VERSION ""

NS_ :

BS_:

BU_: NUC IPC VCU ADCU Mobileye Instrumentation Vehicle ESR
VAL_TABLE_ VtSIg_eventState_9 9 "caution-Conflicting-Traffic" 8 "protected-clearance : yellow" 7 "permissive-clearance" 6 "protected-Movement-Allowed" 5 "permissive-Movement-Allowed" 4 "pre-Movement : red+yellow partly" 3 "stop-And-Remain : red right" 2 "stop-Then-Proceed : flashing red" 1 "dark" 0 "unavailable" ;
VAL_TABLE_ VtSIg_eventState_8 9 "caution-Conflicting-Traffic" 8 "protected-clearance : yellow" 7 "permissive-clearance" 6 "protected-Movement-Allowed" 5 "permissive-Movement-Allowed" 4 "pre-Movement : red+yellow partly" 3 "stop-And-Remain : red right" 2 "stop-Then-Proceed : flashing red" 1 "dark" 0 "unavailable" ;
VAL_TABLE_ VtSIg_eventState_7 9 "caution-Conflicting-Traffic" 8 "protected-clearance : yellow" 7 "permissive-clearance" 6 "protected-Movement-Allowed" 5 "permissive-Movement-Allowed" 4 "pre-Movement : red+yellow partly" 3 "stop-And-Remain : red right" 2 "stop-Then-Proceed : flashing red" 1 "dark" 0 "unavailable" ;
VAL_TABLE_ VtSIg_eventState_6 9 "caution-Conflicting-Traffic" 8 "protected-clearance : yellow" 7 "permissive-clearance" 6 "protected-Movement-Allowed" 5 "permissive-Movement-Allowed" 4 "pre-Movement : red+yellow partly" 3 "stop-And-Remain : red right" 2 "stop-Then-Proceed : flashing red" 1 "dark" 0 "unavailable" ;
VAL_TABLE_ VtSIg_eventState_5 9 "caution-Conflicting-Traffic" 8 "protected-clearance : yellow" 7 "permissive-clearance" 6 "protected-Movement-Allowed" 5 "permissive-Movement-Allowed" 4 "pre-Movement : red+yellow partly" 3 "stop-And-Remain : red right" 2 "stop-Then-Proceed : flashing red" 1 "dark" 0 "unavailable" ;
VAL_TABLE_ VtSIg_eventState_4 9 "caution-Conflicting-Traffic" 8 "protected-clearance : yellow" 7 "permissive-clearance" 6 "protected-Movement-Allowed" 5 "permissive-Movement-Allowed" 4 "pre-Movement : red+yellow partly" 3 "stop-And-Remain : red right" 2 "stop-Then-Proceed : flashing red" 1 "dark" 0 "unavailable" ;
VAL_TABLE_ VtSIg_eventState_3 9 "caution-Conflicting-Traffic" 8 "protected-clearance : yellow" 7 "permissive-clearance" 6 "protected-Movement-Allowed" 5 "permissive-Movement-Allowed" 4 "pre-Movement : red+yellow partly" 3 "stop-And-Remain : red right" 2 "stop-Then-Proceed : flashing red" 1 "dark" 0 "unavailable" ;
VAL_TABLE_ VtSIg_eventState_2 9 "caution-Conflicting-Traffic" 8 "protected-clearance : yellow" 7 "permissive-clearance" 6 "protected-Movement-Allowed" 5 "permissive-Movement-Allowed" 4 "pre-Movement : red+yellow partly" 3 "stop-And-Remain : red right" 2 "stop-Then-Proceed : flashing red" 1 "dark" 0 "unavailable" ;
VAL_TABLE_ VtSIg_eventState_1 9 "caution-Conflicting-Traffic" 8 "protected-clearance : yellow" 7 "permissive-clearance" 6 "protected-Movement-Allowed" 5 "permissive-Movement-Allowed" 4 "pre-Movement : red+yellow partly" 3 "stop-And-Remain : red right" 2 "stop-Then-Proceed : flashing red" 1 "dark" 0 "unavailable" ;
VAL_TABLE_ Value_Table_Track_Status 7 "New Coasting Target" 6 "Invalid Coasting Target" 5 "Merged Target" 4 "Coasting Target" 3 "Updated Target" 2 "New Updated Target" 1 "New Target" 0 "No Target" ;

BO_ 1831 Near_LANE_Param_2: 8 NUC
 SG_ lane_coeffd : 32|32@1- (1,0) [-3.4E+038|3.4E+038] "" Vector__XXX
 SG_ lane_coeffc : 0|32@1- (0.0001,0) [-3.4E+038|3.4E+038] "" Vector__XXX

BO_ 1830 Near_LANE_Param_1: 8 NUC
 SG_ lane_coeffb : 32|32@1- (0.0001,0) [-3.4E+038|3.4E+038] "" Vector__XXX
 SG_ lane_coeffa : 0|32@1- (0.0001,0) [-3.4E+038|3.4E+038] "" Vector__XXX

BO_ 1824 LOCAL_MAP_INFO: 8 NUC
 SG_ look_at_signalGroupID : 0|4@1+ (1,0) [0|15] "" Vector__XXX
 SG_ look_at_IntersectionID : 4|4@1+ (1,0) [0|9] "" Vector__XXX
 SG_ NEXT_LINK_ID : 8|8@1+ (1,0) [0|255] "" Vector__XXX
 SG_ LINK_ID : 16|8@1+ (1,0) [0|255] "" Vector__XXX
 SG_ distance_to_lane_end : 24|16@1+ (0.1,0) [0|6553.5] "m" Vector__XXX
 SG_ have_to_LangeChange_left : 44|1@1+ (1,0) [0|1] "" Vector__XXX
 SG_ have_to_LangeChange_right : 45|1@1+ (1,0) [0|1] "" Vector__XXX
 SG_ left_LaneChange_avail : 46|1@1+ (1,0) [0|1] "" Vector__XXX
 SG_ right_LaneChange_avail : 47|1@1+ (1,0) [0|1] "" Vector__XXX
 SG_ Speed_Limit : 48|8@1+ (1,0) [0|255] "" Vector__XXX
 SG_ guard_zone : 50|2@1+ (1,0) [0|3] "" Vector__XXX

BO_ 64 On_ODD_Stat: 2 NUC
 SG_ distance_out_of_ODD : 8|8@1+ (1,0) [0|255] "m" Vector__XXX
 SG_ Road_State : 1|2@1+ (1,0) [0|3] "" Vector__XXX
 SG_ On_ODD : 0|1@1+ (1,0) [0|1] "" Vector__XXX

BO_ 777 V2X_SPaT_9: 4 NUC
 SG_ minEndTime_9 : 16|12@1+ (0.1,0) [0|4095] "" Vector__XXX
 SG_ eventState_9 : 12|4@1+ (1,0) [0|9] "" Vector__XXX
 SG_ movementName_9 : 8|4@1+ (1,0) [0|2] "" Vector__XXX
 SG_ signalGroup_9 : 4|4@1+ (1,0) [0|15] "" Vector__XXX
 SG_ Intersection_ID_9 : 0|4@1+ (1,0) [0|9] "" Vector__XXX

BO_ 776 V2X_SPaT_8: 4 NUC
 SG_ minEndTime_8 : 16|12@1+ (0.1,0) [0|4095] "" Vector__XXX
 SG_ eventState_8 : 12|4@1+ (1,0) [0|9] "" Vector__XXX
 SG_ movementName_8 : 8|4@1+ (1,0) [0|2] "" Vector__XXX
 SG_ signalGroup_8 : 4|4@1+ (1,0) [0|15] "" Vector__XXX
 SG_ Intersection_ID_8 : 0|4@1+ (1,0) [0|9] "" Vector__XXX

BO_ 775 V2X_SPaT_7: 4 NUC
 SG_ minEndTime_7 : 16|12@1+ (0.1,0) [0|4095] "" Vector__XXX
 SG_ eventState_7 : 12|4@1+ (1,0) [0|9] "" Vector__XXX
 SG_ movementName_7 : 8|4@1+ (1,0) [0|2] "" Vector__XXX
 SG_ signalGroup_7 : 4|4@1+ (1,0) [0|15] "" Vector__XXX
 SG_ Intersection_ID_7 : 0|4@1+ (1,0) [0|9] "" Vector__XXX

BO_ 774 V2X_SPaT_6: 4 NUC
 SG_ minEndTime_6 : 16|12@1+ (0.1,0) [0|4095] "" Vector__XXX
 SG_ eventState_6 : 12|4@1+ (1,0) [0|9] "" Vector__XXX
 SG_ movementName_6 : 8|4@1+ (1,0) [0|2] "" Vector__XXX
 SG_ signalGroup_6 : 4|4@1+ (1,0) [0|15] "" Vector__XXX
 SG_ Intersection_ID_6 : 0|4@1+ (1,0) [0|9] "" Vector__XXX

BO_ 773 V2X_SPaT_5: 4 NUC
 SG_ minEndTime_5 : 16|12@1+ (0.1,0) [0|4095] "" Vector__XXX
 SG_ eventState_5 : 12|4@1+ (1,0) [0|9] "" Vector__XXX
 SG_ movementName_5 : 8|4@1+ (1,0) [0|2] "" Vector__XXX
 SG_ signalGroup_5 : 4|4@1+ (1,0) [0|15] "" Vector__XXX
 SG_ Intersection_ID_5 : 0|4@1+ (1,0) [0|9] "" Vector__XXX

BO_ 772 V2X_SPaT_4: 4 NUC
 SG_ minEndTime_4 : 16|12@1+ (0.1,0) [0|4095] "" Vector__XXX
 SG_ movementName_4 : 8|4@1+ (1,0) [0|2] "" Vector__XXX
 SG_ eventState_4 : 12|4@1+ (1,0) [0|9] "" Vector__XXX
 SG_ signalGroup_4 : 4|4@1+ (1,0) [0|15] "" Vector__XXX
 SG_ Intersection_ID_4 : 0|4@1+ (1,0) [0|9] "" Vector__XXX

BO_ 771 V2X_SPaT_3: 4 NUC
 SG_ minEndTime_3 : 16|12@1+ (0.1,0) [0|4095] "" Vector__XXX
 SG_ eventState_3 : 12|4@1+ (1,0) [0|9] "" Vector__XXX
 SG_ movementName_3 : 8|4@1+ (1,0) [0|2] "" Vector__XXX
 SG_ signalGroup_3 : 4|4@1+ (1,0) [0|15] "" Vector__XXX
 SG_ Intersection_ID_3 : 0|4@1+ (1,0) [0|9] "" Vector__XXX

BO_ 770 V2X_SPaT_2: 4 NUC
 SG_ minEndTime_2 : 16|12@1+ (0.1,0) [0|4095] "" Vector__XXX
 SG_ eventState_2 : 12|4@1+ (1,0) [0|9] "" Vector__XXX
 SG_ movementName_2 : 8|4@1+ (1,0) [0|2] "" Vector__XXX
 SG_ signalGroup_2 : 4|4@1+ (1,0) [0|15] "" Vector__XXX
 SG_ Intersection_ID_2 : 0|4@1+ (1,0) [0|9] "" Vector__XXX

BO_ 769 V2X_SPaT_1: 4 NUC
 SG_ movementName_1 : 8|4@1+ (1,0) [0|2] "" Vector__XXX
 SG_ minEndTime_1 : 16|12@1+ (0.1,0) [0|4095] "" Vector__XXX
 SG_ eventState_1 : 12|4@1+ (1,0) [0|9] "" Vector__XXX
 SG_ signalGroup_1 : 4|4@1+ (1,0) [0|15] "" Vector__XXX
 SG_ Intersection_ID_1 : 0|4@1+ (1,0) [0|9] "" Vector__XXX

BO_ 276 CPT7_Longitude_Acc: 8 IPC
 SG_ cpt7_longAcc : 0|64@1- (1,0) [-1.7E+308|1.7E+308] "m/s^2" Vector__XXX

BO_ 1897 LKA_Right_Lane_B: 4 Mobileye
 SG_ View_Range_Availability : 31|1@1+ (1,0) [0|0] "" Vector__XXX
 SG_ View_Range : 16|15@1+ (0.00390625,0) [0|127.996] "m" Vector__XXX
 SG_ Heading_Angle : 0|16@1+ (0.000976562,-31.999) [-0.357|0.357] "radians" Vector__XXX

BO_ 1896 LKA_Right_Lane_A: 8 Mobileye
 SG_ Width_left_marking : 56|8@1+ (0.01,0) [0|2.5] "m" Vector__XXX
 SG_ Curvature_Derivative : 40|16@1+ (3.72529E-009,-0.000122067) [-0.00012|0.00012] "1/meter^2" Vector__XXX
 SG_ Curvature : 24|16@1+ (9.76563E-007,-0.031999) [-0.02|0.02] "1/m" Vector__XXX
 SG_ Position : 8|16@1- (0.00390625,0) [-128|127] "m" Vector__XXX
 SG_ Model_Degree : 6|2@1+ (1,0) [0|0] "" Vector__XXX
 SG_ Quality : 4|2@1+ (1,0) [0|0] "" Vector__XXX
 SG_ Lane_Type : 0|4@1+ (1,0) [0|15] "" Vector__XXX

BO_ 275 NMEA_Heading: 8 IPC
 SG_ nmea_heading : 0|64@1- (1,0) [0|359.99] "degree" Vector__XXX

BO_ 274 NMEA_Speed: 8 IPC
 SG_ nmea_speed : 0|64@1- (1,0) [-1.7E+308|1.7E+308] "km/h" Vector__XXX

BO_ 273 NMEA_Position_Lon: 8 IPC
 SG_ nmea_longitude : 0|64@1- (1,0) [-1.7E+308|1.7E+308] "degree" Vector__XXX

BO_ 272 NMEA_Position_Lat: 8 IPC
 SG_ nmea_latitude : 0|64@1- (1,0) [-1.7E+308|1.7E+308] "degree" Vector__XXX

BO_ 262 CPT7_Position_Yawrate: 8 IPC
 SG_ cpt7_yawrate : 0|64@1- (1,0) [-1.7E+308|1.7E+308] "radian/s" Vector__XXX

BO_ 261 CPT7_Position_Azimuth: 8 IPC
 SG_ cpt7_azimuth : 0|64@1- (1,0) [-1.7E+308|1.7E+308] "degree" Vector__XXX

BO_ 260 CPT7_Position_Heading: 4 IPC
 SG_ cpt7_heading : 0|32@1- (1,0) [-3.4E+038|3.4E+038] "degree" Vector__XXX

BO_ 259 CPT7_Position_East: 8 IPC
 SG_ cpt7_easting : 0|64@1- (1,0) [-1.7E+308|1.7E+308] "m" Vector__XXX

BO_ 258 CPT7_Position_North: 8 IPC
 SG_ cpt7_northing : 0|64@1- (1,0) [-1.7E+308|1.7E+308] "m" Vector__XXX

BO_ 257 CPT7_Position_Lon: 8 IPC
 SG_ cpt7_longitude : 0|64@1- (1,0) [-1.7E+308|1.7E+308] "degree" Vector__XXX

BO_ 256 CPT7_Position_Lat: 8 IPC
 SG_ cpt7_latitude : 0|64@1- (1,0) [-1.7E+308|1.7E+308] "" Vector__XXX

BO_ 103 DiagnosticCAM: 1 IPC
 SG_ Mobileye_AliveCnt : 0|8@1+ (1,0) [0|255] "" Vector__XXX

BO_ 102 DiagnosticRADAR: 1 IPC
 SG_ Radar_AliveCnt : 0|8@1+ (1,0) [0|255] "" Vector__XXX

BO_ 101 DiagnosticHMI: 2 IPC
 SG_ HMI_AliveCnt : 8|8@1+ (1,0) [0|255] "" Vector__XXX
 SG_ HMI_StatCode : 0|8@1+ (1,0) [0|15] "" Vector__XXX

BO_ 100 DiagnosticOBU: 2 IPC
 SG_ OBU_AliveCnt : 8|8@1+ (1,0) [0|255] "" Vector__XXX
 SG_ OBU_StatCode : 0|3@1+ (1,0) [0|7] "" Vector__XXX

BO_ 99 DiagnosticGPS: 3 IPC
 SG_ GPS_IMU_AliveCnt : 16|8@1+ (1,0) [0|255] "" Vector__XXX
 SG_ IMU_StatCode : 8|3@1+ (1,0) [0|7] "" Vector__XXX
 SG_ GPS_StatCode : 0|3@1+ (1,0) [0|7] "" Vector__XXX

BO_ 98 DiagnosticLiDAR: 3 IPC
 SG_ Left_Lidar_StatCode : 16|3@1+ (1,0) [0|7] "" Vector__XXX
 SG_ Right_Lidar_StatCode : 8|3@1+ (1,0) [0|7] "" Vector__XXX
 SG_ Center_Lidar_StatCode : 0|3@1+ (1,0) [0|7] "" Vector__XXX

BO_ 96 DiagnosticIPC: 2 IPC
 SG_ IPC_SWC_StatCode : 0|3@1+ (1,0) [0|7] "" Vector__XXX
 SG_ IPC_AliveCount : 8|8@1+ (1,0) [0|255] "" Vector__XXX

BO_ 97 DiagnosticADCU: 2 ADCU
 SG_ ADCU_AliveCount : 8|8@1+ (1,0) [0|255] "-" Vector__XXX
 SG_ ADCU_SWC_StatCode : 0|3@1+ (1,0) [0|7] "" Vector__XXX

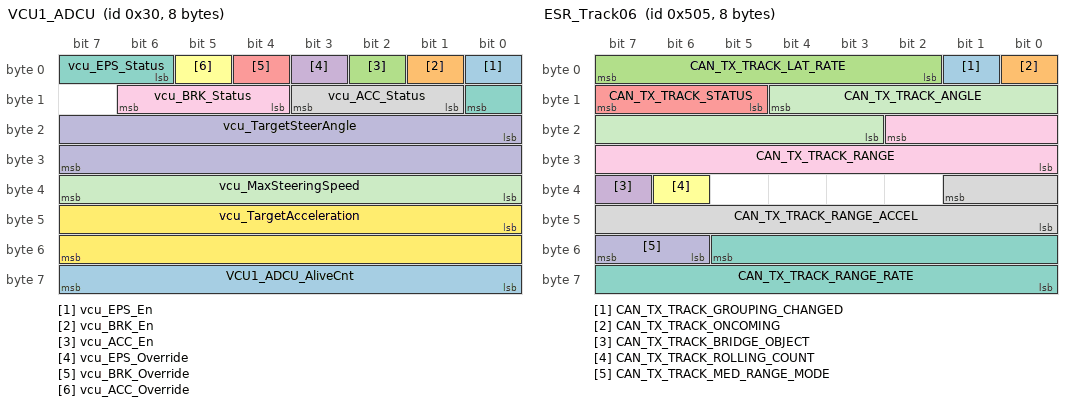
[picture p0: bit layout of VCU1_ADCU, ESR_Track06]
BO_ 48 VCU1_ADCU: 8 VCU
 SG_ vcu_EPS_En : 0|1@1+ (1,0) [0|1] "-"  ADCU
 SG_ vcu_BRK_En : 1|1@1+ (1,0) [0|1] "-"  ADCU
 SG_ vcu_ACC_En : 2|1@1+ (1,0) [0|1] "-"  ADCU
 SG_ vcu_EPS_Override : 3|1@1+ (1,0) [0|1] "-"  ADCU
 SG_ vcu_BRK_Override : 4|1@1+ (1,0) [0|1] "-"  ADCU
 SG_ vcu_ACC_Override : 5|1@1+ (1,0) [0|1] "-"  ADCU
 SG_ vcu_EPS_Status : 6|3@1+ (1,0) [0|7] "-"  ADCU
 SG_ vcu_ACC_Status : 9|3@1+ (1,0) [0|7] "-"  ADCU
 SG_ vcu_BRK_Status : 12|3@1+ (1,0) [0|7] "-"  ADCU
 SG_ vcu_TargetSteerAngle : 16|16@1- (0.1,0) [-3276.8|3276.7] "deg"  ADCU
 SG_ vcu_MaxSteeringSpeed : 32|8@1+ (4,0) [0|1016] "deg/s"  ADCU
 SG_ vcu_TargetAcceleration : 40|16@1+ (0.01,-10.23) [-10.23|10.24] "m/s^2"  ADCU
 SG_ VCU1_ADCU_AliveCnt : 56|8@1+ (1,0) [0|255] "-"  ADCU

BO_ 49 VCU2_ADCU: 8 VCU
 SG_ vcu_ADMDStatus : 0|1@1+ (1,0) [0|1] "-"  ADCU
 SG_ vcu_ADReady : 1|1@1+ (1,0) [0|1] "-"  ADCU
 SG_ vcu_Override : 2|1@1+ (1,0) [0|1] "-"  ADCU
 SG_ vcu_Estop : 3|1@1+ (1,0) [0|1] "-"  ADCU
 SG_ vcu_HazardCtl : 16|1@1+ (1,0) [0|1] "-"  ADCU
 SG_ vcu_LeftTurnCtl : 17|1@1+ (1,0) [0|1] "-"  ADCU
 SG_ vcu_RightTurnCtl : 18|1@1+ (1,0) [0|1] "-"  ADCU
 SG_ vcu_LeftTurnState : 24|1@1+ (1,0) [0|1] "-"  ADCU
 SG_ vcu_RightTurnState : 25|1@1+ (1,0) [0|1] "-"  ADCU
 SG_ vcu_VB : 32|8@1+ (0.125,0) [0|31.875] "V"  ADCU
 SG_ VCU2_ADCU_AliveCnt : 56|8@1+ (1,0) [0|255] "-"  ADCU

BO_ 50 VCU3_ADCU: 8 VCU
 SG_ vcu_APS : 0|8@1+ (0.4,0) [0|100] "%"  ADCU
 SG_ vcu_BPS : 8|8@1+ (0.4,0) [0|100] "%"  ADCU
 SG_ vcu_VS : 16|8@1+ (1,0) [0|255] "km/h"  ADCU
 SG_ vcu_SAS_Angle : 24|16@1- (0.1,0) [-3276.8|3276.7] "deg"  ADCU
 SG_ vcu_SAS_Speed : 40|8@1+ (4,0) [0|1016] "deg/s"  ADCU
 SG_ vcu_LONG_ACCEL : 48|16@1+ (0.01,-10.23) [-10.23|10.24] "m/s^2"  ADCU

BO_ 51 VCU4_ADCU: 8 VCU
 SG_ vcu_CANErr_ADCU : 0|1@1+ (1,0) [0|1] "-"  ADCU
 SG_ vcu_CANErr_LDWS : 1|1@1+ (1,0) [0|1] "-"  ADCU
 SG_ vcu_CANErr_AEB : 2|1@1+ (1,0) [0|1] "-"  ADCU
 SG_ vcu_CANErr_MDPS : 3|1@1+ (1,0) [0|1] "-"  ADCU
 SG_ vcu_CANErr_ESC : 4|1@1+ (1,0) [0|1] "-"  ADCU
 SG_ vcu_CANErr_ABS : 5|1@1+ (1,0) [0|1] "-"  ADCU
 SG_ vcu_CANErr_EMS : 6|1@1+ (1,0) [0|1] "-"  ADCU
 SG_ vcu_CANErr_BCM : 7|1@1+ (1,0) [0|1] "-"  ADCU
 SG_ vcu_CANErr_iBAU : 8|1@1+ (1,0) [0|1] "-"  ADCU
 SG_ vcu_CANErr_EPB : 9|1@1+ (1,0) [0|1] "-"  ADCU
 SG_ vcu_CANErr_CLU : 10|1@1+ (1,0) [0|1] "-"  ADCU
 SG_ vcu_CANErr_TPMS : 11|1@1+ (1,0) [0|1] "-"  ADCU
 SG_ vcu_CANErr_Autobox : 12|1@1+ (1,0) [0|1] "-"  ADCU
 SG_ vcu_CANErr_MobilEYE : 13|1@1+ (1,0) [0|1] "-"  ADCU
 SG_ vcu_CANErr_LiDAR : 14|1@1+ (1,0) [0|1] "-"  ADCU
 SG_ vcu_CANErr_Radar : 15|1@1+ (1,0) [0|1] "-"  ADCU
 SG_ vcu_CANErr_V2X : 16|1@1+ (1,0) [0|1] "-"  ADCU
 SG_ vcu_CANErr_GPS : 17|1@1+ (1,0) [0|1] "-"  ADCU
 SG_ vcu_CANErr_HMI : 18|1@1+ (1,0) [0|1] "-"  ADCU
 SG_ vcu_ERR_VCU : 32|1@1+ (1,0) [0|1] "-"  ADCU
 SG_ vcu_ERR_ADCU : 33|1@1+ (1,0) [0|1] "-"  ADCU
 SG_ vcu_ERR_LDWS : 34|1@1+ (1,0) [0|1] "-"  ADCU
 SG_ vcu_ERR_AEB : 35|1@1+ (1,0) [0|1] "-"  ADCU
 SG_ vcu_ERR_MDPS : 36|1@1+ (1,0) [0|1] "-"  ADCU
 SG_ vcu_ERR_ESC : 37|1@1+ (1,0) [0|1] "-"  ADCU
 SG_ vcu_ERR_EMS : 38|1@1+ (1,0) [0|1] "-"  ADCU
 SG_ vcu_ERR_BCM : 39|1@1+ (1,0) [0|1] "-"  ADCU
 SG_ vcu_ERR_iBAU : 40|1@1+ (1,0) [0|1] "-"  ADCU
 SG_ vcu_ERR_EPB : 41|1@1+ (1,0) [0|1] "-"  ADCU
 SG_ vcu_ERR_CLU : 42|1@1+ (1,0) [0|1] "-"  ADCU
 SG_ vcu_ERR_Autobox : 43|1@1+ (1,0) [0|1] "-"  ADCU
 SG_ vcu_ERR_MobilEYE : 44|1@1+ (1,0) [0|1] "-"  ADCU
 SG_ vcu_ERR_LiDAR : 45|1@1+ (1,0) [0|1] "-"  ADCU
 SG_ vcu_ERR_Radar : 46|1@1+ (1,0) [0|1] "-"  ADCU
 SG_ vcu_ERR_V2X : 47|1@1+ (1,0) [0|1] "-"  ADCU
 SG_ vcu_ERR_GPS : 48|1@1+ (1,0) [0|1] "-"  ADCU
 SG_ vcu_ERR_HMI : 49|1@1+ (1,0) [0|1] "-"  ADCU

BO_ 32 ADCU1: 8 ADCU
 SG_ adcu_Ready : 0|1@1+ (1,0) [0|1] "-"  VCU
 SG_ adcu_EPS_En : 1|1@1+ (1,0) [0|1] "-"  VCU
 SG_ adcu_BRK_En : 2|1@1+ (1,0) [0|1] "-"  VCU
 SG_ adcu_ACC_En : 3|1@1+ (1,0) [0|1] "-"  VCU
 SG_ adcu_SysFault : 4|1@1+ (1,0) [0|1] "-"  VCU
 SG_ adcu_DriverTakeover : 7|1@1+ (1,0) [0|1] "-"  VCU
 SG_ adcu_DriverWarning : 8|4@1+ (1,0) [0|15] "-"  VCU
 SG_ adcu_DesiredSteerAngle : 16|16@1- (0.1,0) [-3276.8|3276.7] "deg"  VCU
 SG_ adcu_MaxSteeringSpeed : 32|8@1+ (4,0) [0|1016] "deg/s"  VCU
 SG_ adcu_DesiredAcceleration : 40|16@1+ (0.01,-10.23) [-10.23|10.24] "m/s^2"  VCU
 SG_ ADCU1_AliveCnt : 56|8@1+ (1,0) [0|255] "-"  VCU

BO_ 33 ADCU2: 8 ADCU
 SG_ adcu_RunMode : 0|2@1+ (1,0) [0|3] "-"  VCU
 SG_ adcu_DrivingMode : 2|2@1+ (1,0) [0|3] "-"  VCU
 SG_ adcu_WaveLevel : 4|2@1+ (1,0) [0|3] "-"  VCU
 SG_ adcu_LTE5GLevel : 6|2@1+ (1,0) [0|3] "-"  VCU
 SG_ adcu_DesiredTimeGap : 8|16@1+ (0.01,0) [0|655.35] "sec"  VCU
 SG_ adcu_DesiredRD : 24|16@1+ (0.01,0) [0|655.35] "m"  VCU
 SG_ adcu_ActualRD : 40|16@1+ (0.01,0) [0|655.35] "m"  VCU
 SG_ ADCU2_AliveCnt : 56|8@1+ (1,0) [0|255] "-"  VCU

BO_ 34 ADCU3: 8 ADCU
 SG_ adcu_LaneDeparture : 0|2@1+ (1,0) [0|3] "-"  VCU
 SG_ adcu_VehFrt : 2|2@1+ (1,0) [0|3] "-"  VCU
 SG_ adcu_VehFL : 4|2@1+ (1,0) [0|3] "-"  VCU
 SG_ adcu_VehFR : 6|2@1+ (1,0) [0|3] "-"  VCU
 SG_ adcu_VehRL : 8|2@1+ (1,0) [0|3] "-"  VCU
 SG_ adcu_VehRR : 10|2@1+ (1,0) [0|3] "-"  VCU
 SG_ adcu_VehRear : 12|2@1+ (1,0) [0|3] "-"  VCU
 SG_ adcu_HazardLampCtl : 16|1@1+ (1,0) [0|1] "-"  VCU
 SG_ adcu_LeftTurnSigCtl : 17|1@1+ (1,0) [0|1] "-"  VCU
 SG_ adcu_RightTurnSigCtl : 18|1@1+ (1,0) [0|1] "-"  VCU
 SG_ ADCU3_AliveCnt : 56|8@1+ (1,0) [0|255] "-"  VCU

BO_ 1849 ObstacleDataA: 8 Mobileye
 SG_ ObstaclePositionX : 8|12@1+ (0.0625,0) [0|0] "m" Vector__XXX
 SG_ ObstaclePositionY : 24|10@1- (0.0625,0) [-31.93|31.93] "" Vector__XXX
 SG_ ObstacleRelSpd : 41|12@1- (0.0625,0) [-127.93|127.93] "m/s" Vector__XXX

BO_ 1850 ObstacleDataB: 8 Mobileye
 SG_ ObstacleLane : 24|2@1+ (1,0) [0|0] "" Vector__XXX

BO_ 1792 AWSDisplay: 8 Mobileye
 SG_ HeadwayMeasurement : 17|7@1+ (0.1,0) [0|0] "s" Vector__XXX

BO_ 1894 LKA_Left_Lane_A: 8 Mobileye
 SG_ Lane_Type : 0|4@1+ (1,0) [0|15] "" Vector__XXX
 SG_ Quality : 4|2@1+ (1,0) [0|0] "" Vector__XXX
 SG_ Model_Degree : 6|2@1+ (1,0) [0|0] "" Vector__XXX
 SG_ Position : 8|16@1- (0.00390625,0) [-128|127] "m" Vector__XXX
 SG_ Curvature : 24|16@1+ (9.76563E-007,-0.031999) [-0.02|0.02] "1/m" Vector__XXX
 SG_ Curvature_Derivative : 40|16@1+ (3.72529E-009,-0.000122067) [-0.00012|0.00012] "1/meter^2" Vector__XXX
 SG_ Width_left_marking : 56|8@1+ (0.01,0) [0|2.5] "m" Vector__XXX

BO_ 1895 LKA_Left_Lane_B: 4 Mobileye
 SG_ Heading_Angle : 0|16@1+ (0.000976562,-31.999) [-0.357|0.357] "radians" Vector__XXX
 SG_ View_Range : 16|15@1+ (0.00390625,0) [0|127.996] "m" Vector__XXX
 SG_ View_Range_Availability : 31|1@1+ (1,0) [0|0] "" Vector__XXX

BO_ 1512 ESR_Status9: 8 ESR
 SG_ CAN_TX_PATH_ID_ACC_3 : 63|8@0+ (1,0) [0|64] "" Vector__XXX
 SG_ CAN_TX_PATH_ID_ACC_2 : 55|8@0+ (1,0) [0|64] "" Vector__XXX
 SG_ CAN_TX_FILTERED_XOHP_ACC_CIPV : 32|9@0- (0.03125,0) [-8|7.96875] "m" Vector__XXX
 SG_ CAN_TX_WATER_SPRAY_TARGET_ID : 39|7@0+ (1,0) [0|64] "" Vector__XXX
 SG_ CAN_TX_SERIAL_NUM_3RD_BYTE : 31|8@0+ (1,0) [0|0] "" Vector__XXX
 SG_ CAN_TX_SIDESLIP_ANGLE : 9|10@0- (0.125,0) [-64|63.875] "deg" Vector__XXX
 SG_ CAN_TX_AVG_PWR_CWBLKG : 7|12@0+ (1,0) [0|0] "" Vector__XXX

BO_ 1285 ESR_Track06: 8 ESR
 SG_ CAN_TX_TRACK_GROUPING_CHANGED : 1|1@0+ (1,0) [0|0] "" Vector__XXX
 SG_ CAN_TX_TRACK_ONCOMING : 0|1@0+ (1,0) [0|0] "" Vector__XXX
 SG_ CAN_TX_TRACK_LAT_RATE : 7|6@0- (0.25,0) [-8|7.75] "" Vector__XXX
 SG_ CAN_TX_TRACK_BRIDGE_OBJECT : 39|1@0+ (1,0) [0|0] "" Vector__XXX
 SG_ CAN_TX_TRACK_STATUS : 15|3@0+ (1,0) [0|7] "" Vector__XXX
 SG_ CAN_TX_TRACK_ROLLING_COUNT : 38|1@0+ (1,0) [0|1] "" Vector__XXX
 SG_ CAN_TX_TRACK_RANGE_RATE : 53|14@0- (0.01,0) [-81.92|81.91] "m/s" Vector__XXX
 SG_ CAN_TX_TRACK_RANGE_ACCEL : 33|10@0- (0.05,0) [-25.6|25.55] "m/s/s" Vector__XXX
 SG_ CAN_TX_TRACK_RANGE : 18|11@0+ (0.1,0) [0|204.7] "m" Vector__XXX
 SG_ CAN_TX_TRACK_MED_RANGE_MODE : 55|2@0+ (1,0) [0|3] "" Vector__XXX
 SG_ CAN_TX_TRACK_ANGLE : 12|10@0- (0.1,0) [-51.2|51.1] "deg" Vector__XXX

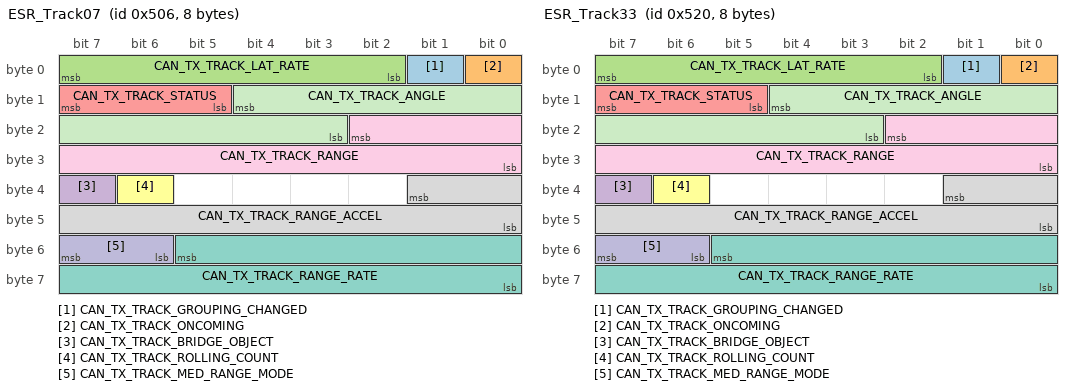
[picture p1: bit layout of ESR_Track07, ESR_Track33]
BO_ 1286 ESR_Track07: 8 ESR
 SG_ CAN_TX_TRACK_GROUPING_CHANGED : 1|1@0+ (1,0) [0|0] "" Vector__XXX
 SG_ CAN_TX_TRACK_ONCOMING : 0|1@0+ (1,0) [0|0] "" Vector__XXX
 SG_ CAN_TX_TRACK_LAT_RATE : 7|6@0- (0.25,0) [-8|7.75] "" Vector__XXX
 SG_ CAN_TX_TRACK_BRIDGE_OBJECT : 39|1@0+ (1,0) [0|0] "" Vector__XXX
 SG_ CAN_TX_TRACK_STATUS : 15|3@0+ (1,0) [0|7] "" Vector__XXX
 SG_ CAN_TX_TRACK_ROLLING_COUNT : 38|1@0+ (1,0) [0|1] "" Vector__XXX
 SG_ CAN_TX_TRACK_RANGE_RATE : 53|14@0- (0.01,0) [-81.92|81.91] "m/s" Vector__XXX
 SG_ CAN_TX_TRACK_RANGE_ACCEL : 33|10@0- (0.05,0) [-25.6|25.55] "m/s/s" Vector__XXX
 SG_ CAN_TX_TRACK_RANGE : 18|11@0+ (0.1,0) [0|204.7] "m" Vector__XXX
 SG_ CAN_TX_TRACK_MED_RANGE_MODE : 55|2@0+ (1,0) [0|3] "" Vector__XXX
 SG_ CAN_TX_TRACK_ANGLE : 12|10@0- (0.1,0) [-51.2|51.1] "deg" Vector__XXX

BO_ 1312 ESR_Track33: 8 ESR
 SG_ CAN_TX_TRACK_GROUPING_CHANGED : 1|1@0+ (1,0) [0|0] "" Vector__XXX
 SG_ CAN_TX_TRACK_ONCOMING : 0|1@0+ (1,0) [0|0] "" Vector__XXX
 SG_ CAN_TX_TRACK_LAT_RATE : 7|6@0- (0.25,0) [-8|7.75] "" Vector__XXX
 SG_ CAN_TX_TRACK_BRIDGE_OBJECT : 39|1@0+ (1,0) [0|0] "" Vector__XXX
 SG_ CAN_TX_TRACK_STATUS : 15|3@0+ (1,0) [0|7] "" Vector__XXX
 SG_ CAN_TX_TRACK_ROLLING_COUNT : 38|1@0+ (1,0) [0|1] "" Vector__XXX
 SG_ CAN_TX_TRACK_RANGE_RATE : 53|14@0- (0.01,0) [-81.92|81.91] "m/s" Vector__XXX
 SG_ CAN_TX_TRACK_RANGE_ACCEL : 33|10@0- (0.05,0) [-25.6|25.55] "m/s/s" Vector__XXX
 SG_ CAN_TX_TRACK_RANGE : 18|11@0+ (0.1,0) [0|204.7] "m" Vector__XXX
 SG_ CAN_TX_TRACK_MED_RANGE_MODE : 55|2@0+ (1,0) [0|3] "" Vector__XXX
 SG_ CAN_TX_TRACK_ANGLE : 12|10@0- (0.1,0) [-51.2|51.1] "deg" Vector__XXX

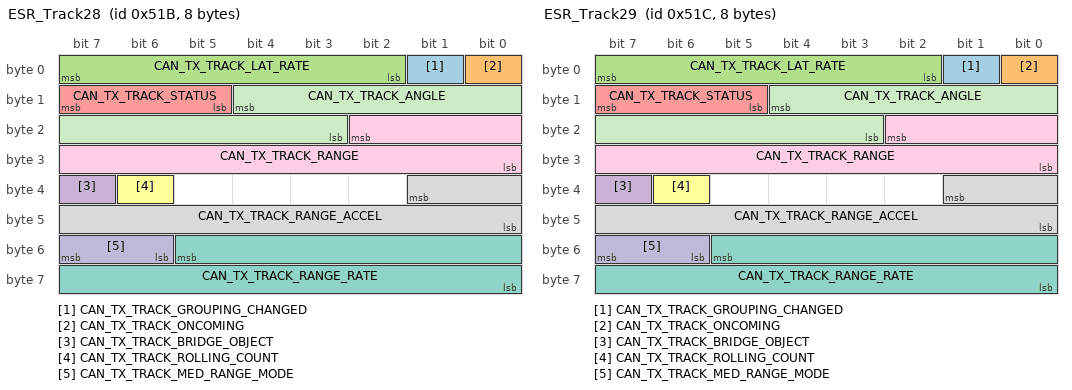
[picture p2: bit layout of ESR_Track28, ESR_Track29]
BO_ 1307 ESR_Track28: 8 ESR
 SG_ CAN_TX_TRACK_GROUPING_CHANGED : 1|1@0+ (1,0) [0|0] "" Vector__XXX
 SG_ CAN_TX_TRACK_ONCOMING : 0|1@0+ (1,0) [0|0] "" Vector__XXX
 SG_ CAN_TX_TRACK_LAT_RATE : 7|6@0- (0.25,0) [-8|7.75] "" Vector__XXX
 SG_ CAN_TX_TRACK_BRIDGE_OBJECT : 39|1@0+ (1,0) [0|0] "" Vector__XXX
 SG_ CAN_TX_TRACK_STATUS : 15|3@0+ (1,0) [0|7] "" Vector__XXX
 SG_ CAN_TX_TRACK_ROLLING_COUNT : 38|1@0+ (1,0) [0|1] "" Vector__XXX
 SG_ CAN_TX_TRACK_RANGE_RATE : 53|14@0- (0.01,0) [-81.92|81.91] "m/s" Vector__XXX
 SG_ CAN_TX_TRACK_RANGE_ACCEL : 33|10@0- (0.05,0) [-25.6|25.55] "m/s/s" Vector__XXX
 SG_ CAN_TX_TRACK_RANGE : 18|11@0+ (0.1,0) [0|204.7] "m" Vector__XXX
 SG_ CAN_TX_TRACK_MED_RANGE_MODE : 55|2@0+ (1,0) [0|3] "" Vector__XXX
 SG_ CAN_TX_TRACK_ANGLE : 12|10@0- (0.1,0) [-51.2|51.1] "deg" Vector__XXX

BO_ 1308 ESR_Track29: 8 ESR
 SG_ CAN_TX_TRACK_GROUPING_CHANGED : 1|1@0+ (1,0) [0|0] "" Vector__XXX
 SG_ CAN_TX_TRACK_ONCOMING : 0|1@0+ (1,0) [0|0] "" Vector__XXX
 SG_ CAN_TX_TRACK_LAT_RATE : 7|6@0- (0.25,0) [-8|7.75] "" Vector__XXX
 SG_ CAN_TX_TRACK_BRIDGE_OBJECT : 39|1@0+ (1,0) [0|0] "" Vector__XXX
 SG_ CAN_TX_TRACK_STATUS : 15|3@0+ (1,0) [0|7] "" Vector__XXX
 SG_ CAN_TX_TRACK_ROLLING_COUNT : 38|1@0+ (1,0) [0|1] "" Vector__XXX
 SG_ CAN_TX_TRACK_RANGE_RATE : 53|14@0- (0.01,0) [-81.92|81.91] "m/s" Vector__XXX
 SG_ CAN_TX_TRACK_RANGE_ACCEL : 33|10@0- (0.05,0) [-25.6|25.55] "m/s/s" Vector__XXX
 SG_ CAN_TX_TRACK_RANGE : 18|11@0+ (0.1,0) [0|204.7] "m" Vector__XXX
 SG_ CAN_TX_TRACK_MED_RANGE_MODE : 55|2@0+ (1,0) [0|3] "" Vector__XXX
 SG_ CAN_TX_TRACK_ANGLE : 12|10@0- (0.1,0) [-51.2|51.1] "deg" Vector__XXX

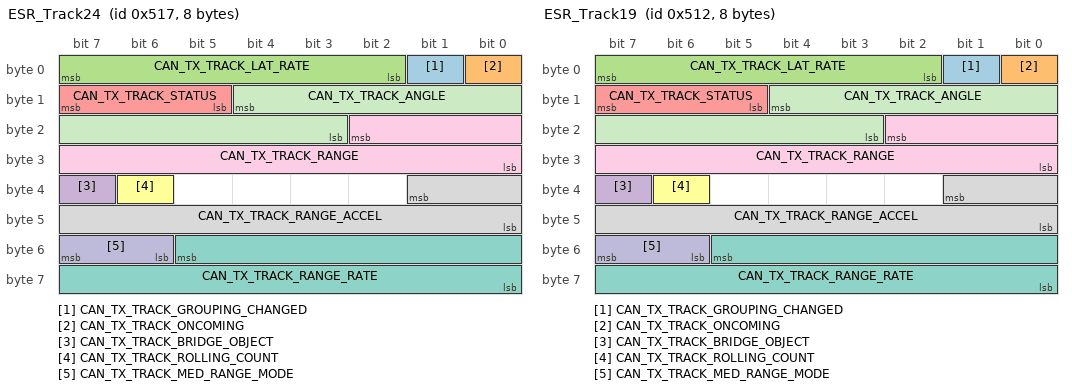
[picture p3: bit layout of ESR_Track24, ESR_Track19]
BO_ 1303 ESR_Track24: 8 ESR
 SG_ CAN_TX_TRACK_GROUPING_CHANGED : 1|1@0+ (1,0) [0|0] "" Vector__XXX
 SG_ CAN_TX_TRACK_ONCOMING : 0|1@0+ (1,0) [0|0] "" Vector__XXX
 SG_ CAN_TX_TRACK_LAT_RATE : 7|6@0- (0.25,0) [-8|7.75] "" Vector__XXX
 SG_ CAN_TX_TRACK_BRIDGE_OBJECT : 39|1@0+ (1,0) [0|0] "" Vector__XXX
 SG_ CAN_TX_TRACK_STATUS : 15|3@0+ (1,0) [0|7] "" Vector__XXX
 SG_ CAN_TX_TRACK_ROLLING_COUNT : 38|1@0+ (1,0) [0|1] "" Vector__XXX
 SG_ CAN_TX_TRACK_RANGE_RATE : 53|14@0- (0.01,0) [-81.92|81.91] "m/s" Vector__XXX
 SG_ CAN_TX_TRACK_RANGE_ACCEL : 33|10@0- (0.05,0) [-25.6|25.55] "m/s/s" Vector__XXX
 SG_ CAN_TX_TRACK_RANGE : 18|11@0+ (0.1,0) [0|204.7] "m" Vector__XXX
 SG_ CAN_TX_TRACK_MED_RANGE_MODE : 55|2@0+ (1,0) [0|3] "" Vector__XXX
 SG_ CAN_TX_TRACK_ANGLE : 12|10@0- (0.1,0) [-51.2|51.1] "deg" Vector__XXX

BO_ 1298 ESR_Track19: 8 ESR
 SG_ CAN_TX_TRACK_GROUPING_CHANGED : 1|1@0+ (1,0) [0|0] "" Vector__XXX
 SG_ CAN_TX_TRACK_ONCOMING : 0|1@0+ (1,0) [0|0] "" Vector__XXX
 SG_ CAN_TX_TRACK_LAT_RATE : 7|6@0- (0.25,0) [-8|7.75] "" Vector__XXX
 SG_ CAN_TX_TRACK_BRIDGE_OBJECT : 39|1@0+ (1,0) [0|0] "" Vector__XXX
 SG_ CAN_TX_TRACK_STATUS : 15|3@0+ (1,0) [0|7] "" Vector__XXX
 SG_ CAN_TX_TRACK_ROLLING_COUNT : 38|1@0+ (1,0) [0|1] "" Vector__XXX
 SG_ CAN_TX_TRACK_RANGE_RATE : 53|14@0- (0.01,0) [-81.92|81.91] "m/s" Vector__XXX
 SG_ CAN_TX_TRACK_RANGE_ACCEL : 33|10@0- (0.05,0) [-25.6|25.55] "m/s/s" Vector__XXX
 SG_ CAN_TX_TRACK_RANGE : 18|11@0+ (0.1,0) [0|204.7] "m" Vector__XXX
 SG_ CAN_TX_TRACK_MED_RANGE_MODE : 55|2@0+ (1,0) [0|3] "" Vector__XXX
 SG_ CAN_TX_TRACK_ANGLE : 12|10@0- (0.1,0) [-51.2|51.1] "deg" Vector__XXX

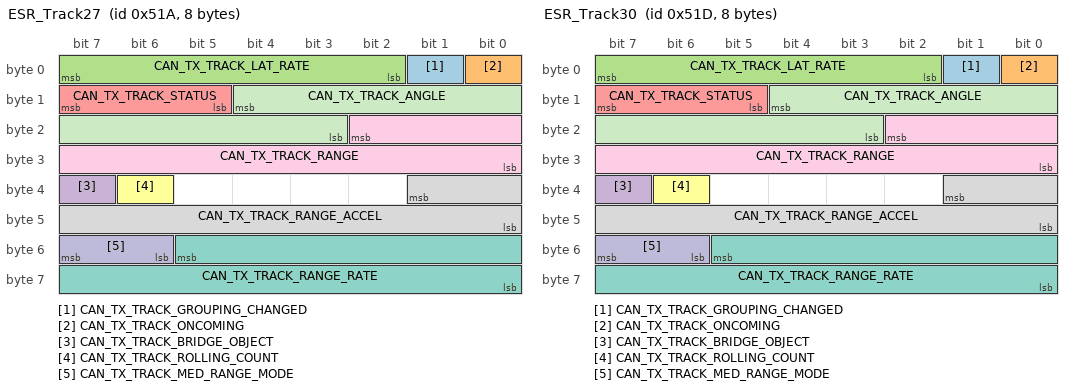
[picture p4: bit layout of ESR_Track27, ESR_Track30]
BO_ 1306 ESR_Track27: 8 ESR
 SG_ CAN_TX_TRACK_GROUPING_CHANGED : 1|1@0+ (1,0) [0|0] "" Vector__XXX
 SG_ CAN_TX_TRACK_ONCOMING : 0|1@0+ (1,0) [0|0] "" Vector__XXX
 SG_ CAN_TX_TRACK_LAT_RATE : 7|6@0- (0.25,0) [-8|7.75] "" Vector__XXX
 SG_ CAN_TX_TRACK_BRIDGE_OBJECT : 39|1@0+ (1,0) [0|0] "" Vector__XXX
 SG_ CAN_TX_TRACK_STATUS : 15|3@0+ (1,0) [0|7] "" Vector__XXX
 SG_ CAN_TX_TRACK_ROLLING_COUNT : 38|1@0+ (1,0) [0|1] "" Vector__XXX
 SG_ CAN_TX_TRACK_RANGE_RATE : 53|14@0- (0.01,0) [-81.92|81.91] "m/s" Vector__XXX
 SG_ CAN_TX_TRACK_RANGE_ACCEL : 33|10@0- (0.05,0) [-25.6|25.55] "m/s/s" Vector__XXX
 SG_ CAN_TX_TRACK_RANGE : 18|11@0+ (0.1,0) [0|204.7] "m" Vector__XXX
 SG_ CAN_TX_TRACK_MED_RANGE_MODE : 55|2@0+ (1,0) [0|3] "" Vector__XXX
 SG_ CAN_TX_TRACK_ANGLE : 12|10@0- (0.1,0) [-51.2|51.1] "deg" Vector__XXX

BO_ 1309 ESR_Track30: 8 ESR
 SG_ CAN_TX_TRACK_GROUPING_CHANGED : 1|1@0+ (1,0) [0|0] "" Vector__XXX
 SG_ CAN_TX_TRACK_ONCOMING : 0|1@0+ (1,0) [0|0] "" Vector__XXX
 SG_ CAN_TX_TRACK_LAT_RATE : 7|6@0- (0.25,0) [-8|7.75] "" Vector__XXX
 SG_ CAN_TX_TRACK_BRIDGE_OBJECT : 39|1@0+ (1,0) [0|0] "" Vector__XXX
 SG_ CAN_TX_TRACK_STATUS : 15|3@0+ (1,0) [0|7] "" Vector__XXX
 SG_ CAN_TX_TRACK_ROLLING_COUNT : 38|1@0+ (1,0) [0|1] "" Vector__XXX
 SG_ CAN_TX_TRACK_RANGE_RATE : 53|14@0- (0.01,0) [-81.92|81.91] "m/s" Vector__XXX
 SG_ CAN_TX_TRACK_RANGE_ACCEL : 33|10@0- (0.05,0) [-25.6|25.55] "m/s/s" Vector__XXX
 SG_ CAN_TX_TRACK_RANGE : 18|11@0+ (0.1,0) [0|204.7] "m" Vector__XXX
 SG_ CAN_TX_TRACK_MED_RANGE_MODE : 55|2@0+ (1,0) [0|3] "" Vector__XXX
 SG_ CAN_TX_TRACK_ANGLE : 12|10@0- (0.1,0) [-51.2|51.1] "deg" Vector__XXX

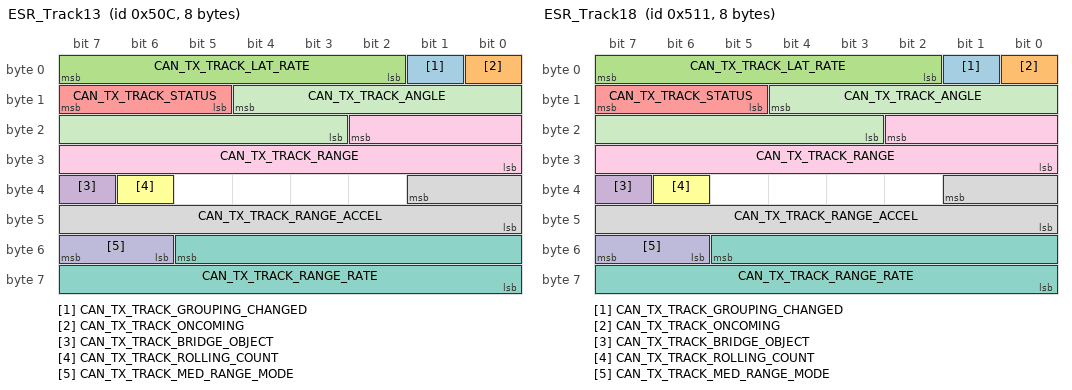
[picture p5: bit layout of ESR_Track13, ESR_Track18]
BO_ 1292 ESR_Track13: 8 ESR
 SG_ CAN_TX_TRACK_GROUPING_CHANGED : 1|1@0+ (1,0) [0|0] "" Vector__XXX
 SG_ CAN_TX_TRACK_ONCOMING : 0|1@0+ (1,0) [0|0] "" Vector__XXX
 SG_ CAN_TX_TRACK_LAT_RATE : 7|6@0- (0.25,0) [-8|7.75] "" Vector__XXX
 SG_ CAN_TX_TRACK_BRIDGE_OBJECT : 39|1@0+ (1,0) [0|0] "" Vector__XXX
 SG_ CAN_TX_TRACK_STATUS : 15|3@0+ (1,0) [0|7] "" Vector__XXX
 SG_ CAN_TX_TRACK_ROLLING_COUNT : 38|1@0+ (1,0) [0|1] "" Vector__XXX
 SG_ CAN_TX_TRACK_RANGE_RATE : 53|14@0- (0.01,0) [-81.92|81.91] "m/s" Vector__XXX
 SG_ CAN_TX_TRACK_RANGE_ACCEL : 33|10@0- (0.05,0) [-25.6|25.55] "m/s/s" Vector__XXX
 SG_ CAN_TX_TRACK_RANGE : 18|11@0+ (0.1,0) [0|204.7] "m" Vector__XXX
 SG_ CAN_TX_TRACK_MED_RANGE_MODE : 55|2@0+ (1,0) [0|3] "" Vector__XXX
 SG_ CAN_TX_TRACK_ANGLE : 12|10@0- (0.1,0) [-51.2|51.1] "deg" Vector__XXX

BO_ 1297 ESR_Track18: 8 ESR
 SG_ CAN_TX_TRACK_GROUPING_CHANGED : 1|1@0+ (1,0) [0|0] "" Vector__XXX
 SG_ CAN_TX_TRACK_ONCOMING : 0|1@0+ (1,0) [0|0] "" Vector__XXX
 SG_ CAN_TX_TRACK_LAT_RATE : 7|6@0- (0.25,0) [-8|7.75] "" Vector__XXX
 SG_ CAN_TX_TRACK_BRIDGE_OBJECT : 39|1@0+ (1,0) [0|0] "" Vector__XXX
 SG_ CAN_TX_TRACK_STATUS : 15|3@0+ (1,0) [0|7] "" Vector__XXX
 SG_ CAN_TX_TRACK_ROLLING_COUNT : 38|1@0+ (1,0) [0|1] "" Vector__XXX
 SG_ CAN_TX_TRACK_RANGE_RATE : 53|14@0- (0.01,0) [-81.92|81.91] "m/s" Vector__XXX
 SG_ CAN_TX_TRACK_RANGE_ACCEL : 33|10@0- (0.05,0) [-25.6|25.55] "m/s/s" Vector__XXX
 SG_ CAN_TX_TRACK_RANGE : 18|11@0+ (0.1,0) [0|204.7] "m" Vector__XXX
 SG_ CAN_TX_TRACK_MED_RANGE_MODE : 55|2@0+ (1,0) [0|3] "" Vector__XXX
 SG_ CAN_TX_TRACK_ANGLE : 12|10@0- (0.1,0) [-51.2|51.1] "deg" Vector__XXX

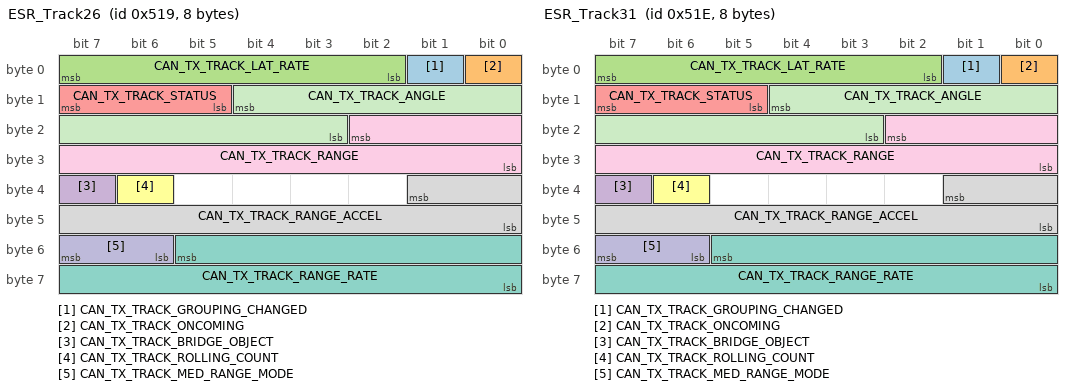
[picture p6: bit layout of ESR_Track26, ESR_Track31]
BO_ 1305 ESR_Track26: 8 ESR
 SG_ CAN_TX_TRACK_GROUPING_CHANGED : 1|1@0+ (1,0) [0|0] "" Vector__XXX
 SG_ CAN_TX_TRACK_ONCOMING : 0|1@0+ (1,0) [0|0] "" Vector__XXX
 SG_ CAN_TX_TRACK_LAT_RATE : 7|6@0- (0.25,0) [-8|7.75] "" Vector__XXX
 SG_ CAN_TX_TRACK_BRIDGE_OBJECT : 39|1@0+ (1,0) [0|0] "" Vector__XXX
 SG_ CAN_TX_TRACK_STATUS : 15|3@0+ (1,0) [0|7] "" Vector__XXX
 SG_ CAN_TX_TRACK_ROLLING_COUNT : 38|1@0+ (1,0) [0|1] "" Vector__XXX
 SG_ CAN_TX_TRACK_RANGE_RATE : 53|14@0- (0.01,0) [-81.92|81.91] "m/s" Vector__XXX
 SG_ CAN_TX_TRACK_RANGE_ACCEL : 33|10@0- (0.05,0) [-25.6|25.55] "m/s/s" Vector__XXX
 SG_ CAN_TX_TRACK_RANGE : 18|11@0+ (0.1,0) [0|204.7] "m" Vector__XXX
 SG_ CAN_TX_TRACK_MED_RANGE_MODE : 55|2@0+ (1,0) [0|3] "" Vector__XXX
 SG_ CAN_TX_TRACK_ANGLE : 12|10@0- (0.1,0) [-51.2|51.1] "deg" Vector__XXX

BO_ 1310 ESR_Track31: 8 ESR
 SG_ CAN_TX_TRACK_GROUPING_CHANGED : 1|1@0+ (1,0) [0|0] "" Vector__XXX
 SG_ CAN_TX_TRACK_ONCOMING : 0|1@0+ (1,0) [0|0] "" Vector__XXX
 SG_ CAN_TX_TRACK_LAT_RATE : 7|6@0- (0.25,0) [-8|7.75] "" Vector__XXX
 SG_ CAN_TX_TRACK_BRIDGE_OBJECT : 39|1@0+ (1,0) [0|0] "" Vector__XXX
 SG_ CAN_TX_TRACK_STATUS : 15|3@0+ (1,0) [0|7] "" Vector__XXX
 SG_ CAN_TX_TRACK_ROLLING_COUNT : 38|1@0+ (1,0) [0|1] "" Vector__XXX
 SG_ CAN_TX_TRACK_RANGE_RATE : 53|14@0- (0.01,0) [-81.92|81.91] "m/s" Vector__XXX
 SG_ CAN_TX_TRACK_RANGE_ACCEL : 33|10@0- (0.05,0) [-25.6|25.55] "m/s/s" Vector__XXX
 SG_ CAN_TX_TRACK_RANGE : 18|11@0+ (0.1,0) [0|204.7] "m" Vector__XXX
 SG_ CAN_TX_TRACK_MED_RANGE_MODE : 55|2@0+ (1,0) [0|3] "" Vector__XXX
 SG_ CAN_TX_TRACK_ANGLE : 12|10@0- (0.1,0) [-51.2|51.1] "deg" Vector__XXX

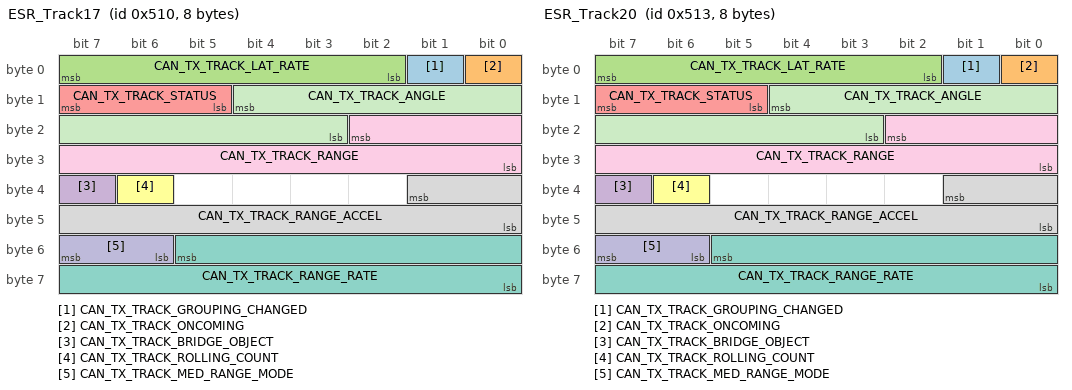
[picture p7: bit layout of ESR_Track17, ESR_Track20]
BO_ 1296 ESR_Track17: 8 ESR
 SG_ CAN_TX_TRACK_GROUPING_CHANGED : 1|1@0+ (1,0) [0|0] "" Vector__XXX
 SG_ CAN_TX_TRACK_ONCOMING : 0|1@0+ (1,0) [0|0] "" Vector__XXX
 SG_ CAN_TX_TRACK_LAT_RATE : 7|6@0- (0.25,0) [-8|7.75] "" Vector__XXX
 SG_ CAN_TX_TRACK_BRIDGE_OBJECT : 39|1@0+ (1,0) [0|0] "" Vector__XXX
 SG_ CAN_TX_TRACK_STATUS : 15|3@0+ (1,0) [0|7] "" Vector__XXX
 SG_ CAN_TX_TRACK_ROLLING_COUNT : 38|1@0+ (1,0) [0|1] "" Vector__XXX
 SG_ CAN_TX_TRACK_RANGE_RATE : 53|14@0- (0.01,0) [-81.92|81.91] "m/s" Vector__XXX
 SG_ CAN_TX_TRACK_RANGE_ACCEL : 33|10@0- (0.05,0) [-25.6|25.55] "m/s/s" Vector__XXX
 SG_ CAN_TX_TRACK_RANGE : 18|11@0+ (0.1,0) [0|204.7] "m" Vector__XXX
 SG_ CAN_TX_TRACK_MED_RANGE_MODE : 55|2@0+ (1,0) [0|3] "" Vector__XXX
 SG_ CAN_TX_TRACK_ANGLE : 12|10@0- (0.1,0) [-51.2|51.1] "deg" Vector__XXX

BO_ 1299 ESR_Track20: 8 ESR
 SG_ CAN_TX_TRACK_GROUPING_CHANGED : 1|1@0+ (1,0) [0|0] "" Vector__XXX
 SG_ CAN_TX_TRACK_ONCOMING : 0|1@0+ (1,0) [0|0] "" Vector__XXX
 SG_ CAN_TX_TRACK_LAT_RATE : 7|6@0- (0.25,0) [-8|7.75] "" Vector__XXX
 SG_ CAN_TX_TRACK_BRIDGE_OBJECT : 39|1@0+ (1,0) [0|0] "" Vector__XXX
 SG_ CAN_TX_TRACK_STATUS : 15|3@0+ (1,0) [0|7] "" Vector__XXX
 SG_ CAN_TX_TRACK_ROLLING_COUNT : 38|1@0+ (1,0) [0|1] "" Vector__XXX
 SG_ CAN_TX_TRACK_RANGE_RATE : 53|14@0- (0.01,0) [-81.92|81.91] "m/s" Vector__XXX
 SG_ CAN_TX_TRACK_RANGE_ACCEL : 33|10@0- (0.05,0) [-25.6|25.55] "m/s/s" Vector__XXX
 SG_ CAN_TX_TRACK_RANGE : 18|11@0+ (0.1,0) [0|204.7] "m" Vector__XXX
 SG_ CAN_TX_TRACK_MED_RANGE_MODE : 55|2@0+ (1,0) [0|3] "" Vector__XXX
 SG_ CAN_TX_TRACK_ANGLE : 12|10@0- (0.1,0) [-51.2|51.1] "deg" Vector__XXX

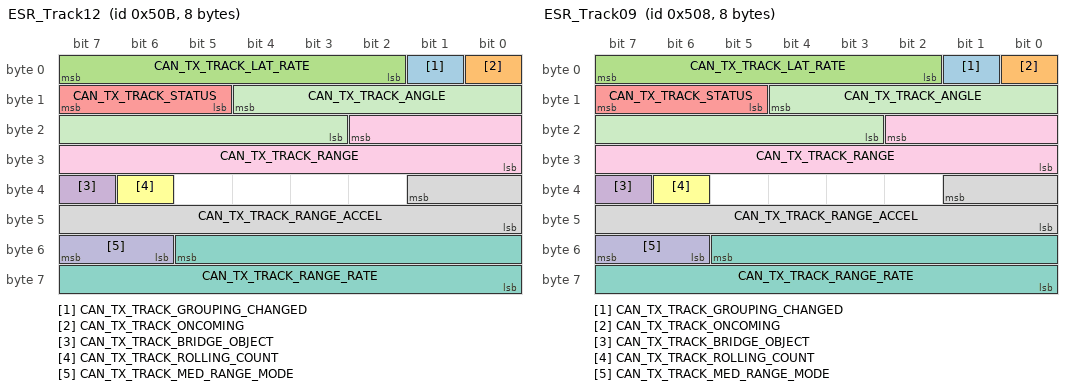
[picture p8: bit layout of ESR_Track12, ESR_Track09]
BO_ 1291 ESR_Track12: 8 ESR
 SG_ CAN_TX_TRACK_GROUPING_CHANGED : 1|1@0+ (1,0) [0|0] "" Vector__XXX
 SG_ CAN_TX_TRACK_ONCOMING : 0|1@0+ (1,0) [0|0] "" Vector__XXX
 SG_ CAN_TX_TRACK_LAT_RATE : 7|6@0- (0.25,0) [-8|7.75] "" Vector__XXX
 SG_ CAN_TX_TRACK_BRIDGE_OBJECT : 39|1@0+ (1,0) [0|0] "" Vector__XXX
 SG_ CAN_TX_TRACK_STATUS : 15|3@0+ (1,0) [0|7] "" Vector__XXX
 SG_ CAN_TX_TRACK_ROLLING_COUNT : 38|1@0+ (1,0) [0|1] "" Vector__XXX
 SG_ CAN_TX_TRACK_RANGE_RATE : 53|14@0- (0.01,0) [-81.92|81.91] "m/s" Vector__XXX
 SG_ CAN_TX_TRACK_RANGE_ACCEL : 33|10@0- (0.05,0) [-25.6|25.55] "m/s/s" Vector__XXX
 SG_ CAN_TX_TRACK_RANGE : 18|11@0+ (0.1,0) [0|204.7] "m" Vector__XXX
 SG_ CAN_TX_TRACK_MED_RANGE_MODE : 55|2@0+ (1,0) [0|3] "" Vector__XXX
 SG_ CAN_TX_TRACK_ANGLE : 12|10@0- (0.1,0) [-51.2|51.1] "deg" Vector__XXX

BO_ 1288 ESR_Track09: 8 ESR
 SG_ CAN_TX_TRACK_GROUPING_CHANGED : 1|1@0+ (1,0) [0|0] "" Vector__XXX
 SG_ CAN_TX_TRACK_ONCOMING : 0|1@0+ (1,0) [0|0] "" Vector__XXX
 SG_ CAN_TX_TRACK_LAT_RATE : 7|6@0- (0.25,0) [-8|7.75] "" Vector__XXX
 SG_ CAN_TX_TRACK_BRIDGE_OBJECT : 39|1@0+ (1,0) [0|0] "" Vector__XXX
 SG_ CAN_TX_TRACK_STATUS : 15|3@0+ (1,0) [0|7] "" Vector__XXX
 SG_ CAN_TX_TRACK_ROLLING_COUNT : 38|1@0+ (1,0) [0|1] "" Vector__XXX
 SG_ CAN_TX_TRACK_RANGE_RATE : 53|14@0- (0.01,0) [-81.92|81.91] "m/s" Vector__XXX
 SG_ CAN_TX_TRACK_RANGE_ACCEL : 33|10@0- (0.05,0) [-25.6|25.55] "m/s/s" Vector__XXX
 SG_ CAN_TX_TRACK_RANGE : 18|11@0+ (0.1,0) [0|204.7] "m" Vector__XXX
 SG_ CAN_TX_TRACK_MED_RANGE_MODE : 55|2@0+ (1,0) [0|3] "" Vector__XXX
 SG_ CAN_TX_TRACK_ANGLE : 12|10@0- (0.1,0) [-51.2|51.1] "deg" Vector__XXX

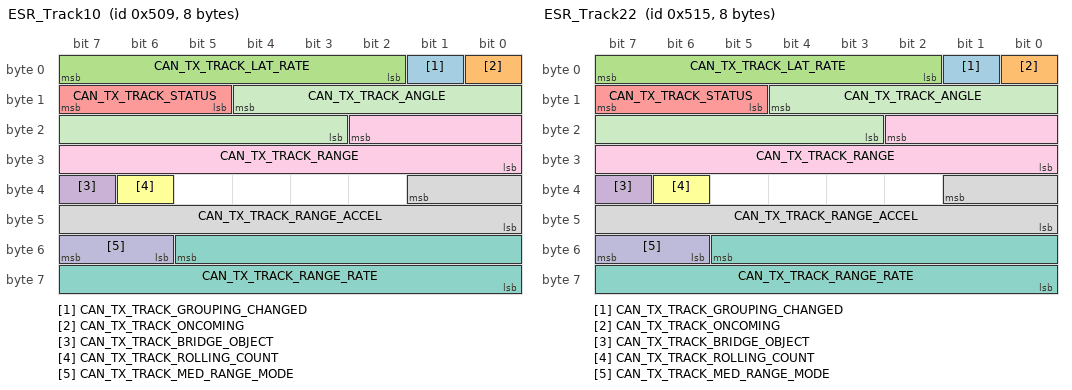
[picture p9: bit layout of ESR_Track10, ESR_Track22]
BO_ 1289 ESR_Track10: 8 ESR
 SG_ CAN_TX_TRACK_GROUPING_CHANGED : 1|1@0+ (1,0) [0|0] "" Vector__XXX
 SG_ CAN_TX_TRACK_ONCOMING : 0|1@0+ (1,0) [0|0] "" Vector__XXX
 SG_ CAN_TX_TRACK_LAT_RATE : 7|6@0- (0.25,0) [-8|7.75] "" Vector__XXX
 SG_ CAN_TX_TRACK_BRIDGE_OBJECT : 39|1@0+ (1,0) [0|0] "" Vector__XXX
 SG_ CAN_TX_TRACK_STATUS : 15|3@0+ (1,0) [0|7] "" Vector__XXX
 SG_ CAN_TX_TRACK_ROLLING_COUNT : 38|1@0+ (1,0) [0|1] "" Vector__XXX
 SG_ CAN_TX_TRACK_RANGE_RATE : 53|14@0- (0.01,0) [-81.92|81.91] "m/s" Vector__XXX
 SG_ CAN_TX_TRACK_RANGE_ACCEL : 33|10@0- (0.05,0) [-25.6|25.55] "m/s/s" Vector__XXX
 SG_ CAN_TX_TRACK_RANGE : 18|11@0+ (0.1,0) [0|204.7] "m" Vector__XXX
 SG_ CAN_TX_TRACK_MED_RANGE_MODE : 55|2@0+ (1,0) [0|3] "" Vector__XXX
 SG_ CAN_TX_TRACK_ANGLE : 12|10@0- (0.1,0) [-51.2|51.1] "deg" Vector__XXX

BO_ 1301 ESR_Track22: 8 ESR
 SG_ CAN_TX_TRACK_GROUPING_CHANGED : 1|1@0+ (1,0) [0|0] "" Vector__XXX
 SG_ CAN_TX_TRACK_ONCOMING : 0|1@0+ (1,0) [0|0] "" Vector__XXX
 SG_ CAN_TX_TRACK_LAT_RATE : 7|6@0- (0.25,0) [-8|7.75] "" Vector__XXX
 SG_ CAN_TX_TRACK_BRIDGE_OBJECT : 39|1@0+ (1,0) [0|0] "" Vector__XXX
 SG_ CAN_TX_TRACK_STATUS : 15|3@0+ (1,0) [0|7] "" Vector__XXX
 SG_ CAN_TX_TRACK_ROLLING_COUNT : 38|1@0+ (1,0) [0|1] "" Vector__XXX
 SG_ CAN_TX_TRACK_RANGE_RATE : 53|14@0- (0.01,0) [-81.92|81.91] "m/s" Vector__XXX
 SG_ CAN_TX_TRACK_RANGE_ACCEL : 33|10@0- (0.05,0) [-25.6|25.55] "m/s/s" Vector__XXX
 SG_ CAN_TX_TRACK_RANGE : 18|11@0+ (0.1,0) [0|204.7] "m" Vector__XXX
 SG_ CAN_TX_TRACK_MED_RANGE_MODE : 55|2@0+ (1,0) [0|3] "" Vector__XXX
 SG_ CAN_TX_TRACK_ANGLE : 12|10@0- (0.1,0) [-51.2|51.1] "deg" Vector__XXX

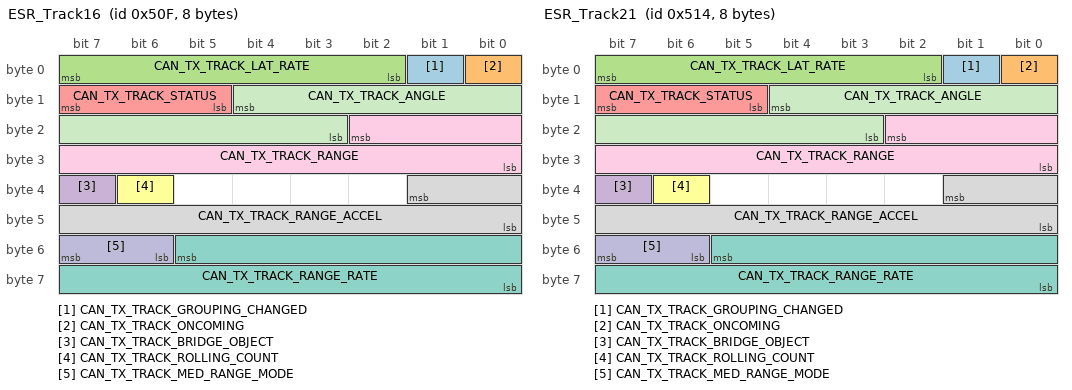
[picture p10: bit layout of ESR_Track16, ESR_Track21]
BO_ 1295 ESR_Track16: 8 ESR
 SG_ CAN_TX_TRACK_GROUPING_CHANGED : 1|1@0+ (1,0) [0|0] "" Vector__XXX
 SG_ CAN_TX_TRACK_ONCOMING : 0|1@0+ (1,0) [0|0] "" Vector__XXX
 SG_ CAN_TX_TRACK_LAT_RATE : 7|6@0- (0.25,0) [-8|7.75] "" Vector__XXX
 SG_ CAN_TX_TRACK_BRIDGE_OBJECT : 39|1@0+ (1,0) [0|0] "" Vector__XXX
 SG_ CAN_TX_TRACK_STATUS : 15|3@0+ (1,0) [0|7] "" Vector__XXX
 SG_ CAN_TX_TRACK_ROLLING_COUNT : 38|1@0+ (1,0) [0|1] "" Vector__XXX
 SG_ CAN_TX_TRACK_RANGE_RATE : 53|14@0- (0.01,0) [-81.92|81.91] "m/s" Vector__XXX
 SG_ CAN_TX_TRACK_RANGE_ACCEL : 33|10@0- (0.05,0) [-25.6|25.55] "m/s/s" Vector__XXX
 SG_ CAN_TX_TRACK_RANGE : 18|11@0+ (0.1,0) [0|204.7] "m" Vector__XXX
 SG_ CAN_TX_TRACK_MED_RANGE_MODE : 55|2@0+ (1,0) [0|3] "" Vector__XXX
 SG_ CAN_TX_TRACK_ANGLE : 12|10@0- (0.1,0) [-51.2|51.1] "deg" Vector__XXX

BO_ 1300 ESR_Track21: 8 ESR
 SG_ CAN_TX_TRACK_GROUPING_CHANGED : 1|1@0+ (1,0) [0|0] "" Vector__XXX
 SG_ CAN_TX_TRACK_ONCOMING : 0|1@0+ (1,0) [0|0] "" Vector__XXX
 SG_ CAN_TX_TRACK_LAT_RATE : 7|6@0- (0.25,0) [-8|7.75] "" Vector__XXX
 SG_ CAN_TX_TRACK_BRIDGE_OBJECT : 39|1@0+ (1,0) [0|0] "" Vector__XXX
 SG_ CAN_TX_TRACK_STATUS : 15|3@0+ (1,0) [0|7] "" Vector__XXX
 SG_ CAN_TX_TRACK_ROLLING_COUNT : 38|1@0+ (1,0) [0|1] "" Vector__XXX
 SG_ CAN_TX_TRACK_RANGE_RATE : 53|14@0- (0.01,0) [-81.92|81.91] "m/s" Vector__XXX
 SG_ CAN_TX_TRACK_RANGE_ACCEL : 33|10@0- (0.05,0) [-25.6|25.55] "m/s/s" Vector__XXX
 SG_ CAN_TX_TRACK_RANGE : 18|11@0+ (0.1,0) [0|204.7] "m" Vector__XXX
 SG_ CAN_TX_TRACK_MED_RANGE_MODE : 55|2@0+ (1,0) [0|3] "" Vector__XXX
 SG_ CAN_TX_TRACK_ANGLE : 12|10@0- (0.1,0) [-51.2|51.1] "deg" Vector__XXX

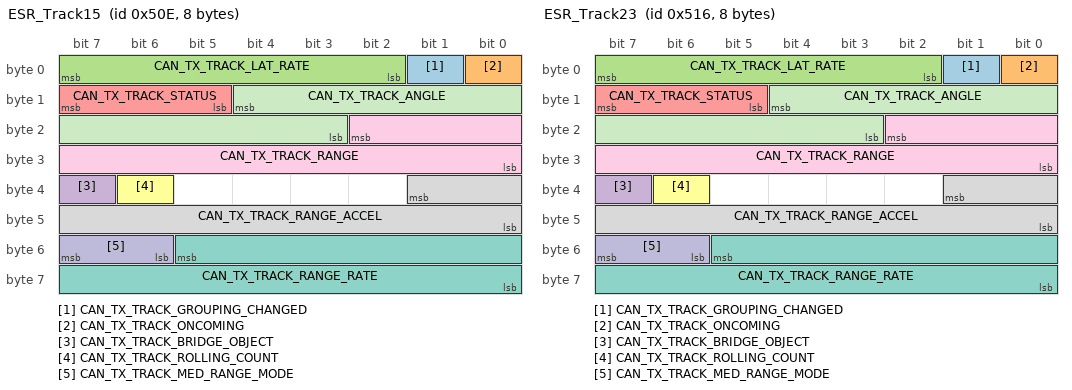
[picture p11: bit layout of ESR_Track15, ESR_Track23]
BO_ 1294 ESR_Track15: 8 ESR
 SG_ CAN_TX_TRACK_GROUPING_CHANGED : 1|1@0+ (1,0) [0|0] "" Vector__XXX
 SG_ CAN_TX_TRACK_ONCOMING : 0|1@0+ (1,0) [0|0] "" Vector__XXX
 SG_ CAN_TX_TRACK_LAT_RATE : 7|6@0- (0.25,0) [-8|7.75] "" Vector__XXX
 SG_ CAN_TX_TRACK_BRIDGE_OBJECT : 39|1@0+ (1,0) [0|0] "" Vector__XXX
 SG_ CAN_TX_TRACK_STATUS : 15|3@0+ (1,0) [0|7] "" Vector__XXX
 SG_ CAN_TX_TRACK_ROLLING_COUNT : 38|1@0+ (1,0) [0|1] "" Vector__XXX
 SG_ CAN_TX_TRACK_RANGE_RATE : 53|14@0- (0.01,0) [-81.92|81.91] "m/s" Vector__XXX
 SG_ CAN_TX_TRACK_RANGE_ACCEL : 33|10@0- (0.05,0) [-25.6|25.55] "m/s/s" Vector__XXX
 SG_ CAN_TX_TRACK_RANGE : 18|11@0+ (0.1,0) [0|204.7] "m" Vector__XXX
 SG_ CAN_TX_TRACK_MED_RANGE_MODE : 55|2@0+ (1,0) [0|3] "" Vector__XXX
 SG_ CAN_TX_TRACK_ANGLE : 12|10@0- (0.1,0) [-51.2|51.1] "deg" Vector__XXX

BO_ 1302 ESR_Track23: 8 ESR
 SG_ CAN_TX_TRACK_GROUPING_CHANGED : 1|1@0+ (1,0) [0|0] "" Vector__XXX
 SG_ CAN_TX_TRACK_ONCOMING : 0|1@0+ (1,0) [0|0] "" Vector__XXX
 SG_ CAN_TX_TRACK_LAT_RATE : 7|6@0- (0.25,0) [-8|7.75] "" Vector__XXX
 SG_ CAN_TX_TRACK_BRIDGE_OBJECT : 39|1@0+ (1,0) [0|0] "" Vector__XXX
 SG_ CAN_TX_TRACK_STATUS : 15|3@0+ (1,0) [0|7] "" Vector__XXX
 SG_ CAN_TX_TRACK_ROLLING_COUNT : 38|1@0+ (1,0) [0|1] "" Vector__XXX
 SG_ CAN_TX_TRACK_RANGE_RATE : 53|14@0- (0.01,0) [-81.92|81.91] "m/s" Vector__XXX
 SG_ CAN_TX_TRACK_RANGE_ACCEL : 33|10@0- (0.05,0) [-25.6|25.55] "m/s/s" Vector__XXX
 SG_ CAN_TX_TRACK_RANGE : 18|11@0+ (0.1,0) [0|204.7] "m" Vector__XXX
 SG_ CAN_TX_TRACK_MED_RANGE_MODE : 55|2@0+ (1,0) [0|3] "" Vector__XXX
 SG_ CAN_TX_TRACK_ANGLE : 12|10@0- (0.1,0) [-51.2|51.1] "deg" Vector__XXX

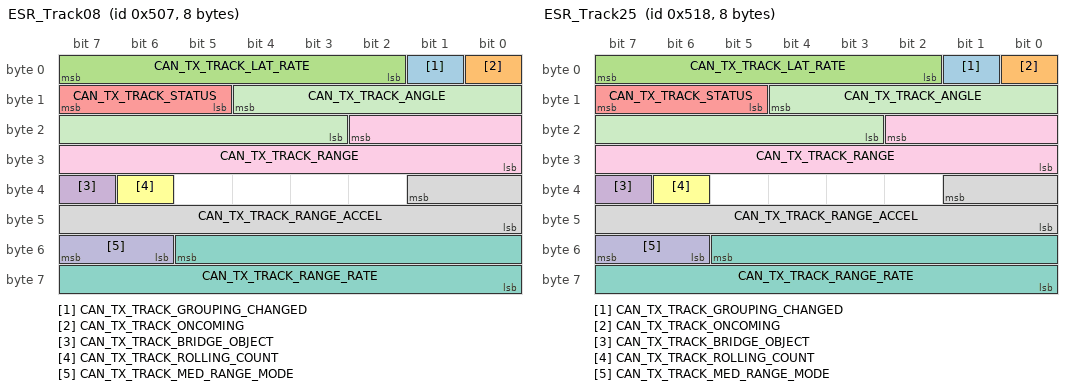
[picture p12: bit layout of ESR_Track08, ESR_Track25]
BO_ 1287 ESR_Track08: 8 ESR
 SG_ CAN_TX_TRACK_GROUPING_CHANGED : 1|1@0+ (1,0) [0|0] "" Vector__XXX
 SG_ CAN_TX_TRACK_ONCOMING : 0|1@0+ (1,0) [0|0] "" Vector__XXX
 SG_ CAN_TX_TRACK_LAT_RATE : 7|6@0- (0.25,0) [-8|7.75] "" Vector__XXX
 SG_ CAN_TX_TRACK_BRIDGE_OBJECT : 39|1@0+ (1,0) [0|0] "" Vector__XXX
 SG_ CAN_TX_TRACK_STATUS : 15|3@0+ (1,0) [0|7] "" Vector__XXX
 SG_ CAN_TX_TRACK_ROLLING_COUNT : 38|1@0+ (1,0) [0|1] "" Vector__XXX
 SG_ CAN_TX_TRACK_RANGE_RATE : 53|14@0- (0.01,0) [-81.92|81.91] "m/s" Vector__XXX
 SG_ CAN_TX_TRACK_RANGE_ACCEL : 33|10@0- (0.05,0) [-25.6|25.55] "m/s/s" Vector__XXX
 SG_ CAN_TX_TRACK_RANGE : 18|11@0+ (0.1,0) [0|204.7] "m" Vector__XXX
 SG_ CAN_TX_TRACK_MED_RANGE_MODE : 55|2@0+ (1,0) [0|3] "" Vector__XXX
 SG_ CAN_TX_TRACK_ANGLE : 12|10@0- (0.1,0) [-51.2|51.1] "deg" Vector__XXX

BO_ 1304 ESR_Track25: 8 ESR
 SG_ CAN_TX_TRACK_GROUPING_CHANGED : 1|1@0+ (1,0) [0|0] "" Vector__XXX
 SG_ CAN_TX_TRACK_ONCOMING : 0|1@0+ (1,0) [0|0] "" Vector__XXX
 SG_ CAN_TX_TRACK_LAT_RATE : 7|6@0- (0.25,0) [-8|7.75] "" Vector__XXX
 SG_ CAN_TX_TRACK_BRIDGE_OBJECT : 39|1@0+ (1,0) [0|0] "" Vector__XXX
 SG_ CAN_TX_TRACK_STATUS : 15|3@0+ (1,0) [0|7] "" Vector__XXX
 SG_ CAN_TX_TRACK_ROLLING_COUNT : 38|1@0+ (1,0) [0|1] "" Vector__XXX
 SG_ CAN_TX_TRACK_RANGE_RATE : 53|14@0- (0.01,0) [-81.92|81.91] "m/s" Vector__XXX
 SG_ CAN_TX_TRACK_RANGE_ACCEL : 33|10@0- (0.05,0) [-25.6|25.55] "m/s/s" Vector__XXX
 SG_ CAN_TX_TRACK_RANGE : 18|11@0+ (0.1,0) [0|204.7] "m" Vector__XXX
 SG_ CAN_TX_TRACK_MED_RANGE_MODE : 55|2@0+ (1,0) [0|3] "" Vector__XXX
 SG_ CAN_TX_TRACK_ANGLE : 12|10@0- (0.1,0) [-51.2|51.1] "deg" Vector__XXX

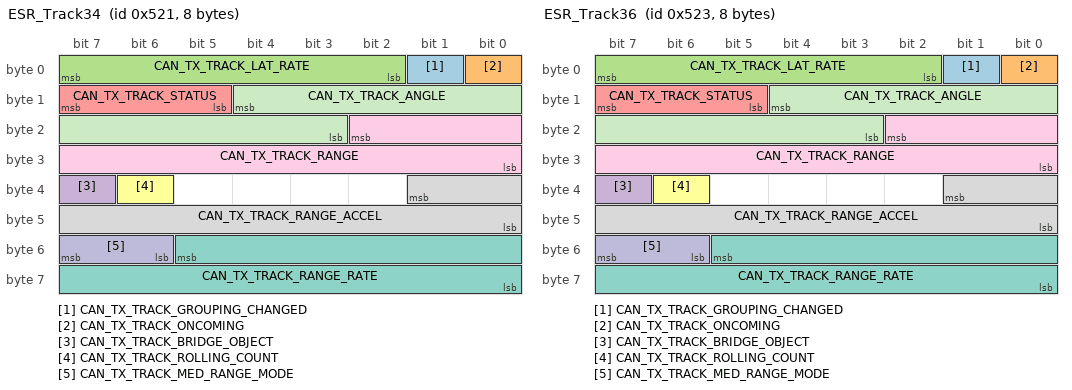
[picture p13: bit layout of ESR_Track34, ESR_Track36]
BO_ 1313 ESR_Track34: 8 ESR
 SG_ CAN_TX_TRACK_GROUPING_CHANGED : 1|1@0+ (1,0) [0|0] "" Vector__XXX
 SG_ CAN_TX_TRACK_ONCOMING : 0|1@0+ (1,0) [0|0] "" Vector__XXX
 SG_ CAN_TX_TRACK_LAT_RATE : 7|6@0- (0.25,0) [-8|7.75] "" Vector__XXX
 SG_ CAN_TX_TRACK_BRIDGE_OBJECT : 39|1@0+ (1,0) [0|0] "" Vector__XXX
 SG_ CAN_TX_TRACK_STATUS : 15|3@0+ (1,0) [0|7] "" Vector__XXX
 SG_ CAN_TX_TRACK_ROLLING_COUNT : 38|1@0+ (1,0) [0|1] "" Vector__XXX
 SG_ CAN_TX_TRACK_RANGE_RATE : 53|14@0- (0.01,0) [-81.92|81.91] "m/s" Vector__XXX
 SG_ CAN_TX_TRACK_RANGE_ACCEL : 33|10@0- (0.05,0) [-25.6|25.55] "m/s/s" Vector__XXX
 SG_ CAN_TX_TRACK_RANGE : 18|11@0+ (0.1,0) [0|204.7] "m" Vector__XXX
 SG_ CAN_TX_TRACK_MED_RANGE_MODE : 55|2@0+ (1,0) [0|3] "" Vector__XXX
 SG_ CAN_TX_TRACK_ANGLE : 12|10@0- (0.1,0) [-51.2|51.1] "deg" Vector__XXX

BO_ 1315 ESR_Track36: 8 ESR
 SG_ CAN_TX_TRACK_GROUPING_CHANGED : 1|1@0+ (1,0) [0|0] "" Vector__XXX
 SG_ CAN_TX_TRACK_ONCOMING : 0|1@0+ (1,0) [0|0] "" Vector__XXX
 SG_ CAN_TX_TRACK_LAT_RATE : 7|6@0- (0.25,0) [-8|7.75] "" Vector__XXX
 SG_ CAN_TX_TRACK_BRIDGE_OBJECT : 39|1@0+ (1,0) [0|0] "" Vector__XXX
 SG_ CAN_TX_TRACK_STATUS : 15|3@0+ (1,0) [0|7] "" Vector__XXX
 SG_ CAN_TX_TRACK_ROLLING_COUNT : 38|1@0+ (1,0) [0|1] "" Vector__XXX
 SG_ CAN_TX_TRACK_RANGE_RATE : 53|14@0- (0.01,0) [-81.92|81.91] "m/s" Vector__XXX
 SG_ CAN_TX_TRACK_RANGE_ACCEL : 33|10@0- (0.05,0) [-25.6|25.55] "m/s/s" Vector__XXX
 SG_ CAN_TX_TRACK_RANGE : 18|11@0+ (0.1,0) [0|204.7] "m" Vector__XXX
 SG_ CAN_TX_TRACK_MED_RANGE_MODE : 55|2@0+ (1,0) [0|3] "" Vector__XXX
 SG_ CAN_TX_TRACK_ANGLE : 12|10@0- (0.1,0) [-51.2|51.1] "deg" Vector__XXX

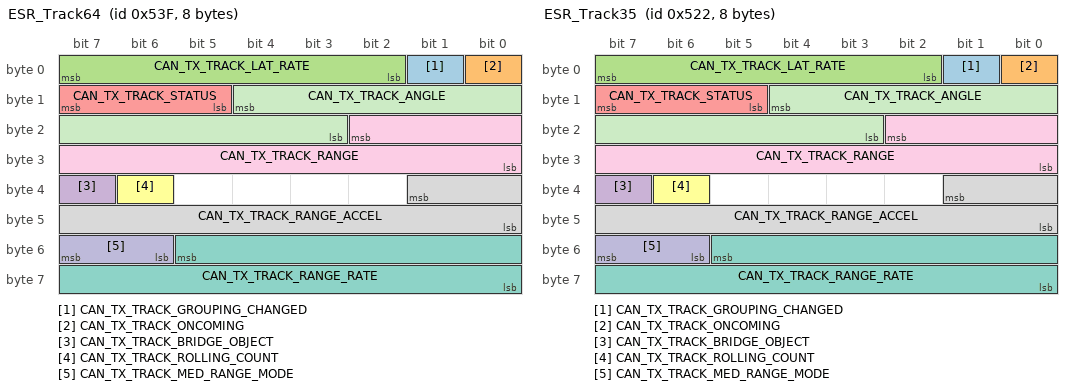
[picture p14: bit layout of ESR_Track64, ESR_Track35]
BO_ 1343 ESR_Track64: 8 ESR
 SG_ CAN_TX_TRACK_GROUPING_CHANGED : 1|1@0+ (1,0) [0|0] "" Vector__XXX
 SG_ CAN_TX_TRACK_ONCOMING : 0|1@0+ (1,0) [0|0] "" Vector__XXX
 SG_ CAN_TX_TRACK_LAT_RATE : 7|6@0- (0.25,0) [-8|7.75] "" Vector__XXX
 SG_ CAN_TX_TRACK_BRIDGE_OBJECT : 39|1@0+ (1,0) [0|0] "" Vector__XXX
 SG_ CAN_TX_TRACK_STATUS : 15|3@0+ (1,0) [0|7] "" Vector__XXX
 SG_ CAN_TX_TRACK_ROLLING_COUNT : 38|1@0+ (1,0) [0|1] "" Vector__XXX
 SG_ CAN_TX_TRACK_RANGE_RATE : 53|14@0- (0.01,0) [-81.92|81.91] "m/s" Vector__XXX
 SG_ CAN_TX_TRACK_RANGE_ACCEL : 33|10@0- (0.05,0) [-25.6|25.55] "m/s/s" Vector__XXX
 SG_ CAN_TX_TRACK_RANGE : 18|11@0+ (0.1,0) [0|204.7] "m" Vector__XXX
 SG_ CAN_TX_TRACK_MED_RANGE_MODE : 55|2@0+ (1,0) [0|3] "" Vector__XXX
 SG_ CAN_TX_TRACK_ANGLE : 12|10@0- (0.1,0) [-51.2|51.1] "deg" Vector__XXX

BO_ 1314 ESR_Track35: 8 ESR
 SG_ CAN_TX_TRACK_GROUPING_CHANGED : 1|1@0+ (1,0) [0|0] "" Vector__XXX
 SG_ CAN_TX_TRACK_ONCOMING : 0|1@0+ (1,0) [0|0] "" Vector__XXX
 SG_ CAN_TX_TRACK_LAT_RATE : 7|6@0- (0.25,0) [-8|7.75] "" Vector__XXX
 SG_ CAN_TX_TRACK_BRIDGE_OBJECT : 39|1@0+ (1,0) [0|0] "" Vector__XXX
 SG_ CAN_TX_TRACK_STATUS : 15|3@0+ (1,0) [0|7] "" Vector__XXX
 SG_ CAN_TX_TRACK_ROLLING_COUNT : 38|1@0+ (1,0) [0|1] "" Vector__XXX
 SG_ CAN_TX_TRACK_RANGE_RATE : 53|14@0- (0.01,0) [-81.92|81.91] "m/s" Vector__XXX
 SG_ CAN_TX_TRACK_RANGE_ACCEL : 33|10@0- (0.05,0) [-25.6|25.55] "m/s/s" Vector__XXX
 SG_ CAN_TX_TRACK_RANGE : 18|11@0+ (0.1,0) [0|204.7] "m" Vector__XXX
 SG_ CAN_TX_TRACK_MED_RANGE_MODE : 55|2@0+ (1,0) [0|3] "" Vector__XXX
 SG_ CAN_TX_TRACK_ANGLE : 12|10@0- (0.1,0) [-51.2|51.1] "deg" Vector__XXX

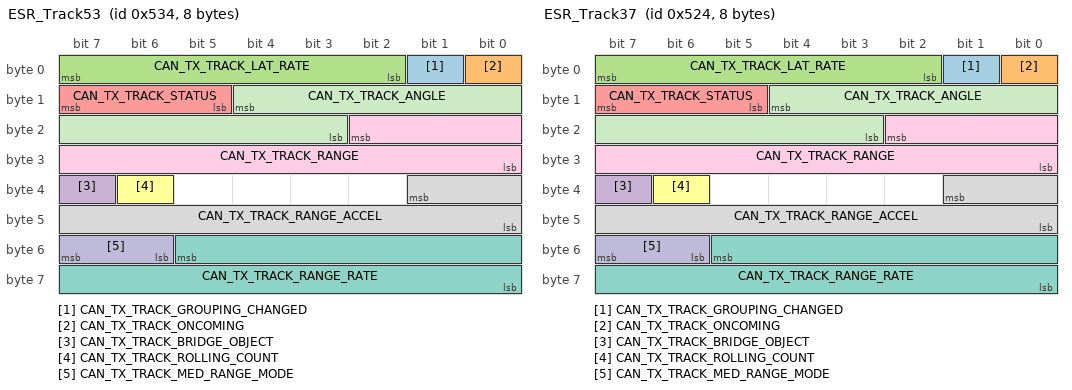
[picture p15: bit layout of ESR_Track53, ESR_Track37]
BO_ 1332 ESR_Track53: 8 ESR
 SG_ CAN_TX_TRACK_GROUPING_CHANGED : 1|1@0+ (1,0) [0|0] "" Vector__XXX
 SG_ CAN_TX_TRACK_ONCOMING : 0|1@0+ (1,0) [0|0] "" Vector__XXX
 SG_ CAN_TX_TRACK_LAT_RATE : 7|6@0- (0.25,0) [-8|7.75] "" Vector__XXX
 SG_ CAN_TX_TRACK_BRIDGE_OBJECT : 39|1@0+ (1,0) [0|0] "" Vector__XXX
 SG_ CAN_TX_TRACK_STATUS : 15|3@0+ (1,0) [0|7] "" Vector__XXX
 SG_ CAN_TX_TRACK_ROLLING_COUNT : 38|1@0+ (1,0) [0|1] "" Vector__XXX
 SG_ CAN_TX_TRACK_RANGE_RATE : 53|14@0- (0.01,0) [-81.92|81.91] "m/s" Vector__XXX
 SG_ CAN_TX_TRACK_RANGE_ACCEL : 33|10@0- (0.05,0) [-25.6|25.55] "m/s/s" Vector__XXX
 SG_ CAN_TX_TRACK_RANGE : 18|11@0+ (0.1,0) [0|204.7] "m" Vector__XXX
 SG_ CAN_TX_TRACK_MED_RANGE_MODE : 55|2@0+ (1,0) [0|3] "" Vector__XXX
 SG_ CAN_TX_TRACK_ANGLE : 12|10@0- (0.1,0) [-51.2|51.1] "deg" Vector__XXX

BO_ 1316 ESR_Track37: 8 ESR
 SG_ CAN_TX_TRACK_GROUPING_CHANGED : 1|1@0+ (1,0) [0|0] "" Vector__XXX
 SG_ CAN_TX_TRACK_ONCOMING : 0|1@0+ (1,0) [0|0] "" Vector__XXX
 SG_ CAN_TX_TRACK_LAT_RATE : 7|6@0- (0.25,0) [-8|7.75] "" Vector__XXX
 SG_ CAN_TX_TRACK_BRIDGE_OBJECT : 39|1@0+ (1,0) [0|0] "" Vector__XXX
 SG_ CAN_TX_TRACK_STATUS : 15|3@0+ (1,0) [0|7] "" Vector__XXX
 SG_ CAN_TX_TRACK_ROLLING_COUNT : 38|1@0+ (1,0) [0|1] "" Vector__XXX
 SG_ CAN_TX_TRACK_RANGE_RATE : 53|14@0- (0.01,0) [-81.92|81.91] "m/s" Vector__XXX
 SG_ CAN_TX_TRACK_RANGE_ACCEL : 33|10@0- (0.05,0) [-25.6|25.55] "m/s/s" Vector__XXX
 SG_ CAN_TX_TRACK_RANGE : 18|11@0+ (0.1,0) [0|204.7] "m" Vector__XXX
 SG_ CAN_TX_TRACK_MED_RANGE_MODE : 55|2@0+ (1,0) [0|3] "" Vector__XXX
 SG_ CAN_TX_TRACK_ANGLE : 12|10@0- (0.1,0) [-51.2|51.1] "deg" Vector__XXX

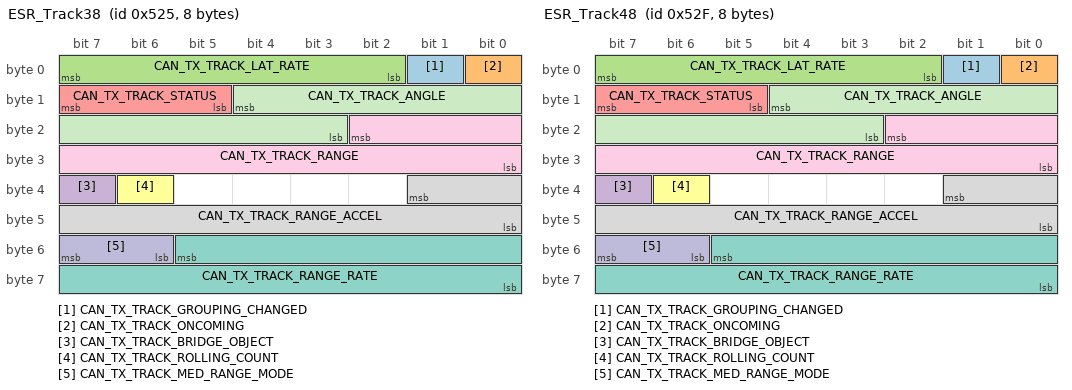
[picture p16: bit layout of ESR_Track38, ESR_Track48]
BO_ 1317 ESR_Track38: 8 ESR
 SG_ CAN_TX_TRACK_GROUPING_CHANGED : 1|1@0+ (1,0) [0|0] "" Vector__XXX
 SG_ CAN_TX_TRACK_ONCOMING : 0|1@0+ (1,0) [0|0] "" Vector__XXX
 SG_ CAN_TX_TRACK_LAT_RATE : 7|6@0- (0.25,0) [-8|7.75] "" Vector__XXX
 SG_ CAN_TX_TRACK_BRIDGE_OBJECT : 39|1@0+ (1,0) [0|0] "" Vector__XXX
 SG_ CAN_TX_TRACK_STATUS : 15|3@0+ (1,0) [0|7] "" Vector__XXX
 SG_ CAN_TX_TRACK_ROLLING_COUNT : 38|1@0+ (1,0) [0|1] "" Vector__XXX
 SG_ CAN_TX_TRACK_RANGE_RATE : 53|14@0- (0.01,0) [-81.92|81.91] "m/s" Vector__XXX
 SG_ CAN_TX_TRACK_RANGE_ACCEL : 33|10@0- (0.05,0) [-25.6|25.55] "m/s/s" Vector__XXX
 SG_ CAN_TX_TRACK_RANGE : 18|11@0+ (0.1,0) [0|204.7] "m" Vector__XXX
 SG_ CAN_TX_TRACK_MED_RANGE_MODE : 55|2@0+ (1,0) [0|3] "" Vector__XXX
 SG_ CAN_TX_TRACK_ANGLE : 12|10@0- (0.1,0) [-51.2|51.1] "deg" Vector__XXX

BO_ 1327 ESR_Track48: 8 ESR
 SG_ CAN_TX_TRACK_GROUPING_CHANGED : 1|1@0+ (1,0) [0|0] "" Vector__XXX
 SG_ CAN_TX_TRACK_ONCOMING : 0|1@0+ (1,0) [0|0] "" Vector__XXX
 SG_ CAN_TX_TRACK_LAT_RATE : 7|6@0- (0.25,0) [-8|7.75] "" Vector__XXX
 SG_ CAN_TX_TRACK_BRIDGE_OBJECT : 39|1@0+ (1,0) [0|0] "" Vector__XXX
 SG_ CAN_TX_TRACK_STATUS : 15|3@0+ (1,0) [0|7] "" Vector__XXX
 SG_ CAN_TX_TRACK_ROLLING_COUNT : 38|1@0+ (1,0) [0|1] "" Vector__XXX
 SG_ CAN_TX_TRACK_RANGE_RATE : 53|14@0- (0.01,0) [-81.92|81.91] "m/s" Vector__XXX
 SG_ CAN_TX_TRACK_RANGE_ACCEL : 33|10@0- (0.05,0) [-25.6|25.55] "m/s/s" Vector__XXX
 SG_ CAN_TX_TRACK_RANGE : 18|11@0+ (0.1,0) [0|204.7] "m" Vector__XXX
 SG_ CAN_TX_TRACK_MED_RANGE_MODE : 55|2@0+ (1,0) [0|3] "" Vector__XXX
 SG_ CAN_TX_TRACK_ANGLE : 12|10@0- (0.1,0) [-51.2|51.1] "deg" Vector__XXX

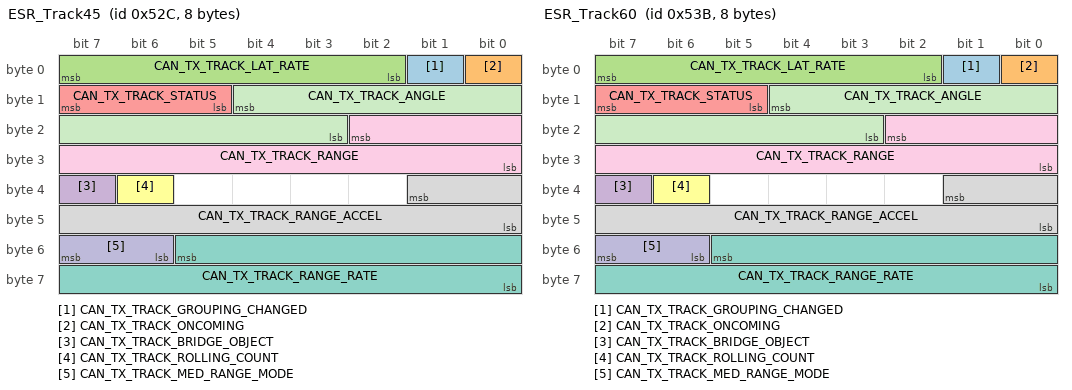
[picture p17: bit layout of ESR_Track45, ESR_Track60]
BO_ 1324 ESR_Track45: 8 ESR
 SG_ CAN_TX_TRACK_GROUPING_CHANGED : 1|1@0+ (1,0) [0|0] "" Vector__XXX
 SG_ CAN_TX_TRACK_ONCOMING : 0|1@0+ (1,0) [0|0] "" Vector__XXX
 SG_ CAN_TX_TRACK_LAT_RATE : 7|6@0- (0.25,0) [-8|7.75] "" Vector__XXX
 SG_ CAN_TX_TRACK_BRIDGE_OBJECT : 39|1@0+ (1,0) [0|0] "" Vector__XXX
 SG_ CAN_TX_TRACK_STATUS : 15|3@0+ (1,0) [0|7] "" Vector__XXX
 SG_ CAN_TX_TRACK_ROLLING_COUNT : 38|1@0+ (1,0) [0|1] "" Vector__XXX
 SG_ CAN_TX_TRACK_RANGE_RATE : 53|14@0- (0.01,0) [-81.92|81.91] "m/s" Vector__XXX
 SG_ CAN_TX_TRACK_RANGE_ACCEL : 33|10@0- (0.05,0) [-25.6|25.55] "m/s/s" Vector__XXX
 SG_ CAN_TX_TRACK_RANGE : 18|11@0+ (0.1,0) [0|204.7] "m" Vector__XXX
 SG_ CAN_TX_TRACK_MED_RANGE_MODE : 55|2@0+ (1,0) [0|3] "" Vector__XXX
 SG_ CAN_TX_TRACK_ANGLE : 12|10@0- (0.1,0) [-51.2|51.1] "deg" Vector__XXX

BO_ 1339 ESR_Track60: 8 ESR
 SG_ CAN_TX_TRACK_GROUPING_CHANGED : 1|1@0+ (1,0) [0|0] "" Vector__XXX
 SG_ CAN_TX_TRACK_ONCOMING : 0|1@0+ (1,0) [0|0] "" Vector__XXX
 SG_ CAN_TX_TRACK_LAT_RATE : 7|6@0- (0.25,0) [-8|7.75] "" Vector__XXX
 SG_ CAN_TX_TRACK_BRIDGE_OBJECT : 39|1@0+ (1,0) [0|0] "" Vector__XXX
 SG_ CAN_TX_TRACK_STATUS : 15|3@0+ (1,0) [0|7] "" Vector__XXX
 SG_ CAN_TX_TRACK_ROLLING_COUNT : 38|1@0+ (1,0) [0|1] "" Vector__XXX
 SG_ CAN_TX_TRACK_RANGE_RATE : 53|14@0- (0.01,0) [-81.92|81.91] "m/s" Vector__XXX
 SG_ CAN_TX_TRACK_RANGE_ACCEL : 33|10@0- (0.05,0) [-25.6|25.55] "m/s/s" Vector__XXX
 SG_ CAN_TX_TRACK_RANGE : 18|11@0+ (0.1,0) [0|204.7] "m" Vector__XXX
 SG_ CAN_TX_TRACK_MED_RANGE_MODE : 55|2@0+ (1,0) [0|3] "" Vector__XXX
 SG_ CAN_TX_TRACK_ANGLE : 12|10@0- (0.1,0) [-51.2|51.1] "deg" Vector__XXX

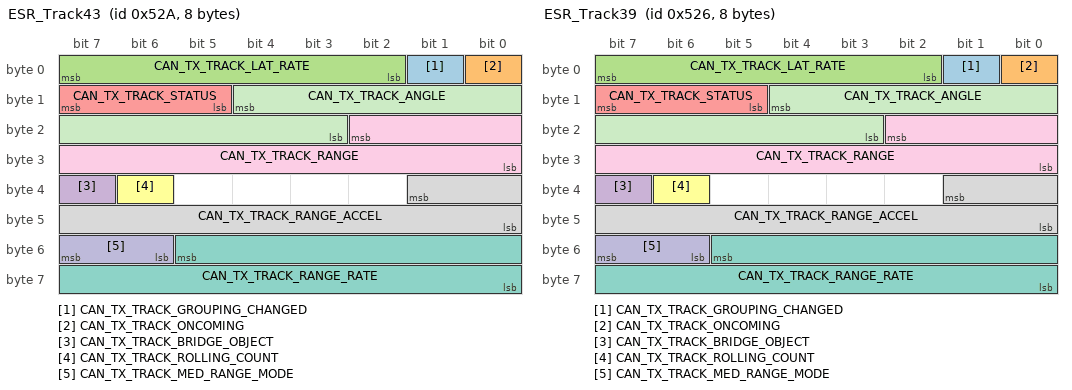
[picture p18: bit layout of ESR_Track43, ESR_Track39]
BO_ 1322 ESR_Track43: 8 ESR
 SG_ CAN_TX_TRACK_GROUPING_CHANGED : 1|1@0+ (1,0) [0|0] "" Vector__XXX
 SG_ CAN_TX_TRACK_ONCOMING : 0|1@0+ (1,0) [0|0] "" Vector__XXX
 SG_ CAN_TX_TRACK_LAT_RATE : 7|6@0- (0.25,0) [-8|7.75] "" Vector__XXX
 SG_ CAN_TX_TRACK_BRIDGE_OBJECT : 39|1@0+ (1,0) [0|0] "" Vector__XXX
 SG_ CAN_TX_TRACK_STATUS : 15|3@0+ (1,0) [0|7] "" Vector__XXX
 SG_ CAN_TX_TRACK_ROLLING_COUNT : 38|1@0+ (1,0) [0|1] "" Vector__XXX
 SG_ CAN_TX_TRACK_RANGE_RATE : 53|14@0- (0.01,0) [-81.92|81.91] "m/s" Vector__XXX
 SG_ CAN_TX_TRACK_RANGE_ACCEL : 33|10@0- (0.05,0) [-25.6|25.55] "m/s/s" Vector__XXX
 SG_ CAN_TX_TRACK_RANGE : 18|11@0+ (0.1,0) [0|204.7] "m" Vector__XXX
 SG_ CAN_TX_TRACK_MED_RANGE_MODE : 55|2@0+ (1,0) [0|3] "" Vector__XXX
 SG_ CAN_TX_TRACK_ANGLE : 12|10@0- (0.1,0) [-51.2|51.1] "deg" Vector__XXX

BO_ 1318 ESR_Track39: 8 ESR
 SG_ CAN_TX_TRACK_GROUPING_CHANGED : 1|1@0+ (1,0) [0|0] "" Vector__XXX
 SG_ CAN_TX_TRACK_ONCOMING : 0|1@0+ (1,0) [0|0] "" Vector__XXX
 SG_ CAN_TX_TRACK_LAT_RATE : 7|6@0- (0.25,0) [-8|7.75] "" Vector__XXX
 SG_ CAN_TX_TRACK_BRIDGE_OBJECT : 39|1@0+ (1,0) [0|0] "" Vector__XXX
 SG_ CAN_TX_TRACK_STATUS : 15|3@0+ (1,0) [0|7] "" Vector__XXX
 SG_ CAN_TX_TRACK_ROLLING_COUNT : 38|1@0+ (1,0) [0|1] "" Vector__XXX
 SG_ CAN_TX_TRACK_RANGE_RATE : 53|14@0- (0.01,0) [-81.92|81.91] "m/s" Vector__XXX
 SG_ CAN_TX_TRACK_RANGE_ACCEL : 33|10@0- (0.05,0) [-25.6|25.55] "m/s/s" Vector__XXX
 SG_ CAN_TX_TRACK_RANGE : 18|11@0+ (0.1,0) [0|204.7] "m" Vector__XXX
 SG_ CAN_TX_TRACK_MED_RANGE_MODE : 55|2@0+ (1,0) [0|3] "" Vector__XXX
 SG_ CAN_TX_TRACK_ANGLE : 12|10@0- (0.1,0) [-51.2|51.1] "deg" Vector__XXX

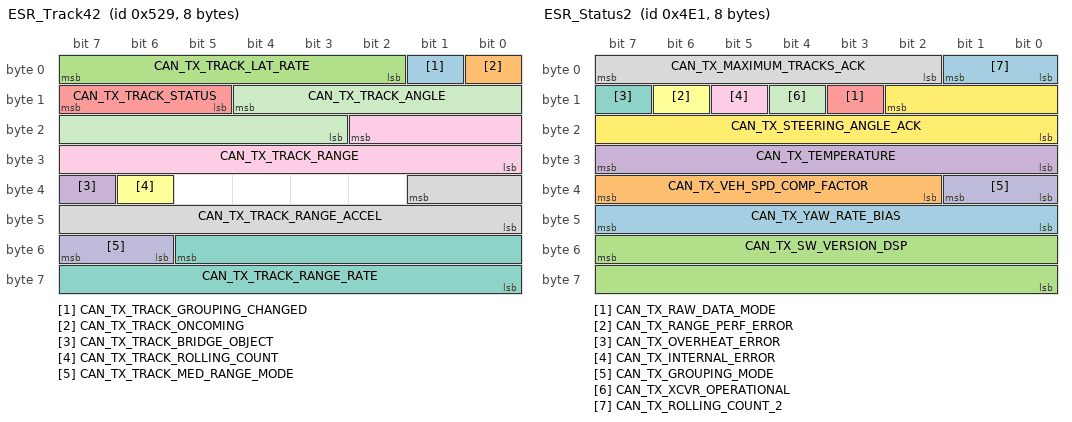
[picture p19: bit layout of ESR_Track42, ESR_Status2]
BO_ 1321 ESR_Track42: 8 ESR
 SG_ CAN_TX_TRACK_GROUPING_CHANGED : 1|1@0+ (1,0) [0|0] "" Vector__XXX
 SG_ CAN_TX_TRACK_ONCOMING : 0|1@0+ (1,0) [0|0] "" Vector__XXX
 SG_ CAN_TX_TRACK_LAT_RATE : 7|6@0- (0.25,0) [-8|7.75] "" Vector__XXX
 SG_ CAN_TX_TRACK_BRIDGE_OBJECT : 39|1@0+ (1,0) [0|0] "" Vector__XXX
 SG_ CAN_TX_TRACK_STATUS : 15|3@0+ (1,0) [0|7] "" Vector__XXX
 SG_ CAN_TX_TRACK_ROLLING_COUNT : 38|1@0+ (1,0) [0|1] "" Vector__XXX
 SG_ CAN_TX_TRACK_RANGE_RATE : 53|14@0- (0.01,0) [-81.92|81.91] "m/s" Vector__XXX
 SG_ CAN_TX_TRACK_RANGE_ACCEL : 33|10@0- (0.05,0) [-25.6|25.55] "m/s/s" Vector__XXX
 SG_ CAN_TX_TRACK_RANGE : 18|11@0+ (0.1,0) [0|204.7] "m" Vector__XXX
 SG_ CAN_TX_TRACK_MED_RANGE_MODE : 55|2@0+ (1,0) [0|3] "" Vector__XXX
 SG_ CAN_TX_TRACK_ANGLE : 12|10@0- (0.1,0) [-51.2|51.1] "deg" Vector__XXX

BO_ 1320 ESR_Track41: 8 ESR
 SG_ CAN_TX_TRACK_GROUPING_CHANGED : 1|1@0+ (1,0) [0|0] "" Vector__XXX
 SG_ CAN_TX_TRACK_ONCOMING : 0|1@0+ (1,0) [0|0] "" Vector__XXX
 SG_ CAN_TX_TRACK_LAT_RATE : 7|6@0- (0.25,0) [-8|7.75] "" Vector__XXX
 SG_ CAN_TX_TRACK_BRIDGE_OBJECT : 39|1@0+ (1,0) [0|0] "" Vector__XXX
 SG_ CAN_TX_TRACK_STATUS : 15|3@0+ (1,0) [0|7] "" Vector__XXX
 SG_ CAN_TX_TRACK_ROLLING_COUNT : 38|1@0+ (1,0) [0|1] "" Vector__XXX
 SG_ CAN_TX_TRACK_RANGE_RATE : 53|14@0- (0.01,0) [-81.92|81.91] "m/s" Vector__XXX
 SG_ CAN_TX_TRACK_RANGE_ACCEL : 33|10@0- (0.05,0) [-25.6|25.55] "m/s/s" Vector__XXX
 SG_ CAN_TX_TRACK_RANGE : 18|11@0+ (0.1,0) [0|204.7] "m" Vector__XXX
 SG_ CAN_TX_TRACK_MED_RANGE_MODE : 55|2@0+ (1,0) [0|3] "" Vector__XXX
 SG_ CAN_TX_TRACK_ANGLE : 12|10@0- (0.1,0) [-51.2|51.1] "deg" Vector__XXX

BO_ 1319 ESR_Track40: 8 ESR
 SG_ CAN_TX_TRACK_GROUPING_CHANGED : 1|1@0+ (1,0) [0|0] "" Vector__XXX
 SG_ CAN_TX_TRACK_ONCOMING : 0|1@0+ (1,0) [0|0] "" Vector__XXX
 SG_ CAN_TX_TRACK_LAT_RATE : 7|6@0- (0.25,0) [-8|7.75] "" Vector__XXX
 SG_ CAN_TX_TRACK_BRIDGE_OBJECT : 39|1@0+ (1,0) [0|0] "" Vector__XXX
 SG_ CAN_TX_TRACK_STATUS : 15|3@0+ (1,0) [0|7] "" Vector__XXX
 SG_ CAN_TX_TRACK_ROLLING_COUNT : 38|1@0+ (1,0) [0|1] "" Vector__XXX
 SG_ CAN_TX_TRACK_RANGE_RATE : 53|14@0- (0.01,0) [-81.92|81.91] "m/s" Vector__XXX
 SG_ CAN_TX_TRACK_RANGE_ACCEL : 33|10@0- (0.05,0) [-25.6|25.55] "m/s/s" Vector__XXX
 SG_ CAN_TX_TRACK_RANGE : 18|11@0+ (0.1,0) [0|204.7] "m" Vector__XXX
 SG_ CAN_TX_TRACK_MED_RANGE_MODE : 55|2@0+ (1,0) [0|3] "" Vector__XXX
 SG_ CAN_TX_TRACK_ANGLE : 12|10@0- (0.1,0) [-51.2|51.1] "deg" Vector__XXX

BO_ 1323 ESR_Track44: 8 ESR
 SG_ CAN_TX_TRACK_GROUPING_CHANGED : 1|1@0+ (1,0) [0|0] "" Vector__XXX
 SG_ CAN_TX_TRACK_ONCOMING : 0|1@0+ (1,0) [0|0] "" Vector__XXX
 SG_ CAN_TX_TRACK_LAT_RATE : 7|6@0- (0.25,0) [-8|7.75] "" Vector__XXX
 SG_ CAN_TX_TRACK_BRIDGE_OBJECT : 39|1@0+ (1,0) [0|0] "" Vector__XXX
 SG_ CAN_TX_TRACK_STATUS : 15|3@0+ (1,0) [0|7] "" Vector__XXX
 SG_ CAN_TX_TRACK_ROLLING_COUNT : 38|1@0+ (1,0) [0|1] "" Vector__XXX
 SG_ CAN_TX_TRACK_RANGE_RATE : 53|14@0- (0.01,0) [-81.92|81.91] "m/s" Vector__XXX
 SG_ CAN_TX_TRACK_RANGE_ACCEL : 33|10@0- (0.05,0) [-25.6|25.55] "m/s/s" Vector__XXX
 SG_ CAN_TX_TRACK_RANGE : 18|11@0+ (0.1,0) [0|204.7] "m" Vector__XXX
 SG_ CAN_TX_TRACK_MED_RANGE_MODE : 55|2@0+ (1,0) [0|3] "" Vector__XXX
 SG_ CAN_TX_TRACK_ANGLE : 12|10@0- (0.1,0) [-51.2|51.1] "deg" Vector__XXX

BO_ 1329 ESR_Track50: 8 ESR
 SG_ CAN_TX_TRACK_GROUPING_CHANGED : 1|1@0+ (1,0) [0|0] "" Vector__XXX
 SG_ CAN_TX_TRACK_ONCOMING : 0|1@0+ (1,0) [0|0] "" Vector__XXX
 SG_ CAN_TX_TRACK_LAT_RATE : 7|6@0- (0.25,0) [-8|7.75] "" Vector__XXX
 SG_ CAN_TX_TRACK_BRIDGE_OBJECT : 39|1@0+ (1,0) [0|0] "" Vector__XXX
 SG_ CAN_TX_TRACK_STATUS : 15|3@0+ (1,0) [0|7] "" Vector__XXX
 SG_ CAN_TX_TRACK_ROLLING_COUNT : 38|1@0+ (1,0) [0|1] "" Vector__XXX
 SG_ CAN_TX_TRACK_RANGE_RATE : 53|14@0- (0.01,0) [-81.92|81.91] "m/s" Vector__XXX
 SG_ CAN_TX_TRACK_RANGE_ACCEL : 33|10@0- (0.05,0) [-25.6|25.55] "m/s/s" Vector__XXX
 SG_ CAN_TX_TRACK_RANGE : 18|11@0+ (0.1,0) [0|204.7] "m" Vector__XXX
 SG_ CAN_TX_TRACK_MED_RANGE_MODE : 55|2@0+ (1,0) [0|3] "" Vector__XXX
 SG_ CAN_TX_TRACK_ANGLE : 12|10@0- (0.1,0) [-51.2|51.1] "deg" Vector__XXX

BO_ 1326 ESR_Track47: 8 ESR
 SG_ CAN_TX_TRACK_GROUPING_CHANGED : 1|1@0+ (1,0) [0|0] "" Vector__XXX
 SG_ CAN_TX_TRACK_ONCOMING : 0|1@0+ (1,0) [0|0] "" Vector__XXX
 SG_ CAN_TX_TRACK_LAT_RATE : 7|6@0- (0.25,0) [-8|7.75] "" Vector__XXX
 SG_ CAN_TX_TRACK_BRIDGE_OBJECT : 39|1@0+ (1,0) [0|0] "" Vector__XXX
 SG_ CAN_TX_TRACK_STATUS : 15|3@0+ (1,0) [0|7] "" Vector__XXX
 SG_ CAN_TX_TRACK_ROLLING_COUNT : 38|1@0+ (1,0) [0|1] "" Vector__XXX
 SG_ CAN_TX_TRACK_RANGE_RATE : 53|14@0- (0.01,0) [-81.92|81.91] "m/s" Vector__XXX
 SG_ CAN_TX_TRACK_RANGE_ACCEL : 33|10@0- (0.05,0) [-25.6|25.55] "m/s/s" Vector__XXX
 SG_ CAN_TX_TRACK_RANGE : 18|11@0+ (0.1,0) [0|204.7] "m" Vector__XXX
 SG_ CAN_TX_TRACK_MED_RANGE_MODE : 55|2@0+ (1,0) [0|3] "" Vector__XXX
 SG_ CAN_TX_TRACK_ANGLE : 12|10@0- (0.1,0) [-51.2|51.1] "deg" Vector__XXX

BO_ 1342 ESR_Track63: 8 ESR
 SG_ CAN_TX_TRACK_GROUPING_CHANGED : 1|1@0+ (1,0) [0|0] "" Vector__XXX
 SG_ CAN_TX_TRACK_ONCOMING : 0|1@0+ (1,0) [0|0] "" Vector__XXX
 SG_ CAN_TX_TRACK_LAT_RATE : 7|6@0- (0.25,0) [-8|7.75] "" Vector__XXX
 SG_ CAN_TX_TRACK_BRIDGE_OBJECT : 39|1@0+ (1,0) [0|0] "" Vector__XXX
 SG_ CAN_TX_TRACK_STATUS : 15|3@0+ (1,0) [0|7] "" Vector__XXX
 SG_ CAN_TX_TRACK_ROLLING_COUNT : 38|1@0+ (1,0) [0|1] "" Vector__XXX
 SG_ CAN_TX_TRACK_RANGE_RATE : 53|14@0- (0.01,0) [-81.92|81.91] "m/s" Vector__XXX
 SG_ CAN_TX_TRACK_RANGE_ACCEL : 33|10@0- (0.05,0) [-25.6|25.55] "m/s/s" Vector__XXX
 SG_ CAN_TX_TRACK_RANGE : 18|11@0+ (0.1,0) [0|204.7] "m" Vector__XXX
 SG_ CAN_TX_TRACK_MED_RANGE_MODE : 55|2@0+ (1,0) [0|3] "" Vector__XXX
 SG_ CAN_TX_TRACK_ANGLE : 12|10@0- (0.1,0) [-51.2|51.1] "deg" Vector__XXX

BO_ 1340 ESR_Track61: 8 ESR
 SG_ CAN_TX_TRACK_GROUPING_CHANGED : 1|1@0+ (1,0) [0|0] "" Vector__XXX
 SG_ CAN_TX_TRACK_ONCOMING : 0|1@0+ (1,0) [0|0] "" Vector__XXX
 SG_ CAN_TX_TRACK_LAT_RATE : 7|6@0- (0.25,0) [-8|7.75] "" Vector__XXX
 SG_ CAN_TX_TRACK_BRIDGE_OBJECT : 39|1@0+ (1,0) [0|0] "" Vector__XXX
 SG_ CAN_TX_TRACK_STATUS : 15|3@0+ (1,0) [0|7] "" Vector__XXX
 SG_ CAN_TX_TRACK_ROLLING_COUNT : 38|1@0+ (1,0) [0|1] "" Vector__XXX
 SG_ CAN_TX_TRACK_RANGE_RATE : 53|14@0- (0.01,0) [-81.92|81.91] "m/s" Vector__XXX
 SG_ CAN_TX_TRACK_RANGE_ACCEL : 33|10@0- (0.05,0) [-25.6|25.55] "m/s/s" Vector__XXX
 SG_ CAN_TX_TRACK_RANGE : 18|11@0+ (0.1,0) [0|204.7] "m" Vector__XXX
 SG_ CAN_TX_TRACK_MED_RANGE_MODE : 55|2@0+ (1,0) [0|3] "" Vector__XXX
 SG_ CAN_TX_TRACK_ANGLE : 12|10@0- (0.1,0) [-51.2|51.1] "deg" Vector__XXX

BO_ 1333 ESR_Track54: 8 ESR
 SG_ CAN_TX_TRACK_GROUPING_CHANGED : 1|1@0+ (1,0) [0|0] "" Vector__XXX
 SG_ CAN_TX_TRACK_ONCOMING : 0|1@0+ (1,0) [0|0] "" Vector__XXX
 SG_ CAN_TX_TRACK_LAT_RATE : 7|6@0- (0.25,0) [-8|7.75] "" Vector__XXX
 SG_ CAN_TX_TRACK_BRIDGE_OBJECT : 39|1@0+ (1,0) [0|0] "" Vector__XXX
 SG_ CAN_TX_TRACK_STATUS : 15|3@0+ (1,0) [0|7] "" Vector__XXX
 SG_ CAN_TX_TRACK_ROLLING_COUNT : 38|1@0+ (1,0) [0|1] "" Vector__XXX
 SG_ CAN_TX_TRACK_RANGE_RATE : 53|14@0- (0.01,0) [-81.92|81.91] "m/s" Vector__XXX
 SG_ CAN_TX_TRACK_RANGE_ACCEL : 33|10@0- (0.05,0) [-25.6|25.55] "m/s/s" Vector__XXX
 SG_ CAN_TX_TRACK_RANGE : 18|11@0+ (0.1,0) [0|204.7] "m" Vector__XXX
 SG_ CAN_TX_TRACK_MED_RANGE_MODE : 55|2@0+ (1,0) [0|3] "" Vector__XXX
 SG_ CAN_TX_TRACK_ANGLE : 12|10@0- (0.1,0) [-51.2|51.1] "deg" Vector__XXX

BO_ 1335 ESR_Track56: 8 ESR
 SG_ CAN_TX_TRACK_GROUPING_CHANGED : 1|1@0+ (1,0) [0|0] "" Vector__XXX
 SG_ CAN_TX_TRACK_ONCOMING : 0|1@0+ (1,0) [0|0] "" Vector__XXX
 SG_ CAN_TX_TRACK_LAT_RATE : 7|6@0- (0.25,0) [-8|7.75] "" Vector__XXX
 SG_ CAN_TX_TRACK_BRIDGE_OBJECT : 39|1@0+ (1,0) [0|0] "" Vector__XXX
 SG_ CAN_TX_TRACK_STATUS : 15|3@0+ (1,0) [0|7] "" Vector__XXX
 SG_ CAN_TX_TRACK_ROLLING_COUNT : 38|1@0+ (1,0) [0|1] "" Vector__XXX
 SG_ CAN_TX_TRACK_RANGE_RATE : 53|14@0- (0.01,0) [-81.92|81.91] "m/s" Vector__XXX
 SG_ CAN_TX_TRACK_RANGE_ACCEL : 33|10@0- (0.05,0) [-25.6|25.55] "m/s/s" Vector__XXX
 SG_ CAN_TX_TRACK_RANGE : 18|11@0+ (0.1,0) [0|204.7] "m" Vector__XXX
 SG_ CAN_TX_TRACK_MED_RANGE_MODE : 55|2@0+ (1,0) [0|3] "" Vector__XXX
 SG_ CAN_TX_TRACK_ANGLE : 12|10@0- (0.1,0) [-51.2|51.1] "deg" Vector__XXX

BO_ 1337 ESR_Track58: 8 ESR
 SG_ CAN_TX_TRACK_GROUPING_CHANGED : 1|1@0+ (1,0) [0|0] "" Vector__XXX
 SG_ CAN_TX_TRACK_ONCOMING : 0|1@0+ (1,0) [0|0] "" Vector__XXX
 SG_ CAN_TX_TRACK_LAT_RATE : 7|6@0- (0.25,0) [-8|7.75] "" Vector__XXX
 SG_ CAN_TX_TRACK_BRIDGE_OBJECT : 39|1@0+ (1,0) [0|0] "" Vector__XXX
 SG_ CAN_TX_TRACK_STATUS : 15|3@0+ (1,0) [0|7] "" Vector__XXX
 SG_ CAN_TX_TRACK_ROLLING_COUNT : 38|1@0+ (1,0) [0|1] "" Vector__XXX
 SG_ CAN_TX_TRACK_RANGE_RATE : 53|14@0- (0.01,0) [-81.92|81.91] "m/s" Vector__XXX
 SG_ CAN_TX_TRACK_RANGE_ACCEL : 33|10@0- (0.05,0) [-25.6|25.55] "m/s/s" Vector__XXX
 SG_ CAN_TX_TRACK_RANGE : 18|11@0+ (0.1,0) [0|204.7] "m" Vector__XXX
 SG_ CAN_TX_TRACK_MED_RANGE_MODE : 55|2@0+ (1,0) [0|3] "" Vector__XXX
 SG_ CAN_TX_TRACK_ANGLE : 12|10@0- (0.1,0) [-51.2|51.1] "deg" Vector__XXX

BO_ 1331 ESR_Track52: 8 ESR
 SG_ CAN_TX_TRACK_GROUPING_CHANGED : 1|1@0+ (1,0) [0|0] "" Vector__XXX
 SG_ CAN_TX_TRACK_ONCOMING : 0|1@0+ (1,0) [0|0] "" Vector__XXX
 SG_ CAN_TX_TRACK_LAT_RATE : 7|6@0- (0.25,0) [-8|7.75] "" Vector__XXX
 SG_ CAN_TX_TRACK_BRIDGE_OBJECT : 39|1@0+ (1,0) [0|0] "" Vector__XXX
 SG_ CAN_TX_TRACK_STATUS : 15|3@0+ (1,0) [0|7] "" Vector__XXX
 SG_ CAN_TX_TRACK_ROLLING_COUNT : 38|1@0+ (1,0) [0|1] "" Vector__XXX
 SG_ CAN_TX_TRACK_RANGE_RATE : 53|14@0- (0.01,0) [-81.92|81.91] "m/s" Vector__XXX
 SG_ CAN_TX_TRACK_RANGE_ACCEL : 33|10@0- (0.05,0) [-25.6|25.55] "m/s/s" Vector__XXX
 SG_ CAN_TX_TRACK_RANGE : 18|11@0+ (0.1,0) [0|204.7] "m" Vector__XXX
 SG_ CAN_TX_TRACK_MED_RANGE_MODE : 55|2@0+ (1,0) [0|3] "" Vector__XXX
 SG_ CAN_TX_TRACK_ANGLE : 12|10@0- (0.1,0) [-51.2|51.1] "deg" Vector__XXX

BO_ 1338 ESR_Track59: 8 ESR
 SG_ CAN_TX_TRACK_GROUPING_CHANGED : 1|1@0+ (1,0) [0|0] "" Vector__XXX
 SG_ CAN_TX_TRACK_ONCOMING : 0|1@0+ (1,0) [0|0] "" Vector__XXX
 SG_ CAN_TX_TRACK_LAT_RATE : 7|6@0- (0.25,0) [-8|7.75] "" Vector__XXX
 SG_ CAN_TX_TRACK_BRIDGE_OBJECT : 39|1@0+ (1,0) [0|0] "" Vector__XXX
 SG_ CAN_TX_TRACK_STATUS : 15|3@0+ (1,0) [0|7] "" Vector__XXX
 SG_ CAN_TX_TRACK_ROLLING_COUNT : 38|1@0+ (1,0) [0|1] "" Vector__XXX
 SG_ CAN_TX_TRACK_RANGE_RATE : 53|14@0- (0.01,0) [-81.92|81.91] "m/s" Vector__XXX
 SG_ CAN_TX_TRACK_RANGE_ACCEL : 33|10@0- (0.05,0) [-25.6|25.55] "m/s/s" Vector__XXX
 SG_ CAN_TX_TRACK_RANGE : 18|11@0+ (0.1,0) [0|204.7] "m" Vector__XXX
 SG_ CAN_TX_TRACK_MED_RANGE_MODE : 55|2@0+ (1,0) [0|3] "" Vector__XXX
 SG_ CAN_TX_TRACK_ANGLE : 12|10@0- (0.1,0) [-51.2|51.1] "deg" Vector__XXX

BO_ 1336 ESR_Track57: 8 ESR
 SG_ CAN_TX_TRACK_GROUPING_CHANGED : 1|1@0+ (1,0) [0|0] "" Vector__XXX
 SG_ CAN_TX_TRACK_ONCOMING : 0|1@0+ (1,0) [0|0] "" Vector__XXX
 SG_ CAN_TX_TRACK_LAT_RATE : 7|6@0- (0.25,0) [-8|7.75] "" Vector__XXX
 SG_ CAN_TX_TRACK_BRIDGE_OBJECT : 39|1@0+ (1,0) [0|0] "" Vector__XXX
 SG_ CAN_TX_TRACK_STATUS : 15|3@0+ (1,0) [0|7] "" Vector__XXX
 SG_ CAN_TX_TRACK_ROLLING_COUNT : 38|1@0+ (1,0) [0|1] "" Vector__XXX
 SG_ CAN_TX_TRACK_RANGE_RATE : 53|14@0- (0.01,0) [-81.92|81.91] "m/s" Vector__XXX
 SG_ CAN_TX_TRACK_RANGE_ACCEL : 33|10@0- (0.05,0) [-25.6|25.55] "m/s/s" Vector__XXX
 SG_ CAN_TX_TRACK_RANGE : 18|11@0+ (0.1,0) [0|204.7] "m" Vector__XXX
 SG_ CAN_TX_TRACK_MED_RANGE_MODE : 55|2@0+ (1,0) [0|3] "" Vector__XXX
 SG_ CAN_TX_TRACK_ANGLE : 12|10@0- (0.1,0) [-51.2|51.1] "deg" Vector__XXX

BO_ 1334 ESR_Track55: 8 ESR
 SG_ CAN_TX_TRACK_GROUPING_CHANGED : 1|1@0+ (1,0) [0|0] "" Vector__XXX
 SG_ CAN_TX_TRACK_ONCOMING : 0|1@0+ (1,0) [0|0] "" Vector__XXX
 SG_ CAN_TX_TRACK_LAT_RATE : 7|6@0- (0.25,0) [-8|7.75] "" Vector__XXX
 SG_ CAN_TX_TRACK_BRIDGE_OBJECT : 39|1@0+ (1,0) [0|0] "" Vector__XXX
 SG_ CAN_TX_TRACK_STATUS : 15|3@0+ (1,0) [0|7] "" Vector__XXX
 SG_ CAN_TX_TRACK_ROLLING_COUNT : 38|1@0+ (1,0) [0|1] "" Vector__XXX
 SG_ CAN_TX_TRACK_RANGE_RATE : 53|14@0- (0.01,0) [-81.92|81.91] "m/s" Vector__XXX
 SG_ CAN_TX_TRACK_RANGE_ACCEL : 33|10@0- (0.05,0) [-25.6|25.55] "m/s/s" Vector__XXX
 SG_ CAN_TX_TRACK_RANGE : 18|11@0+ (0.1,0) [0|204.7] "m" Vector__XXX
 SG_ CAN_TX_TRACK_MED_RANGE_MODE : 55|2@0+ (1,0) [0|3] "" Vector__XXX
 SG_ CAN_TX_TRACK_ANGLE : 12|10@0- (0.1,0) [-51.2|51.1] "deg" Vector__XXX

BO_ 1330 ESR_Track51: 8 ESR
 SG_ CAN_TX_TRACK_GROUPING_CHANGED : 1|1@0+ (1,0) [0|0] "" Vector__XXX
 SG_ CAN_TX_TRACK_ONCOMING : 0|1@0+ (1,0) [0|0] "" Vector__XXX
 SG_ CAN_TX_TRACK_LAT_RATE : 7|6@0- (0.25,0) [-8|7.75] "" Vector__XXX
 SG_ CAN_TX_TRACK_BRIDGE_OBJECT : 39|1@0+ (1,0) [0|0] "" Vector__XXX
 SG_ CAN_TX_TRACK_STATUS : 15|3@0+ (1,0) [0|7] "" Vector__XXX
 SG_ CAN_TX_TRACK_ROLLING_COUNT : 38|1@0+ (1,0) [0|1] "" Vector__XXX
 SG_ CAN_TX_TRACK_RANGE_RATE : 53|14@0- (0.01,0) [-81.92|81.91] "m/s" Vector__XXX
 SG_ CAN_TX_TRACK_RANGE_ACCEL : 33|10@0- (0.05,0) [-25.6|25.55] "m/s/s" Vector__XXX
 SG_ CAN_TX_TRACK_RANGE : 18|11@0+ (0.1,0) [0|204.7] "m" Vector__XXX
 SG_ CAN_TX_TRACK_MED_RANGE_MODE : 55|2@0+ (1,0) [0|3] "" Vector__XXX
 SG_ CAN_TX_TRACK_ANGLE : 12|10@0- (0.1,0) [-51.2|51.1] "deg" Vector__XXX

BO_ 1328 ESR_Track49: 8 ESR
 SG_ CAN_TX_TRACK_GROUPING_CHANGED : 1|1@0+ (1,0) [0|0] "" Vector__XXX
 SG_ CAN_TX_TRACK_ONCOMING : 0|1@0+ (1,0) [0|0] "" Vector__XXX
 SG_ CAN_TX_TRACK_LAT_RATE : 7|6@0- (0.25,0) [-8|7.75] "" Vector__XXX
 SG_ CAN_TX_TRACK_BRIDGE_OBJECT : 39|1@0+ (1,0) [0|0] "" Vector__XXX
 SG_ CAN_TX_TRACK_STATUS : 15|3@0+ (1,0) [0|7] "" Vector__XXX
 SG_ CAN_TX_TRACK_ROLLING_COUNT : 38|1@0+ (1,0) [0|1] "" Vector__XXX
 SG_ CAN_TX_TRACK_RANGE_RATE : 53|14@0- (0.01,0) [-81.92|81.91] "m/s" Vector__XXX
 SG_ CAN_TX_TRACK_RANGE_ACCEL : 33|10@0- (0.05,0) [-25.6|25.55] "m/s/s" Vector__XXX
 SG_ CAN_TX_TRACK_RANGE : 18|11@0+ (0.1,0) [0|204.7] "m" Vector__XXX
 SG_ CAN_TX_TRACK_MED_RANGE_MODE : 55|2@0+ (1,0) [0|3] "" Vector__XXX
 SG_ CAN_TX_TRACK_ANGLE : 12|10@0- (0.1,0) [-51.2|51.1] "deg" Vector__XXX

BO_ 1282 ESR_Track03: 8 ESR
 SG_ CAN_TX_TRACK_GROUPING_CHANGED : 1|1@0+ (1,0) [0|0] "" Vector__XXX
 SG_ CAN_TX_TRACK_ONCOMING : 0|1@0+ (1,0) [0|0] "" Vector__XXX
 SG_ CAN_TX_TRACK_LAT_RATE : 7|6@0- (0.25,0) [-8|7.75] "" Vector__XXX
 SG_ CAN_TX_TRACK_BRIDGE_OBJECT : 39|1@0+ (1,0) [0|0] "" Vector__XXX
 SG_ CAN_TX_TRACK_STATUS : 15|3@0+ (1,0) [0|7] "" Vector__XXX
 SG_ CAN_TX_TRACK_ROLLING_COUNT : 38|1@0+ (1,0) [0|1] "" Vector__XXX
 SG_ CAN_TX_TRACK_RANGE_RATE : 53|14@0- (0.01,0) [-81.92|81.91] "m/s" Vector__XXX
 SG_ CAN_TX_TRACK_RANGE_ACCEL : 33|10@0- (0.05,0) [-25.6|25.55] "m/s/s" Vector__XXX
 SG_ CAN_TX_TRACK_RANGE : 18|11@0+ (0.1,0) [0|204.7] "m" Vector__XXX
 SG_ CAN_TX_TRACK_MED_RANGE_MODE : 55|2@0+ (1,0) [0|3] "" Vector__XXX
 SG_ CAN_TX_TRACK_ANGLE : 12|10@0- (0.1,0) [-51.2|51.1] "deg" Vector__XXX

BO_ 1283 ESR_Track04: 8 ESR
 SG_ CAN_TX_TRACK_GROUPING_CHANGED : 1|1@0+ (1,0) [0|0] "" Vector__XXX
 SG_ CAN_TX_TRACK_ONCOMING : 0|1@0+ (1,0) [0|0] "" Vector__XXX
 SG_ CAN_TX_TRACK_LAT_RATE : 7|6@0- (0.25,0) [-8|7.75] "" Vector__XXX
 SG_ CAN_TX_TRACK_BRIDGE_OBJECT : 39|1@0+ (1,0) [0|0] "" Vector__XXX
 SG_ CAN_TX_TRACK_STATUS : 15|3@0+ (1,0) [0|7] "" Vector__XXX
 SG_ CAN_TX_TRACK_ROLLING_COUNT : 38|1@0+ (1,0) [0|1] "" Vector__XXX
 SG_ CAN_TX_TRACK_RANGE_RATE : 53|14@0- (0.01,0) [-81.92|81.91] "m/s" Vector__XXX
 SG_ CAN_TX_TRACK_RANGE_ACCEL : 33|10@0- (0.05,0) [-25.6|25.55] "m/s/s" Vector__XXX
 SG_ CAN_TX_TRACK_RANGE : 18|11@0+ (0.1,0) [0|204.7] "m" Vector__XXX
 SG_ CAN_TX_TRACK_MED_RANGE_MODE : 55|2@0+ (1,0) [0|3] "" Vector__XXX
 SG_ CAN_TX_TRACK_ANGLE : 12|10@0- (0.1,0) [-51.2|51.1] "deg" Vector__XXX

BO_ 1284 ESR_Track05: 8 ESR
 SG_ CAN_TX_TRACK_GROUPING_CHANGED : 1|1@0+ (1,0) [0|0] "" Vector__XXX
 SG_ CAN_TX_TRACK_ONCOMING : 0|1@0+ (1,0) [0|0] "" Vector__XXX
 SG_ CAN_TX_TRACK_LAT_RATE : 7|6@0- (0.25,0) [-8|7.75] "" Vector__XXX
 SG_ CAN_TX_TRACK_BRIDGE_OBJECT : 39|1@0+ (1,0) [0|0] "" Vector__XXX
 SG_ CAN_TX_TRACK_STATUS : 15|3@0+ (1,0) [0|7] "" Vector__XXX
 SG_ CAN_TX_TRACK_ROLLING_COUNT : 38|1@0+ (1,0) [0|1] "" Vector__XXX
 SG_ CAN_TX_TRACK_RANGE_RATE : 53|14@0- (0.01,0) [-81.92|81.91] "m/s" Vector__XXX
 SG_ CAN_TX_TRACK_RANGE_ACCEL : 33|10@0- (0.05,0) [-25.6|25.55] "m/s/s" Vector__XXX
 SG_ CAN_TX_TRACK_RANGE : 18|11@0+ (0.1,0) [0|204.7] "m" Vector__XXX
 SG_ CAN_TX_TRACK_MED_RANGE_MODE : 55|2@0+ (1,0) [0|3] "" Vector__XXX
 SG_ CAN_TX_TRACK_ANGLE : 12|10@0- (0.1,0) [-51.2|51.1] "deg" Vector__XXX

BO_ 1311 ESR_Track32: 8 ESR
 SG_ CAN_TX_TRACK_GROUPING_CHANGED : 1|1@0+ (1,0) [0|0] "" Vector__XXX
 SG_ CAN_TX_TRACK_ONCOMING : 0|1@0+ (1,0) [0|0] "" Vector__XXX
 SG_ CAN_TX_TRACK_LAT_RATE : 7|6@0- (0.25,0) [-8|7.75] "" Vector__XXX
 SG_ CAN_TX_TRACK_BRIDGE_OBJECT : 39|1@0+ (1,0) [0|0] "" Vector__XXX
 SG_ CAN_TX_TRACK_STATUS : 15|3@0+ (1,0) [0|7] "" Vector__XXX
 SG_ CAN_TX_TRACK_ROLLING_COUNT : 38|1@0+ (1,0) [0|1] "" Vector__XXX
 SG_ CAN_TX_TRACK_RANGE_RATE : 53|14@0- (0.01,0) [-81.92|81.91] "m/s" Vector__XXX
 SG_ CAN_TX_TRACK_RANGE_ACCEL : 33|10@0- (0.05,0) [-25.6|25.55] "m/s/s" Vector__XXX
 SG_ CAN_TX_TRACK_RANGE : 18|11@0+ (0.1,0) [0|204.7] "m" Vector__XXX
 SG_ CAN_TX_TRACK_MED_RANGE_MODE : 55|2@0+ (1,0) [0|3] "" Vector__XXX
 SG_ CAN_TX_TRACK_ANGLE : 12|10@0- (0.1,0) [-51.2|51.1] "deg" Vector__XXX

BO_ 1290 ESR_Track11: 8 ESR
 SG_ CAN_TX_TRACK_GROUPING_CHANGED : 1|1@0+ (1,0) [0|0] "" Vector__XXX
 SG_ CAN_TX_TRACK_ONCOMING : 0|1@0+ (1,0) [0|0] "" Vector__XXX
 SG_ CAN_TX_TRACK_LAT_RATE : 7|6@0- (0.25,0) [-8|7.75] "" Vector__XXX
 SG_ CAN_TX_TRACK_BRIDGE_OBJECT : 39|1@0+ (1,0) [0|0] "" Vector__XXX
 SG_ CAN_TX_TRACK_STATUS : 15|3@0+ (1,0) [0|7] "" Vector__XXX
 SG_ CAN_TX_TRACK_ROLLING_COUNT : 38|1@0+ (1,0) [0|1] "" Vector__XXX
 SG_ CAN_TX_TRACK_RANGE_RATE : 53|14@0- (0.01,0) [-81.92|81.91] "m/s" Vector__XXX
 SG_ CAN_TX_TRACK_RANGE_ACCEL : 33|10@0- (0.05,0) [-25.6|25.55] "m/s/s" Vector__XXX
 SG_ CAN_TX_TRACK_RANGE : 18|11@0+ (0.1,0) [0|204.7] "m" Vector__XXX
 SG_ CAN_TX_TRACK_MED_RANGE_MODE : 55|2@0+ (1,0) [0|3] "" Vector__XXX
 SG_ CAN_TX_TRACK_ANGLE : 12|10@0- (0.1,0) [-51.2|51.1] "deg" Vector__XXX

BO_ 1293 ESR_Track14: 8 ESR
 SG_ CAN_TX_TRACK_GROUPING_CHANGED : 1|1@0+ (1,0) [0|0] "" Vector__XXX
 SG_ CAN_TX_TRACK_ONCOMING : 0|1@0+ (1,0) [0|0] "" Vector__XXX
 SG_ CAN_TX_TRACK_LAT_RATE : 7|6@0- (0.25,0) [-8|7.75] "" Vector__XXX
 SG_ CAN_TX_TRACK_BRIDGE_OBJECT : 39|1@0+ (1,0) [0|0] "" Vector__XXX
 SG_ CAN_TX_TRACK_STATUS : 15|3@0+ (1,0) [0|7] "" Vector__XXX
 SG_ CAN_TX_TRACK_ROLLING_COUNT : 38|1@0+ (1,0) [0|1] "" Vector__XXX
 SG_ CAN_TX_TRACK_RANGE_RATE : 53|14@0- (0.01,0) [-81.92|81.91] "m/s" Vector__XXX
 SG_ CAN_TX_TRACK_RANGE_ACCEL : 33|10@0- (0.05,0) [-25.6|25.55] "m/s/s" Vector__XXX
 SG_ CAN_TX_TRACK_RANGE : 18|11@0+ (0.1,0) [0|204.7] "m" Vector__XXX
 SG_ CAN_TX_TRACK_MED_RANGE_MODE : 55|2@0+ (1,0) [0|3] "" Vector__XXX
 SG_ CAN_TX_TRACK_ANGLE : 12|10@0- (0.1,0) [-51.2|51.1] "deg" Vector__XXX

BO_ 1325 ESR_Track46: 8 ESR
 SG_ CAN_TX_TRACK_GROUPING_CHANGED : 1|1@0+ (1,0) [0|0] "" Vector__XXX
 SG_ CAN_TX_TRACK_ONCOMING : 0|1@0+ (1,0) [0|0] "" Vector__XXX
 SG_ CAN_TX_TRACK_LAT_RATE : 7|6@0- (0.25,0) [-8|7.75] "" Vector__XXX
 SG_ CAN_TX_TRACK_BRIDGE_OBJECT : 39|1@0+ (1,0) [0|0] "" Vector__XXX
 SG_ CAN_TX_TRACK_STATUS : 15|3@0+ (1,0) [0|7] "" Vector__XXX
 SG_ CAN_TX_TRACK_ROLLING_COUNT : 38|1@0+ (1,0) [0|1] "" Vector__XXX
 SG_ CAN_TX_TRACK_RANGE_RATE : 53|14@0- (0.01,0) [-81.92|81.91] "m/s" Vector__XXX
 SG_ CAN_TX_TRACK_RANGE_ACCEL : 33|10@0- (0.05,0) [-25.6|25.55] "m/s/s" Vector__XXX
 SG_ CAN_TX_TRACK_RANGE : 18|11@0+ (0.1,0) [0|204.7] "m" Vector__XXX
 SG_ CAN_TX_TRACK_MED_RANGE_MODE : 55|2@0+ (1,0) [0|3] "" Vector__XXX
 SG_ CAN_TX_TRACK_ANGLE : 12|10@0- (0.1,0) [-51.2|51.1] "deg" Vector__XXX

BO_ 1341 ESR_Track62: 8 ESR
 SG_ CAN_TX_TRACK_GROUPING_CHANGED : 1|1@0+ (1,0) [0|0] "" Vector__XXX
 SG_ CAN_TX_TRACK_ONCOMING : 0|1@0+ (1,0) [0|0] "" Vector__XXX
 SG_ CAN_TX_TRACK_LAT_RATE : 7|6@0- (0.25,0) [-8|7.75] "" Vector__XXX
 SG_ CAN_TX_TRACK_BRIDGE_OBJECT : 39|1@0+ (1,0) [0|0] "" Vector__XXX
 SG_ CAN_TX_TRACK_STATUS : 15|3@0+ (1,0) [0|7] "" Vector__XXX
 SG_ CAN_TX_TRACK_ROLLING_COUNT : 38|1@0+ (1,0) [0|1] "" Vector__XXX
 SG_ CAN_TX_TRACK_RANGE_RATE : 53|14@0- (0.01,0) [-81.92|81.91] "m/s" Vector__XXX
 SG_ CAN_TX_TRACK_RANGE_ACCEL : 33|10@0- (0.05,0) [-25.6|25.55] "m/s/s" Vector__XXX
 SG_ CAN_TX_TRACK_RANGE : 18|11@0+ (0.1,0) [0|204.7] "m" Vector__XXX
 SG_ CAN_TX_TRACK_MED_RANGE_MODE : 55|2@0+ (1,0) [0|3] "" Vector__XXX
 SG_ CAN_TX_TRACK_ANGLE : 12|10@0- (0.1,0) [-51.2|51.1] "deg" Vector__XXX

BO_ 1281 ESR_Track02: 8 ESR
 SG_ CAN_TX_TRACK_GROUPING_CHANGED : 1|1@0+ (1,0) [0|0] "" Vector__XXX
 SG_ CAN_TX_TRACK_ONCOMING : 0|1@0+ (1,0) [0|0] "" Vector__XXX
 SG_ CAN_TX_TRACK_LAT_RATE : 7|6@0- (0.25,0) [-8|7.75] "" Vector__XXX
 SG_ CAN_TX_TRACK_BRIDGE_OBJECT : 39|1@0+ (1,0) [0|0] "" Vector__XXX
 SG_ CAN_TX_TRACK_STATUS : 15|3@0+ (1,0) [0|7] "" Vector__XXX
 SG_ CAN_TX_TRACK_ROLLING_COUNT : 38|1@0+ (1,0) [0|1] "" Vector__XXX
 SG_ CAN_TX_TRACK_RANGE_RATE : 53|14@0- (0.01,0) [-81.92|81.91] "m/s" Vector__XXX
 SG_ CAN_TX_TRACK_RANGE_ACCEL : 33|10@0- (0.05,0) [-25.6|25.55] "m/s/s" Vector__XXX
 SG_ CAN_TX_TRACK_RANGE : 18|11@0+ (0.1,0) [0|204.7] "m" Vector__XXX
 SG_ CAN_TX_TRACK_MED_RANGE_MODE : 55|2@0+ (1,0) [0|3] "" Vector__XXX
 SG_ CAN_TX_TRACK_ANGLE : 12|10@0- (0.1,0) [-51.2|51.1] "deg" Vector__XXX

BO_ 1511 ESR_Status8: 8 ESR
 SG_ CAN_TX_HISTORY_FAULT_7 : 63|8@0+ (1,0) [0|0] "" Vector__XXX
 SG_ CAN_TX_HISTORY_FAULT_6 : 55|8@0+ (1,0) [0|0] "" Vector__XXX
 SG_ CAN_TX_HISTORY_FAULT_5 : 47|8@0+ (1,0) [0|0] "" Vector__XXX
 SG_ CAN_TX_HISTORY_FAULT_4 : 39|8@0+ (1,0) [0|0] "" Vector__XXX
 SG_ CAN_TX_HISTORY_FAULT_3 : 31|8@0+ (1,0) [0|0] "" Vector__XXX
 SG_ CAN_TX_HISTORY_FAULT_2 : 23|8@0+ (1,0) [0|0] "" Vector__XXX
 SG_ CAN_TX_HISTORY_FAULT_1 : 15|8@0+ (1,0) [0|0] "" Vector__XXX
 SG_ CAN_TX_HISTORY_FAULT_0 : 7|8@0+ (1,0) [0|0] "" Vector__XXX

BO_ 1510 ESR_Status7: 8 ESR
 SG_ CAN_TX_ACTIVE_FAULT_7 : 63|8@0+ (1,0) [0|0] "" Vector__XXX
 SG_ CAN_TX_ACTIVE_FAULT_6 : 55|8@0+ (1,0) [0|0] "" Vector__XXX
 SG_ CAN_TX_ACTIVE_FAULT_5 : 47|8@0+ (1,0) [0|0] "" Vector__XXX
 SG_ CAN_TX_ACTIVE_FAULT_4 : 39|8@0+ (1,0) [0|0] "" Vector__XXX
 SG_ CAN_TX_ACTIVE_FAULT_3 : 31|8@0+ (1,0) [0|0] "" Vector__XXX
 SG_ CAN_TX_ACTIVE_FAULT_2 : 23|8@0+ (1,0) [0|0] "" Vector__XXX
 SG_ CAN_TX_ACTIVE_FAULT_0 : 7|8@0+ (1,0) [0|0] "" Vector__XXX
 SG_ CAN_TX_ACTIVE_FAULT_1 : 15|8@0+ (1,0) [0|0] "" Vector__XXX

BO_ 1509 ESR_Status6: 8 ESR
 SG_ CAN_TX_SW_VERSION_DSP_3RD_BYTE : 31|4@0+ (1,0) [0|0] "" Vector__XXX
 SG_ CAN_TX_VERTICAL_ALIGN_UPDATED : 27|1@0+ (1,0) [0|0] "" Vector__XXX
 SG_ CAN_TX_VERTICAL_MISALIGNMENT : 63|8@0- (0.0625,0) [-6|6] "" Vector__XXX
 SG_ CAN_TX_SERV_ALIGN_UPDATES_DONE : 55|8@0+ (1,0) [0|255] "" Vector__XXX
 SG_ CAN_TX_FOUND_TARGET : 39|1@0+ (1,0) [0|0] "" Vector__XXX
 SG_ CAN_TX_FACTORY_MISALIGNMENT : 47|8@0- (0.0625,0) [-5|5] "deg" Vector__XXX
 SG_ CAN_TX_FACTORY_ALIGN_STATUS_2 : 34|3@0+ (1,0) [0|5] "" Vector__XXX
 SG_ CAN_TX_FACTORY_ALIGN_STATUS_1 : 37|3@0+ (1,0) [0|5] "" Vector__XXX
 SG_ CAN_TX_RECOMMEND_UNCONVERGE : 38|1@0+ (1,0) [0|0] "" Vector__XXX
 SG_ CAN_TX_WAVE_DIFF_A2D : 23|8@0+ (1,0) [0|0] "" Vector__XXX
 SG_ CAN_TX_SYSTEM_POWER_MODE : 26|3@0+ (1,0) [0|0] "" Vector__XXX
 SG_ CAN_TX_SUPPLY_N5V_A2D : 15|8@0+ (1,0) [0|0] "" Vector__XXX
 SG_ CAN_TX_SUPPLY_1P8V_A2D : 7|8@0+ (1,0) [0|0] "" Vector__XXX

BO_ 1508 ESR_Status5: 8 ESR
 SG_ CAN_TX_SUPPLY_10V_A2D : 63|8@0+ (1,0) [0|0] "" Vector__XXX
 SG_ CAN_TX_TEMP2_A2D : 31|8@0+ (1,0) [0|0] "" Vector__XXX
 SG_ CAN_TX_TEMP1_A2D : 23|8@0+ (1,0) [0|0] "" Vector__XXX
 SG_ CAN_TX_SWBATT_A2D : 7|8@0+ (1,0) [0|0] "" Vector__XXX
 SG_ CAN_TX_SUPPLY_5VDX_A2D : 47|8@0+ (1,0) [0|0] "" Vector__XXX
 SG_ CAN_TX_SUPPLY_5VA_A2D : 39|8@0+ (1,0) [0|0] "" Vector__XXX
 SG_ CAN_TX_SUPPLY_3P3V_A2D : 55|8@0+ (1,0) [0|0] "" Vector__XXX
 SG_ CAN_TX_IGNP_A2D : 15|8@0+ (1,0) [0|0] "" Vector__XXX

BO_ 1344 ESR_TrackMotionPower: 8 ESR
 SG_ CAN_TX_TRACK_MOVABLE_SLOW64 m9 : 14|1@0+ (1,0) [0|1] "" Vector__XXX
 SG_ CAN_TX_TRACK_POWER64 m9 : 12|5@0+ (1,-10) [-10|21] "dB" Vector__XXX
 SG_ CAN_TX_TRACK_MOVING64 m9 : 13|1@0+ (1,0) [0|1] "" Vector__XXX
 SG_ CAN_TX_TRACK_MOVABLE_FAST64 m9 : 15|1@0+ (1,0) [0|1] "" Vector__XXX
 SG_ CAN_TX_TRACK_MOVABLE_SLOW63 m8 : 62|1@0+ (1,0) [0|1] "" Vector__XXX
 SG_ CAN_TX_TRACK_MOVABLE_SLOW62 m8 : 54|1@0+ (1,0) [0|1] "" Vector__XXX
 SG_ CAN_TX_TRACK_MOVABLE_SLOW61 m8 : 46|1@0+ (1,0) [0|1] "" Vector__XXX
 SG_ CAN_TX_TRACK_MOVABLE_SLOW60 m8 : 38|1@0+ (1,0) [0|1] "" Vector__XXX
 SG_ CAN_TX_TRACK_MOVABLE_SLOW59 m8 : 30|1@0+ (1,0) [0|1] "" Vector__XXX
 SG_ CAN_TX_TRACK_MOVABLE_SLOW58 m8 : 22|1@0+ (1,0) [0|1] "" Vector__XXX
 SG_ CAN_TX_TRACK_MOVABLE_SLOW57 m8 : 14|1@0+ (1,0) [0|1] "" Vector__XXX
 SG_ CAN_TX_TRACK_POWER63 m8 : 60|5@0+ (1,-10) [-10|21] "dB" Vector__XXX
 SG_ CAN_TX_TRACK_POWER62 m8 : 52|5@0+ (1,-10) [-10|21] "dB" Vector__XXX
 SG_ CAN_TX_TRACK_POWER61 m8 : 44|5@0+ (1,-10) [-10|21] "dB" Vector__XXX
 SG_ CAN_TX_TRACK_POWER60 m8 : 36|5@0+ (1,-10) [-10|21] "dB" Vector__XXX
 SG_ CAN_TX_TRACK_POWER59 m8 : 28|5@0+ (1,-10) [-10|21] "dB" Vector__XXX
 SG_ CAN_TX_TRACK_POWER58 m8 : 20|5@0+ (1,-10) [-10|21] "dB" Vector__XXX
 SG_ CAN_TX_TRACK_POWER57 m8 : 12|5@0+ (1,-10) [-10|21] "dB" Vector__XXX
 SG_ CAN_TX_TRACK_MOVING63 m8 : 61|1@0+ (1,0) [0|1] "" Vector__XXX
 SG_ CAN_TX_TRACK_MOVING62 m8 : 53|1@0+ (1,0) [0|1] "" Vector__XXX
 SG_ CAN_TX_TRACK_MOVING61 m8 : 45|1@0+ (1,0) [0|1] "" Vector__XXX
 SG_ CAN_TX_TRACK_MOVING60 m8 : 37|1@0+ (1,0) [0|1] "" Vector__XXX
 SG_ CAN_TX_TRACK_MOVING59 m8 : 29|1@0+ (1,0) [0|1] "" Vector__XXX
 SG_ CAN_TX_TRACK_MOVING58 m8 : 21|1@0+ (1,0) [0|1] "" Vector__XXX
 SG_ CAN_TX_TRACK_MOVING57 m8 : 13|1@0+ (1,0) [0|1] "" Vector__XXX
 SG_ CAN_TX_TRACK_MOVABLE_FAST63 m8 : 63|1@0+ (1,0) [0|1] "" Vector__XXX
 SG_ CAN_TX_TRACK_MOVABLE_FAST62 m8 : 55|1@0+ (1,0) [0|1] "" Vector__XXX
 SG_ CAN_TX_TRACK_MOVABLE_FAST61 m8 : 47|1@0+ (1,0) [0|1] "" Vector__XXX
 SG_ CAN_TX_TRACK_MOVABLE_FAST60 m8 : 39|1@0+ (1,0) [0|1] "" Vector__XXX
 SG_ CAN_TX_TRACK_MOVABLE_FAST59 m8 : 31|1@0+ (1,0) [0|1] "" Vector__XXX
 SG_ CAN_TX_TRACK_MOVABLE_FAST58 m8 : 23|1@0+ (1,0) [0|1] "" Vector__XXX
 SG_ CAN_TX_TRACK_MOVABLE_FAST57 m8 : 15|1@0+ (1,0) [0|1] "" Vector__XXX
 SG_ CAN_TX_TRACK_MOVABLE_SLOW56 m7 : 62|1@0+ (1,0) [0|1] "" Vector__XXX
 SG_ CAN_TX_TRACK_MOVABLE_SLOW55 m7 : 54|1@0+ (1,0) [0|1] "" Vector__XXX
 SG_ CAN_TX_TRACK_MOVABLE_SLOW54 m7 : 46|1@0+ (1,0) [0|1] "" Vector__XXX
 SG_ CAN_TX_TRACK_MOVABLE_SLOW53 m7 : 38|1@0+ (1,0) [0|1] "" Vector__XXX
 SG_ CAN_TX_TRACK_MOVABLE_SLOW52 m7 : 30|1@0+ (1,0) [0|1] "" Vector__XXX
 SG_ CAN_TX_TRACK_MOVABLE_SLOW51 m7 : 22|1@0+ (1,0) [0|1] "" Vector__XXX
 SG_ CAN_TX_TRACK_MOVABLE_SLOW50 m7 : 14|1@0+ (1,0) [0|1] "" Vector__XXX
 SG_ CAN_TX_TRACK_POWER56 m7 : 60|5@0+ (1,-10) [-10|21] "dB" Vector__XXX
 SG_ CAN_TX_TRACK_POWER55 m7 : 52|5@0+ (1,-10) [-10|21] "dB" Vector__XXX
 SG_ CAN_TX_TRACK_POWER54 m7 : 44|5@0+ (1,-10) [-10|21] "dB" Vector__XXX
 SG_ CAN_TX_TRACK_POWER53 m7 : 36|5@0+ (1,-10) [-10|21] "dB" Vector__XXX
 SG_ CAN_TX_TRACK_POWER52 m7 : 28|5@0+ (1,-10) [-10|21] "dB" Vector__XXX
 SG_ CAN_TX_TRACK_POWER51 m7 : 20|5@0+ (1,-10) [-10|21] "dB" Vector__XXX
 SG_ CAN_TX_TRACK_POWER50 m7 : 12|5@0+ (1,-10) [-10|21] "dB" Vector__XXX
 SG_ CAN_TX_TRACK_MOVING56 m7 : 61|1@0+ (1,0) [0|1] "" Vector__XXX
 SG_ CAN_TX_TRACK_MOVING55 m7 : 53|1@0+ (1,0) [0|1] "" Vector__XXX
 SG_ CAN_TX_TRACK_MOVING54 m7 : 45|1@0+ (1,0) [0|1] "" Vector__XXX
 SG_ CAN_TX_TRACK_MOVING53 m7 : 37|1@0+ (1,0) [0|1] "" Vector__XXX
 SG_ CAN_TX_TRACK_MOVING52 m7 : 29|1@0+ (1,0) [0|1] "" Vector__XXX
 SG_ CAN_TX_TRACK_MOVING51 m7 : 21|1@0+ (1,0) [0|1] "" Vector__XXX
 SG_ CAN_TX_TRACK_MOVING50 m7 : 13|1@0+ (1,0) [0|1] "" Vector__XXX
 SG_ CAN_TX_TRACK_MOVABLE_FAST56 m7 : 63|1@0+ (1,0) [0|1] "" Vector__XXX
 SG_ CAN_TX_TRACK_MOVABLE_FAST55 m7 : 55|1@0+ (1,0) [0|1] "" Vector__XXX
 SG_ CAN_TX_TRACK_MOVABLE_FAST54 m7 : 47|1@0+ (1,0) [0|1] "" Vector__XXX
 SG_ CAN_TX_TRACK_MOVABLE_FAST53 m7 : 39|1@0+ (1,0) [0|1] "" Vector__XXX
 SG_ CAN_TX_TRACK_MOVABLE_FAST52 m7 : 31|1@0+ (1,0) [0|1] "" Vector__XXX
 SG_ CAN_TX_TRACK_MOVABLE_FAST51 m7 : 23|1@0+ (1,0) [0|1] "" Vector__XXX
 SG_ CAN_TX_TRACK_MOVABLE_FAST50 m7 : 15|1@0+ (1,0) [0|1] "" Vector__XXX
 SG_ CAN_TX_TRACK_MOVABLE_SLOW49 m6 : 62|1@0+ (1,0) [0|1] "" Vector__XXX
 SG_ CAN_TX_TRACK_MOVABLE_SLOW48 m6 : 54|1@0+ (1,0) [0|1] "" Vector__XXX
 SG_ CAN_TX_TRACK_MOVABLE_SLOW47 m6 : 46|1@0+ (1,0) [0|1] "" Vector__XXX
 SG_ CAN_TX_TRACK_MOVABLE_SLOW46 m6 : 38|1@0+ (1,0) [0|1] "" Vector__XXX
 SG_ CAN_TX_TRACK_MOVABLE_SLOW45 m6 : 30|1@0+ (1,0) [0|1] "" Vector__XXX
 SG_ CAN_TX_TRACK_MOVABLE_SLOW44 m6 : 22|1@0+ (1,0) [0|1] "" Vector__XXX
 SG_ CAN_TX_TRACK_MOVABLE_SLOW43 m6 : 14|1@0+ (1,0) [0|1] "" Vector__XXX
 SG_ CAN_TX_TRACK_POWER49 m6 : 60|5@0+ (1,-10) [-10|21] "dB" Vector__XXX
 SG_ CAN_TX_TRACK_POWER48 m6 : 52|5@0+ (1,-10) [-10|21] "dB" Vector__XXX
 SG_ CAN_TX_TRACK_POWER47 m6 : 44|5@0+ (1,-10) [-10|21] "dB" Vector__XXX
 SG_ CAN_TX_TRACK_POWER46 m6 : 36|5@0+ (1,-10) [-10|21] "dB" Vector__XXX
 SG_ CAN_TX_TRACK_POWER45 m6 : 28|5@0+ (1,-10) [-10|21] "dB" Vector__XXX
 SG_ CAN_TX_TRACK_POWER44 m6 : 20|5@0+ (1,-10) [-10|21] "dB" Vector__XXX
 SG_ CAN_TX_TRACK_POWER43 m6 : 12|5@0+ (1,-10) [-10|21] "dB" Vector__XXX
 SG_ CAN_TX_TRACK_MOVING49 m6 : 61|1@0+ (1,0) [0|1] "" Vector__XXX
 SG_ CAN_TX_TRACK_MOVING48 m6 : 53|1@0+ (1,0) [0|1] "" Vector__XXX
 SG_ CAN_TX_TRACK_MOVING47 m6 : 45|1@0+ (1,0) [0|1] "" Vector__XXX
 SG_ CAN_TX_TRACK_MOVING46 m6 : 37|1@0+ (1,0) [0|1] "" Vector__XXX
 SG_ CAN_TX_TRACK_MOVING45 m6 : 29|1@0+ (1,0) [0|1] "" Vector__XXX
 SG_ CAN_TX_TRACK_MOVING44 m6 : 21|1@0+ (1,0) [0|1] "" Vector__XXX
 SG_ CAN_TX_TRACK_MOVING43 m6 : 13|1@0+ (1,0) [0|1] "" Vector__XXX
 SG_ CAN_TX_TRACK_MOVABLE_FAST49 m6 : 63|1@0+ (1,0) [0|1] "" Vector__XXX
 SG_ CAN_TX_TRACK_MOVABLE_FAST48 m6 : 55|1@0+ (1,0) [0|1] "" Vector__XXX
 SG_ CAN_TX_TRACK_MOVABLE_FAST47 m6 : 47|1@0+ (1,0) [0|1] "" Vector__XXX
 SG_ CAN_TX_TRACK_MOVABLE_FAST46 m6 : 39|1@0+ (1,0) [0|1] "" Vector__XXX
 SG_ CAN_TX_TRACK_MOVABLE_FAST45 m6 : 31|1@0+ (1,0) [0|1] "" Vector__XXX
 SG_ CAN_TX_TRACK_MOVABLE_FAST44 m6 : 23|1@0+ (1,0) [0|1] "" Vector__XXX
 SG_ CAN_TX_TRACK_MOVABLE_FAST43 m6 : 15|1@0+ (1,0) [0|1] "" Vector__XXX
 SG_ CAN_TX_TRACK_MOVABLE_SLOW42 m5 : 62|1@0+ (1,0) [0|1] "" Vector__XXX
 SG_ CAN_TX_TRACK_MOVABLE_SLOW41 m5 : 54|1@0+ (1,0) [0|1] "" Vector__XXX
 SG_ CAN_TX_TRACK_MOVABLE_SLOW40 m5 : 46|1@0+ (1,0) [0|1] "" Vector__XXX
 SG_ CAN_TX_TRACK_MOVABLE_SLOW39 m5 : 38|1@0+ (1,0) [0|1] "" Vector__XXX
 SG_ CAN_TX_TRACK_MOVABLE_SLOW38 m5 : 30|1@0+ (1,0) [0|1] "" Vector__XXX
 SG_ CAN_TX_TRACK_MOVABLE_SLOW37 m5 : 22|1@0+ (1,0) [0|1] "" Vector__XXX
 SG_ CAN_TX_TRACK_MOVABLE_SLOW36 m5 : 14|1@0+ (1,0) [0|1] "" Vector__XXX
 SG_ CAN_TX_TRACK_POWER42 m5 : 60|5@0+ (1,-10) [-10|21] "dB" Vector__XXX
 SG_ CAN_TX_TRACK_POWER41 m5 : 52|5@0+ (1,-10) [-10|21] "dB" Vector__XXX
 SG_ CAN_TX_TRACK_POWER40 m5 : 44|5@0+ (1,-10) [-10|21] "dB" Vector__XXX
 SG_ CAN_TX_TRACK_POWER39 m5 : 36|5@0+ (1,-10) [-10|21] "dB" Vector__XXX
 SG_ CAN_TX_TRACK_POWER38 m5 : 28|5@0+ (1,-10) [-10|21] "dB" Vector__XXX
 SG_ CAN_TX_TRACK_POWER37 m5 : 20|5@0+ (1,-10) [-10|21] "dB" Vector__XXX
 SG_ CAN_TX_TRACK_POWER36 m5 : 12|5@0+ (1,-10) [-10|21] "dB" Vector__XXX
 SG_ CAN_TX_TRACK_MOVING42 m5 : 61|1@0+ (1,0) [0|1] "" Vector__XXX
 SG_ CAN_TX_TRACK_MOVING41 m5 : 53|1@0+ (1,0) [0|1] "" Vector__XXX
 SG_ CAN_TX_TRACK_MOVING40 m5 : 45|1@0+ (1,0) [0|1] "" Vector__XXX
 SG_ CAN_TX_TRACK_MOVING39 m5 : 37|1@0+ (1,0) [0|1] "" Vector__XXX
 SG_ CAN_TX_TRACK_MOVING38 m5 : 29|1@0+ (1,0) [0|1] "" Vector__XXX
 SG_ CAN_TX_TRACK_MOVING37 m5 : 21|1@0+ (1,0) [0|1] "" Vector__XXX
 SG_ CAN_TX_TRACK_MOVING36 m5 : 13|1@0+ (1,0) [0|1] "" Vector__XXX
 SG_ CAN_TX_TRACK_MOVABLE_FAST42 m5 : 63|1@0+ (1,0) [0|1] "" Vector__XXX
 SG_ CAN_TX_TRACK_MOVABLE_FAST41 m5 : 55|1@0+ (1,0) [0|1] "" Vector__XXX
 SG_ CAN_TX_TRACK_MOVABLE_FAST40 m5 : 47|1@0+ (1,0) [0|1] "" Vector__XXX
 SG_ CAN_TX_TRACK_MOVABLE_FAST39 m5 : 39|1@0+ (1,0) [0|1] "" Vector__XXX
 SG_ CAN_TX_TRACK_MOVABLE_FAST38 m5 : 31|1@0+ (1,0) [0|1] "" Vector__XXX
 SG_ CAN_TX_TRACK_MOVABLE_FAST37 m5 : 23|1@0+ (1,0) [0|1] "" Vector__XXX
 SG_ CAN_TX_TRACK_MOVABLE_FAST36 m5 : 15|1@0+ (1,0) [0|1] "" Vector__XXX
 SG_ CAN_TX_TRACK_MOVABLE_SLOW35 m4 : 62|1@0+ (1,0) [0|1] "" Vector__XXX
 SG_ CAN_TX_TRACK_MOVABLE_SLOW34 m4 : 54|1@0+ (1,0) [0|1] "" Vector__XXX
 SG_ CAN_TX_TRACK_MOVABLE_SLOW33 m4 : 46|1@0+ (1,0) [0|1] "" Vector__XXX
 SG_ CAN_TX_TRACK_MOVABLE_SLOW32 m4 : 38|1@0+ (1,0) [0|1] "" Vector__XXX
 SG_ CAN_TX_TRACK_MOVABLE_SLOW31 m4 : 30|1@0+ (1,0) [0|1] "" Vector__XXX
 SG_ CAN_TX_TRACK_MOVABLE_SLOW30 m4 : 22|1@0+ (1,0) [0|1] "" Vector__XXX
 SG_ CAN_TX_TRACK_MOVABLE_SLOW29 m4 : 14|1@0+ (1,0) [0|1] "" Vector__XXX
 SG_ CAN_TX_TRACK_POWER35 m4 : 60|5@0+ (1,-10) [-10|21] "dB" Vector__XXX
 SG_ CAN_TX_TRACK_POWER34 m4 : 52|5@0+ (1,-10) [-10|21] "dB" Vector__XXX
 SG_ CAN_TX_TRACK_POWER33 m4 : 44|5@0+ (1,-10) [-10|21] "dB" Vector__XXX
 SG_ CAN_TX_TRACK_POWER32 m4 : 36|5@0+ (1,-10) [-10|21] "dB" Vector__XXX
 SG_ CAN_TX_TRACK_POWER31 m4 : 28|5@0+ (1,-10) [-10|21] "dB" Vector__XXX
 SG_ CAN_TX_TRACK_POWER30 m4 : 20|5@0+ (1,-10) [-10|21] "dB" Vector__XXX
 SG_ CAN_TX_TRACK_POWER29 m4 : 12|5@0+ (1,-10) [-10|21] "dB" Vector__XXX
 SG_ CAN_TX_TRACK_MOVING35 m4 : 61|1@0+ (1,0) [0|1] "" Vector__XXX
 SG_ CAN_TX_TRACK_MOVING34 m4 : 53|1@0+ (1,0) [0|1] "" Vector__XXX
 SG_ CAN_TX_TRACK_MOVING33 m4 : 45|1@0+ (1,0) [0|1] "" Vector__XXX
 SG_ CAN_TX_TRACK_MOVING32 m4 : 37|1@0+ (1,0) [0|1] "" Vector__XXX
 SG_ CAN_TX_TRACK_MOVING31 m4 : 29|1@0+ (1,0) [0|1] "" Vector__XXX
 SG_ CAN_TX_TRACK_MOVING30 m4 : 21|1@0+ (1,0) [0|1] "" Vector__XXX
 SG_ CAN_TX_TRACK_MOVING29 m4 : 13|1@0+ (1,0) [0|1] "" Vector__XXX
 SG_ CAN_TX_TRACK_MOVABLE_FAST35 m4 : 63|1@0+ (1,0) [0|1] "" Vector__XXX
 SG_ CAN_TX_TRACK_MOVABLE_FAST34 m4 : 55|1@0+ (1,0) [0|1] "" Vector__XXX
 SG_ CAN_TX_TRACK_MOVABLE_FAST33 m4 : 47|1@0+ (1,0) [0|1] "" Vector__XXX
 SG_ CAN_TX_TRACK_MOVABLE_FAST32 m4 : 39|1@0+ (1,0) [0|1] "" Vector__XXX
 SG_ CAN_TX_TRACK_MOVABLE_FAST31 m4 : 31|1@0+ (1,0) [0|1] "" Vector__XXX
 SG_ CAN_TX_TRACK_MOVABLE_FAST30 m4 : 23|1@0+ (1,0) [0|1] "" Vector__XXX
 SG_ CAN_TX_TRACK_MOVABLE_FAST29 m4 : 15|1@0+ (1,0) [0|1] "" Vector__XXX
 SG_ CAN_TX_TRACK_MOVABLE_SLOW28 m3 : 62|1@0+ (1,0) [0|1] "" Vector__XXX
 SG_ CAN_TX_TRACK_MOVABLE_SLOW27 m3 : 54|1@0+ (1,0) [0|1] "" Vector__XXX
 SG_ CAN_TX_TRACK_MOVABLE_SLOW26 m3 : 46|1@0+ (1,0) [0|1] "" Vector__XXX
 SG_ CAN_TX_TRACK_MOVABLE_SLOW25 m3 : 38|1@0+ (1,0) [0|1] "" Vector__XXX
 SG_ CAN_TX_TRACK_MOVABLE_SLOW24 m3 : 30|1@0+ (1,0) [0|1] "" Vector__XXX
 SG_ CAN_TX_TRACK_MOVABLE_SLOW23 m3 : 22|1@0+ (1,0) [0|1] "" Vector__XXX
 SG_ CAN_TX_TRACK_MOVABLE_SLOW22 m3 : 14|1@0+ (1,0) [0|1] "" Vector__XXX
 SG_ CAN_TX_TRACK_POWER28 m3 : 60|5@0+ (1,-10) [-10|21] "dB" Vector__XXX
 SG_ CAN_TX_TRACK_POWER27 m3 : 52|5@0+ (1,-10) [-10|21] "dB" Vector__XXX
 SG_ CAN_TX_TRACK_POWER26 m3 : 44|5@0+ (1,-10) [-10|21] "dB" Vector__XXX
 SG_ CAN_TX_TRACK_POWER25 m3 : 36|5@0+ (1,-10) [-10|21] "dB" Vector__XXX
 SG_ CAN_TX_TRACK_POWER24 m3 : 28|5@0+ (1,-10) [-10|21] "dB" Vector__XXX
 SG_ CAN_TX_TRACK_POWER23 m3 : 20|5@0+ (1,-10) [-10|21] "dB" Vector__XXX
 SG_ CAN_TX_TRACK_POWER22 m3 : 12|5@0+ (1,-10) [-10|21] "dB" Vector__XXX
 SG_ CAN_TX_TRACK_MOVING28 m3 : 61|1@0+ (1,0) [0|1] "" Vector__XXX
 SG_ CAN_TX_TRACK_MOVING27 m3 : 53|1@0+ (1,0) [0|1] "" Vector__XXX
 SG_ CAN_TX_TRACK_MOVING26 m3 : 45|1@0+ (1,0) [0|1] "" Vector__XXX
 SG_ CAN_TX_TRACK_MOVING25 m3 : 37|1@0+ (1,0) [0|1] "" Vector__XXX
 SG_ CAN_TX_TRACK_MOVING24 m3 : 29|1@0+ (1,0) [0|1] "" Vector__XXX
 SG_ CAN_TX_TRACK_MOVING23 m3 : 21|1@0+ (1,0) [0|1] "" Vector__XXX
 SG_ CAN_TX_TRACK_MOVING22 m3 : 13|1@0+ (1,0) [0|1] "" Vector__XXX
 SG_ CAN_TX_TRACK_MOVABLE_FAST28 m3 : 63|1@0+ (1,0) [0|1] "" Vector__XXX
 SG_ CAN_TX_TRACK_MOVABLE_FAST27 m3 : 55|1@0+ (1,0) [0|1] "" Vector__XXX
 SG_ CAN_TX_TRACK_MOVABLE_FAST26 m3 : 47|1@0+ (1,0) [0|1] "" Vector__XXX
 SG_ CAN_TX_TRACK_MOVABLE_FAST25 m3 : 39|1@0+ (1,0) [0|1] "" Vector__XXX
 SG_ CAN_TX_TRACK_MOVABLE_FAST24 m3 : 31|1@0+ (1,0) [0|1] "" Vector__XXX
 SG_ CAN_TX_TRACK_MOVABLE_FAST23 m3 : 23|1@0+ (1,0) [0|1] "" Vector__XXX
 SG_ CAN_TX_TRACK_MOVABLE_FAST22 m3 : 15|1@0+ (1,0) [0|1] "" Vector__XXX
 SG_ CAN_TX_TRACK_MOVABLE_SLOW21 m2 : 62|1@0+ (1,0) [0|1] "" Vector__XXX
 SG_ CAN_TX_TRACK_MOVABLE_SLOW20 m2 : 54|1@0+ (1,0) [0|1] "" Vector__XXX
 SG_ CAN_TX_TRACK_MOVABLE_SLOW19 m2 : 46|1@0+ (1,0) [0|1] "" Vector__XXX
 SG_ CAN_TX_TRACK_MOVABLE_SLOW18 m2 : 38|1@0+ (1,0) [0|1] "" Vector__XXX
 SG_ CAN_TX_TRACK_MOVABLE_SLOW17 m2 : 30|1@0+ (1,0) [0|1] "" Vector__XXX
 SG_ CAN_TX_TRACK_MOVABLE_SLOW16 m2 : 22|1@0+ (1,0) [0|1] "" Vector__XXX
 SG_ CAN_TX_TRACK_MOVABLE_SLOW15 m2 : 14|1@0+ (1,0) [0|1] "" Vector__XXX
 SG_ CAN_TX_TRACK_POWER21 m2 : 60|5@0+ (1,-10) [-10|21] "dB" Vector__XXX
 SG_ CAN_TX_TRACK_POWER20 m2 : 52|5@0+ (1,-10) [-10|21] "dB" Vector__XXX
 SG_ CAN_TX_TRACK_POWER19 m2 : 44|5@0+ (1,-10) [-10|21] "dB" Vector__XXX
 SG_ CAN_TX_TRACK_POWER18 m2 : 36|5@0+ (1,-10) [-10|21] "dB" Vector__XXX
 SG_ CAN_TX_TRACK_POWER17 m2 : 28|5@0+ (1,-10) [-10|21] "dB" Vector__XXX
 SG_ CAN_TX_TRACK_POWER16 m2 : 20|5@0+ (1,-10) [-10|21] "dB" Vector__XXX
 SG_ CAN_TX_TRACK_POWER15 m2 : 12|5@0+ (1,-10) [-10|21] "dB" Vector__XXX
 SG_ CAN_TX_TRACK_MOVING21 m2 : 61|1@0+ (1,0) [0|1] "" Vector__XXX
 SG_ CAN_TX_TRACK_MOVING20 m2 : 53|1@0+ (1,0) [0|1] "" Vector__XXX
 SG_ CAN_TX_TRACK_MOVING19 m2 : 45|1@0+ (1,0) [0|1] "" Vector__XXX
 SG_ CAN_TX_TRACK_MOVING18 m2 : 37|1@0+ (1,0) [0|1] "" Vector__XXX
 SG_ CAN_TX_TRACK_MOVING17 m2 : 29|1@0+ (1,0) [0|1] "" Vector__XXX
 SG_ CAN_TX_TRACK_MOVING16 m2 : 21|1@0+ (1,0) [0|1] "" Vector__XXX
 SG_ CAN_TX_TRACK_MOVING15 m2 : 13|1@0+ (1,0) [0|1] "" Vector__XXX
 SG_ CAN_TX_TRACK_MOVABLE_FAST21 m2 : 63|1@0+ (1,0) [0|1] "" Vector__XXX
 SG_ CAN_TX_TRACK_MOVABLE_FAST20 m2 : 55|1@0+ (1,0) [0|1] "" Vector__XXX
 SG_ CAN_TX_TRACK_MOVABLE_FAST19 m2 : 47|1@0+ (1,0) [0|1] "" Vector__XXX
 SG_ CAN_TX_TRACK_MOVABLE_FAST18 m2 : 39|1@0+ (1,0) [0|1] "" Vector__XXX
 SG_ CAN_TX_TRACK_MOVABLE_FAST17 m2 : 31|1@0+ (1,0) [0|1] "" Vector__XXX
 SG_ CAN_TX_TRACK_MOVABLE_FAST16 m2 : 23|1@0+ (1,0) [0|1] "" Vector__XXX
 SG_ CAN_TX_TRACK_MOVABLE_FAST15 m2 : 15|1@0+ (1,0) [0|1] "" Vector__XXX
 SG_ CAN_TX_TRACK_MOVABLE_SLOW14 m1 : 62|1@0+ (1,0) [0|1] "" Vector__XXX
 SG_ CAN_TX_TRACK_MOVABLE_SLOW13 m1 : 54|1@0+ (1,0) [0|1] "" Vector__XXX
 SG_ CAN_TX_TRACK_MOVABLE_SLOW12 m1 : 46|1@0+ (1,0) [0|1] "" Vector__XXX
 SG_ CAN_TX_TRACK_MOVABLE_SLOW11 m1 : 38|1@0+ (1,0) [0|1] "" Vector__XXX
 SG_ CAN_TX_TRACK_MOVABLE_SLOW10 m1 : 30|1@0+ (1,0) [0|1] "" Vector__XXX
 SG_ CAN_TX_TRACK_MOVABLE_SLOW09 m1 : 22|1@0+ (1,0) [0|1] "" Vector__XXX
 SG_ CAN_TX_TRACK_MOVABLE_SLOW08 m1 : 14|1@0+ (1,0) [0|1] "" Vector__XXX
 SG_ CAN_TX_TRACK_POWER14 m1 : 60|5@0+ (1,-10) [-10|21] "dB" Vector__XXX
 SG_ CAN_TX_TRACK_POWER13 m1 : 52|5@0+ (1,-10) [-10|21] "dB" Vector__XXX
 SG_ CAN_TX_TRACK_POWER12 m1 : 44|5@0+ (1,-10) [-10|21] "dB" Vector__XXX
 SG_ CAN_TX_TRACK_POWER11 m1 : 36|5@0+ (1,-10) [-10|21] "dB" Vector__XXX
 SG_ CAN_TX_TRACK_POWER10 m1 : 28|5@0+ (1,-10) [-10|21] "dB" Vector__XXX
 SG_ CAN_TX_TRACK_POWER09 m1 : 20|5@0+ (1,-10) [-10|21] "dB" Vector__XXX
 SG_ CAN_TX_TRACK_POWER08 m1 : 12|5@0+ (1,-10) [-10|21] "dB" Vector__XXX
 SG_ CAN_TX_TRACK_MOVING14 m1 : 61|1@0+ (1,0) [0|1] "" Vector__XXX
 SG_ CAN_TX_TRACK_MOVING13 m1 : 53|1@0+ (1,0) [0|1] "" Vector__XXX
 SG_ CAN_TX_TRACK_MOVING12 m1 : 45|1@0+ (1,0) [0|1] "" Vector__XXX
 SG_ CAN_TX_TRACK_MOVING11 m1 : 37|1@0+ (1,0) [0|1] "" Vector__XXX
 SG_ CAN_TX_TRACK_MOVING10 m1 : 29|1@0+ (1,0) [0|1] "" Vector__XXX
 SG_ CAN_TX_TRACK_MOVING09 m1 : 21|1@0+ (1,0) [0|1] "" Vector__XXX
 SG_ CAN_TX_TRACK_MOVING08 m1 : 13|1@0+ (1,0) [0|1] "" Vector__XXX
 SG_ CAN_TX_TRACK_MOVABLE_FAST14 m1 : 63|1@0+ (1,0) [0|1] "" Vector__XXX
 SG_ CAN_TX_TRACK_MOVABLE_FAST13 m1 : 55|1@0+ (1,0) [0|1] "" Vector__XXX
 SG_ CAN_TX_TRACK_MOVABLE_FAST12 m1 : 47|1@0+ (1,0) [0|1] "" Vector__XXX
 SG_ CAN_TX_TRACK_MOVABLE_FAST11 m1 : 39|1@0+ (1,0) [0|1] "" Vector__XXX
 SG_ CAN_TX_TRACK_MOVABLE_FAST10 m1 : 31|1@0+ (1,0) [0|1] "" Vector__XXX
 SG_ CAN_TX_TRACK_MOVABLE_FAST09 m1 : 23|1@0+ (1,0) [0|1] "" Vector__XXX
 SG_ CAN_TX_TRACK_MOVABLE_FAST08 m1 : 15|1@0+ (1,0) [0|1] "" Vector__XXX
 SG_ CAN_TX_TRACK_ROLLING_COUNT_2 : 4|1@0+ (1,0) [0|1] "" Vector__XXX
 SG_ CAN_TX_TRACK_POWER07 m0 : 60|5@0+ (1,-10) [-10|21] "dB" Vector__XXX
 SG_ CAN_TX_TRACK_POWER06 m0 : 52|5@0+ (1,-10) [-10|21] "dB" Vector__XXX
 SG_ CAN_TX_TRACK_POWER05 m0 : 44|5@0+ (1,-10) [-10|21] "dB" Vector__XXX
 SG_ CAN_TX_TRACK_POWER04 m0 : 36|5@0+ (1,-10) [-10|21] "dB" Vector__XXX
 SG_ CAN_TX_TRACK_POWER03 m0 : 28|5@0+ (1,-10) [-10|21] "dB" Vector__XXX
 SG_ CAN_TX_TRACK_POWER02 m0 : 20|5@0+ (1,-10) [-10|21] "dB" Vector__XXX
 SG_ CAN_TX_TRACK_POWER01 m0 : 12|5@0+ (1,-10) [-10|21] "dB" Vector__XXX
 SG_ CAN_TX_TRACK_MOVING07 m0 : 61|1@0+ (1,0) [0|1] "" Vector__XXX
 SG_ CAN_TX_TRACK_MOVING06 m0 : 53|1@0+ (1,0) [0|1] "" Vector__XXX
 SG_ CAN_TX_TRACK_MOVING05 m0 : 45|1@0+ (1,0) [0|1] "" Vector__XXX
 SG_ CAN_TX_TRACK_MOVING04 m0 : 37|1@0+ (1,0) [0|1] "" Vector__XXX
 SG_ CAN_TX_TRACK_MOVING03 m0 : 29|1@0+ (1,0) [0|1] "" Vector__XXX
 SG_ CAN_TX_TRACK_MOVING02 m0 : 21|1@0+ (1,0) [0|1] "" Vector__XXX
 SG_ CAN_TX_TRACK_MOVING01 m0 : 13|1@0+ (1,0) [0|1] "" Vector__XXX
 SG_ CAN_TX_TRACK_MOVABLE_SLOW07 m0 : 62|1@0+ (1,0) [0|1] "" Vector__XXX
 SG_ CAN_TX_TRACK_MOVABLE_SLOW06 m0 : 54|1@0+ (1,0) [0|1] "" Vector__XXX
 SG_ CAN_TX_TRACK_MOVABLE_SLOW05 m0 : 46|1@0+ (1,0) [0|1] "" Vector__XXX
 SG_ CAN_TX_TRACK_MOVABLE_SLOW04 m0 : 38|1@0+ (1,0) [0|1] "" Vector__XXX
 SG_ CAN_TX_TRACK_MOVABLE_SLOW03 m0 : 30|1@0+ (1,0) [0|1] "" Vector__XXX
 SG_ CAN_TX_TRACK_MOVABLE_SLOW02 m0 : 22|1@0+ (1,0) [0|1] "" Vector__XXX
 SG_ CAN_TX_TRACK_MOVABLE_SLOW01 m0 : 14|1@0+ (1,0) [0|1] "" Vector__XXX
 SG_ CAN_TX_TRACK_MOVABLE_FAST07 m0 : 63|1@0+ (1,0) [0|1] "" Vector__XXX
 SG_ CAN_TX_TRACK_MOVABLE_FAST06 m0 : 55|1@0+ (1,0) [0|1] "" Vector__XXX
 SG_ CAN_TX_TRACK_MOVABLE_FAST05 m0 : 47|1@0+ (1,0) [0|1] "" Vector__XXX
 SG_ CAN_TX_TRACK_MOVABLE_FAST04 m0 : 39|1@0+ (1,0) [0|1] "" Vector__XXX
 SG_ CAN_TX_TRACK_MOVABLE_FAST03 m0 : 31|1@0+ (1,0) [0|1] "" Vector__XXX
 SG_ CAN_TX_TRACK_MOVABLE_FAST02 m0 : 23|1@0+ (1,0) [0|1] "" Vector__XXX
 SG_ CAN_TX_TRACK_MOVABLE_FAST01 m0 : 15|1@0+ (1,0) [0|1] "" Vector__XXX
 SG_ CAN_TX_TRACK_CAN_ID_GROUP M : 3|4@0+ (1,0) [0|9] "" Vector__XXX

BO_ 1251 ESR_Status4: 8 ESR
 SG_ CAN_TX_TRUCK_TARGET_DET : 7|1@0+ (1,0) [0|0] "" Vector__XXX
 SG_ CAN_TX_LR_ONLY_GRATING_LOBE_DET : 6|1@0+ (1,0) [0|0] "" Vector__XXX
 SG_ CAN_TX_SIDELOBE_BLOCKAGE : 5|1@0+ (1,0) [0|0] "" Vector__XXX
 SG_ CAN_TX_PARTIAL_BLOCKAGE : 4|1@0+ (1,0) [0|0] "" Vector__XXX
 SG_ CAN_TX_PATH_ID_ACC_STAT : 63|8@0+ (1,0) [0|0] "" Vector__XXX
 SG_ CAN_TX_MR_LR_MODE : 3|2@0+ (1,0) [0|3] "" Vector__XXX
 SG_ CAN_TX_AUTO_ALIGN_ANGLE : 55|8@0- (0.0625,0) [-8|7.9375] "" Vector__XXX
 SG_ CAN_TX_ROLLING_COUNT_3 : 1|2@0+ (1,0) [0|0] "" Vector__XXX
 SG_ CAN_TX_PATH_ID_FCW_STAT : 47|8@0+ (1,0) [0|0] "" Vector__XXX
 SG_ CAN_TX_PATH_ID_FCW_MOVE : 39|8@0+ (1,0) [0|0] "" Vector__XXX
 SG_ CAN_TX_PATH_ID_CMBB_STAT : 31|8@0+ (1,0) [0|0] "" Vector__XXX
 SG_ CAN_TX_PATH_ID_CMBB_MOVE : 23|8@0+ (1,0) [0|0] "" Vector__XXX
 SG_ CAN_TX_PATH_ID_ACC : 15|8@0+ (1,0) [0|0] "" Vector__XXX

BO_ 1489 ESR_Valid2: 8 ESR
 SG_ CAN_TX_VALID_MR_SN : 7|8@0+ (1,0) [0|0] "" Vector__XXX
 SG_ CAN_TX_VALID_MR_RANGE_RATE : 31|16@0- (0.0078125,0) [-128|127] "m/s" Vector__XXX
 SG_ CAN_TX_VALID_MR_RANGE : 15|16@0+ (0.0078125,0) [0|200] "m" Vector__XXX
 SG_ CAN_TX_VALID_MR_POWER : 63|8@0- (1,0) [-10|40] "dB" Vector__XXX
 SG_ CAN_TX_VALID_MR_ANGLE : 47|16@0- (0.0625,0) [-64|63.9375] "deg" Vector__XXX

BO_ 1488 ESR_Valid1: 8 ESR
 SG_ CAN_TX_VALID_LR_SN : 7|8@0+ (1,0) [0|0] "" Vector__XXX
 SG_ CAN_TX_VALID_LR_RANGE_RATE : 31|16@0- (0.0078125,0) [-128|127] "m/s" Vector__XXX
 SG_ CAN_TX_VALID_LR_RANGE : 15|16@0+ (0.0078125,0) [0|200] "m" Vector__XXX
 SG_ CAN_TX_VALID_LR_POWER : 63|8@0- (1,0) [-10|40] "dB" Vector__XXX
 SG_ CAN_TX_VALID_LR_ANGLE : 47|16@0- (0.0625,0) [-64|63.9375] "deg" Vector__XXX

BO_ 1250 ESR_Status3: 8 ESR
 SG_ CAN_TX_SW_VERSION_PLD : 63|8@0+ (1,0) [0|0] "" Vector__XXX
 SG_ CAN_TX_SW_VERSION_HOST : 15|24@0+ (1,0) [0|0] "" Vector__XXX
 SG_ CAN_TX_HW_VERSION : 3|4@0+ (1,0) [0|0] "" Vector__XXX
 SG_ CAN_TX_INTERFACE_VERSION : 7|4@0+ (1,0) [0|0] "" Vector__XXX
 SG_ CAN_TX_SERIAL_NUM : 39|24@0+ (1,0) [0|0] "" Vector__XXX

BO_ 1280 ESR_Track01: 8 ESR
 SG_ CAN_TX_TRACK_GROUPING_CHANGED : 1|1@0+ (1,0) [0|0] "" Vector__XXX
 SG_ CAN_TX_TRACK_ONCOMING : 0|1@0+ (1,0) [0|0] "" Vector__XXX
 SG_ CAN_TX_TRACK_LAT_RATE : 7|6@0- (0.25,0) [-8|7.75] "" Vector__XXX
 SG_ CAN_TX_TRACK_BRIDGE_OBJECT : 39|1@0+ (1,0) [0|0] "" Vector__XXX
 SG_ CAN_TX_TRACK_STATUS : 15|3@0+ (1,0) [0|7] "" Vector__XXX
 SG_ CAN_TX_TRACK_ROLLING_COUNT : 38|1@0+ (1,0) [0|1] "" Vector__XXX
 SG_ CAN_TX_TRACK_RANGE_RATE : 53|14@0- (0.01,0) [-81.92|81.91] "m/s" Vector__XXX
 SG_ CAN_TX_TRACK_RANGE_ACCEL : 33|10@0- (0.05,0) [-25.6|25.55] "m/s/s" Vector__XXX
 SG_ CAN_TX_TRACK_RANGE : 18|11@0+ (0.1,0) [0|204.7] "m" Vector__XXX
 SG_ CAN_TX_TRACK_MED_RANGE_MODE : 55|2@0+ (1,0) [0|3] "" Vector__XXX
 SG_ CAN_TX_TRACK_ANGLE : 12|10@0- (0.1,0) [-51.2|51.1] "deg" Vector__XXX

BO_ 1249 ESR_Status2: 8 ESR
 SG_ CAN_TX_YAW_RATE_BIAS : 47|8@0- (0.125,0) [-16|15.875] "" Vector__XXX
 SG_ CAN_TX_VEH_SPD_COMP_FACTOR : 39|6@0- (0.00195313,1) [0.9375|1.06055] "" Vector__XXX
 SG_ CAN_TX_SW_VERSION_DSP : 55|16@0+ (1,0) [0|0] "" Vector__XXX
 SG_ CAN_TX_TEMPERATURE : 31|8@0- (1,0) [-128|127] "degC" Vector__XXX
 SG_ CAN_TX_RAW_DATA_MODE : 11|1@0+ (1,0) [0|0] "" Vector__XXX
 SG_ CAN_TX_RANGE_PERF_ERROR : 14|1@0+ (1,0) [0|0] "" Vector__XXX
 SG_ CAN_TX_OVERHEAT_ERROR : 15|1@0+ (1,0) [0|0] "" Vector__XXX
 SG_ CAN_TX_MAXIMUM_TRACKS_ACK : 7|6@0+ (1,1) [1|64] "" Vector__XXX
 SG_ CAN_TX_INTERNAL_ERROR : 13|1@0+ (1,0) [0|0] "" Vector__XXX
 SG_ CAN_TX_GROUPING_MODE : 33|2@0+ (1,0) [0|0] "" Vector__XXX
 SG_ CAN_TX_XCVR_OPERATIONAL : 12|1@0+ (1,0) [0|0] "" Vector__XXX
 SG_ CAN_TX_STEERING_ANGLE_ACK : 10|11@0+ (1,0) [0|2047] "deg" Vector__XXX
 SG_ CAN_TX_ROLLING_COUNT_2 : 1|2@0+ (1,0) [0|0] "" Vector__XXX

BO_ 1248 ESR_Status1: 8 ESR
 SG_ CAN_TX_DSP_TIMESTAMP : 5|7@0+ (2,0) [0|254] "ms" Vector__XXX
 SG_ CAN_TX_COMM_ERROR : 14|1@0+ (1,0) [0|0] "" Vector__XXX
 SG_ CAN_TX_YAW_RATE_CALC : 47|12@0- (0.0625,0) [-128|127.938] "deg/s" Vector__XXX
 SG_ CAN_TX_VEHICLE_SPEED_CALC : 50|11@0+ (0.0625,0) [0|127.938] "m/s" Vector__XXX
 SG_ CAN_TX_SCAN_INDEX : 31|16@0+ (1,0) [0|65535] "" Vector__XXX
 SG_ CAN_TX_ROLLING_COUNT_1 : 7|2@0+ (1,0) [0|0] "" Vector__XXX
 SG_ CAN_TX_RADIUS_CURVATURE_CALC : 13|14@0- (1,0) [-8192|8191] "m" Vector__XXX

BO_ 1265 Vehicle2: 8 Vehicle
 SG_ CAN_RX_VOLVO_SHORT_TRACK_ROC : 31|4@0- (500,0) [-4000|3500] "m" Vector__XXX
 SG_ CAN_RX_MR_ONLY_TRANSMIT : 25|1@0+ (1,0) [0|0] "" Vector__XXX
 SG_ CAN_RX_LR_ONLY_TRANSMIT : 24|1@0+ (1,0) [0|0] "" Vector__XXX
 SG_ CAN_RX_HIGH_YAW_ANGLE : 21|6@0- (1,0) [-32|31] "deg" Vector__XXX
 SG_ CAN_RX_CLEAR_FAULTS : 22|1@0+ (1,0) [0|0] "" Vector__XXX
 SG_ CAN_RX_USE_ANGLE_MISALIGNMENT : 23|1@0+ (1,0) [0|0] "" Vector__XXX
 SG_ CAN_RX_TURN_SIGNAL_STATUS : 63|2@0+ (1,0) [0|0] "" Vector__XXX
 SG_ CAN_RX_BLOCKAGE_DISABLE : 54|1@0+ (1,0) [0|0] "" Vector__XXX
 SG_ CAN_RX_VEHICLE_SPEED_VALIDITY : 61|1@0+ (1,0) [0|0] "" Vector__XXX
 SG_ CAN_RX_MMR_UPSIDE_DOWN : 60|1@0+ (1,0) [0|1] "" Vector__XXX
 SG_ CAN_RX_WIPER_STATUS : 57|1@0+ (1,0) [0|0] "" Vector__XXX
 SG_ CAN_RX_RADAR_CMD_RADIATE : 55|1@0+ (1,0) [0|0] "" Vector__XXX
 SG_ CAN_RX_GROUPING_MODE : 59|2@0+ (1,0) [0|3] "" Vector__XXX
 SG_ CAN_RX_MAXIMUM_TRACKS : 53|6@0+ (1,1) [1|64] "" Vector__XXX
 SG_ CAN_RX_LATERAL_MOUNTING_OFFSET : 47|8@0- (0.015625,0) [-2|1.98438] "m" Vector__XXX
 SG_ CAN_RX_ANGLE_MISALIGNMENT : 39|8@0- (0.0625,0) [-8|7.9375] "deg" Vector__XXX
 SG_ CAN_RX_SCAN_INDEX_ACK : 7|16@0+ (1,0) [0|65535] "" Vector__XXX

BO_ 1264 Vehicle1: 8 Vehicle
 SG_ CAN_RX_STEERING_ANGLE_VALIDITY : 47|1@0+ (1,0) [0|0] "" Vector__XXX
 SG_ CAN_RX_STEERING_ANGLE_RATE : 50|11@0+ (1,0) [0|2047] "deg/s" Vector__XXX
 SG_ CAN_RX_STEERING_ANGLE_SIGN : 46|1@0+ (1,0) [0|0] "" Vector__XXX
 SG_ CAN_RX_STEERING_ANGLE_RATE_SIGN : 30|1@0+ (1,0) [0|0] "" Vector__XXX
 SG_ CAN_RX_STEERING_ANGLE : 45|11@0+ (1,0) [0|2047] "deg" Vector__XXX
 SG_ CAN_RX_RADIUS_CURVATURE : 29|14@0- (1,0) [-8192|8191] "m" Vector__XXX
 SG_ CAN_RX_YAW_RATE_VALIDITY : 31|1@0+ (1,0) [0|0] "" Vector__XXX
 SG_ CAN_RX_YAW_RATE : 11|12@0- (0.0625,0) [-128|127.938] "deg/s" Vector__XXX
 SG_ CAN_RX_VEHICLE_SPEED_DIRECTION : 12|1@0+ (1,0) [0|0] "" Vector__XXX
 SG_ CAN_RX_VEHICLE_SPEED : 7|11@0+ (0.0625,0) [0|127.938] "m/s"  ESR

BO_ 611 TRACK_ADD_13: 8 NUC
 SG_ TRACK_SIZE_Y : 49|10@0+ (0.01,0) [0|10.23] "m" Vector__XXX
 SG_ TRACK_SIZE_X : 44|11@0+ (0.01,0) [0|20.47] "m" Vector__XXX
 SG_ TRACK_ORIENTATION : 25|13@0- (0.002,0) [-8.192|8.19] "rad" Vector__XXX
 SG_ TRACK_AY : 20|11@0- (0.01,0) [-10.24|10.23] "m/s^2" Vector__XXX
 SG_ TRACK_AX : 15|11@0- (0.01,0) [-10.24|10.23] "m/s^2" Vector__XXX
 SG_ TRACK_ID : 7|8@0+ (1,0) [0|255] "" Vector__XXX

BO_ 610 TRACK_ADD_12: 8 NUC
 SG_ TRACK_SIZE_Y : 49|10@0+ (0.01,0) [0|10.23] "m" Vector__XXX
 SG_ TRACK_SIZE_X : 44|11@0+ (0.01,0) [0|20.47] "m" Vector__XXX
 SG_ TRACK_ORIENTATION : 25|13@0- (0.002,0) [-8.192|8.19] "rad" Vector__XXX
 SG_ TRACK_AY : 20|11@0- (0.01,0) [-10.24|10.23] "m/s^2" Vector__XXX
 SG_ TRACK_AX : 15|11@0- (0.01,0) [-10.24|10.23] "m/s^2" Vector__XXX
 SG_ TRACK_ID : 7|8@0+ (1,0) [0|255] "" Vector__XXX

BO_ 609 TRACK_ADD_11: 8 NUC
 SG_ TRACK_SIZE_Y : 49|10@0+ (0.01,0) [0|10.23] "m" Vector__XXX
 SG_ TRACK_SIZE_X : 44|11@0+ (0.01,0) [0|20.47] "m" Vector__XXX
 SG_ TRACK_ORIENTATION : 25|13@0- (0.002,0) [-8.192|8.19] "rad" Vector__XXX
 SG_ TRACK_AY : 20|11@0- (0.01,0) [-10.24|10.23] "m/s^2" Vector__XXX
 SG_ TRACK_AX : 15|11@0- (0.01,0) [-10.24|10.23] "m/s^2" Vector__XXX
 SG_ TRACK_ID : 7|8@0+ (1,0) [0|255] "" Vector__XXX

BO_ 608 TRACK_ADD_10: 8 NUC
 SG_ TRACK_SIZE_Y : 49|10@0+ (0.01,0) [0|10.23] "m" Vector__XXX
 SG_ TRACK_SIZE_X : 44|11@0+ (0.01,0) [0|20.47] "m" Vector__XXX
 SG_ TRACK_ORIENTATION : 25|13@0- (0.002,0) [-8.192|8.19] "rad" Vector__XXX
 SG_ TRACK_AY : 20|11@0- (0.01,0) [-10.24|10.23] "m/s^2" Vector__XXX
 SG_ TRACK_AX : 15|11@0- (0.01,0) [-10.24|10.23] "m/s^2" Vector__XXX
 SG_ TRACK_ID : 7|8@0+ (1,0) [0|255] "" Vector__XXX

BO_ 601 TRACK_ADD_9: 8 NUC
 SG_ TRACK_SIZE_Y : 49|10@0+ (0.01,0) [0|10.23] "m" Vector__XXX
 SG_ TRACK_SIZE_X : 44|11@0+ (0.01,0) [0|20.47] "m" Vector__XXX
 SG_ TRACK_ORIENTATION : 25|13@0- (0.002,0) [-8.192|8.19] "rad" Vector__XXX
 SG_ TRACK_AY : 20|11@0- (0.01,0) [-10.24|10.23] "m/s^2" Vector__XXX
 SG_ TRACK_AX : 15|11@0- (0.01,0) [-10.24|10.23] "m/s^2" Vector__XXX
 SG_ TRACK_ID : 7|8@0+ (1,0) [0|255] "" Vector__XXX

BO_ 600 TRACK_ADD_8: 8 NUC
 SG_ TRACK_SIZE_Y : 49|10@0+ (0.01,0) [0|10.23] "m" Vector__XXX
 SG_ TRACK_SIZE_X : 44|11@0+ (0.01,0) [0|20.47] "m" Vector__XXX
 SG_ TRACK_ORIENTATION : 25|13@0- (0.002,0) [-8.192|8.19] "rad" Vector__XXX
 SG_ TRACK_AY : 20|11@0- (0.01,0) [-10.24|10.23] "m/s^2" Vector__XXX
 SG_ TRACK_AX : 15|11@0- (0.01,0) [-10.24|10.23] "m/s^2" Vector__XXX
 SG_ TRACK_ID : 7|8@0+ (1,0) [0|255] "" Vector__XXX

BO_ 599 TRACK_ADD_7: 8 NUC
 SG_ TRACK_SIZE_Y : 49|10@0+ (0.01,0) [0|10.23] "m" Vector__XXX
 SG_ TRACK_SIZE_X : 44|11@0+ (0.01,0) [0|20.47] "m" Vector__XXX
 SG_ TRACK_ORIENTATION : 25|13@0- (0.002,0) [-8.192|8.19] "rad" Vector__XXX
 SG_ TRACK_AY : 20|11@0- (0.01,0) [-10.24|10.23] "m/s^2" Vector__XXX
 SG_ TRACK_AX : 15|11@0- (0.01,0) [-10.24|10.23] "m/s^2" Vector__XXX
 SG_ TRACK_ID : 7|8@0+ (1,0) [0|255] "" Vector__XXX

BO_ 598 TRACK_ADD_6: 8 NUC
 SG_ TRACK_SIZE_Y : 49|10@0+ (0.01,0) [0|10.23] "m" Vector__XXX
 SG_ TRACK_SIZE_X : 44|11@0+ (0.01,0) [0|20.47] "m" Vector__XXX
 SG_ TRACK_ORIENTATION : 25|13@0- (0.002,0) [-8.192|8.19] "rad" Vector__XXX
 SG_ TRACK_AY : 20|11@0- (0.01,0) [-10.24|10.23] "m/s^2" Vector__XXX
 SG_ TRACK_AX : 15|11@0- (0.01,0) [-10.24|10.23] "m/s^2" Vector__XXX
 SG_ TRACK_ID : 7|8@0+ (1,0) [0|255] "" Vector__XXX

BO_ 597 TRACK_ADD_5: 8 NUC
 SG_ TRACK_SIZE_Y : 49|10@0+ (0.01,0) [0|10.23] "m" Vector__XXX
 SG_ TRACK_SIZE_X : 44|11@0+ (0.01,0) [0|20.47] "m" Vector__XXX
 SG_ TRACK_ORIENTATION : 25|13@0- (0.002,0) [-8.192|8.19] "rad" Vector__XXX
 SG_ TRACK_AY : 20|11@0- (0.01,0) [-10.24|10.23] "m/s^2" Vector__XXX
 SG_ TRACK_AX : 15|11@0- (0.01,0) [-10.24|10.23] "m/s^2" Vector__XXX
 SG_ TRACK_ID : 7|8@0+ (1,0) [0|255] "" Vector__XXX

BO_ 596 TRACK_ADD_4: 8 NUC
 SG_ TRACK_SIZE_Y : 49|10@0+ (0.01,0) [0|10.23] "m" Vector__XXX
 SG_ TRACK_SIZE_X : 44|11@0+ (0.01,0) [0|20.47] "m" Vector__XXX
 SG_ TRACK_ORIENTATION : 25|13@0- (0.002,0) [-8.192|8.19] "rad" Vector__XXX
 SG_ TRACK_AY : 20|11@0- (0.01,0) [-10.24|10.23] "m/s^2" Vector__XXX
 SG_ TRACK_AX : 15|11@0- (0.01,0) [-10.24|10.23] "m/s^2" Vector__XXX
 SG_ TRACK_ID : 7|8@0+ (1,0) [0|255] "" Vector__XXX

BO_ 595 TRACK_ADD_3: 8 NUC
 SG_ TRACK_SIZE_Y : 49|10@0+ (0.01,0) [0|10.23] "m" Vector__XXX
 SG_ TRACK_SIZE_X : 44|11@0+ (0.01,0) [0|20.47] "m" Vector__XXX
 SG_ TRACK_ORIENTATION : 25|13@0- (0.002,0) [-8.192|8.19] "rad" Vector__XXX
 SG_ TRACK_AY : 20|11@0- (0.01,0) [-10.24|10.23] "m/s^2" Vector__XXX
 SG_ TRACK_AX : 15|11@0- (0.01,0) [-10.24|10.23] "m/s^2" Vector__XXX
 SG_ TRACK_ID : 7|8@0+ (1,0) [0|255] "" Vector__XXX

BO_ 594 TRACK_ADD_2: 8 NUC
 SG_ TRACK_SIZE_Y : 49|10@0+ (0.01,0) [0|10.23] "m" Vector__XXX
 SG_ TRACK_SIZE_X : 44|11@0+ (0.01,0) [0|20.47] "m" Vector__XXX
 SG_ TRACK_ORIENTATION : 25|13@0- (0.002,0) [-8.192|8.19] "rad" Vector__XXX
 SG_ TRACK_AY : 20|11@0- (0.01,0) [-10.24|10.23] "m/s^2" Vector__XXX
 SG_ TRACK_AX : 15|11@0- (0.01,0) [-10.24|10.23] "m/s^2" Vector__XXX
 SG_ TRACK_ID : 7|8@0+ (1,0) [0|255] "" Vector__XXX

BO_ 593 TRACK_ADD_1: 8 NUC
 SG_ TRACK_SIZE_Y : 49|10@0+ (0.01,0) [0|10.23] "m" Vector__XXX
 SG_ TRACK_SIZE_X : 44|11@0+ (0.01,0) [0|20.47] "m" Vector__XXX
 SG_ TRACK_ORIENTATION : 25|13@0- (0.002,0) [-8.192|8.19] "rad" Vector__XXX
 SG_ TRACK_AY : 20|11@0- (0.01,0) [-10.24|10.23] "m/s^2" Vector__XXX
 SG_ TRACK_AX : 15|11@0- (0.01,0) [-10.24|10.23] "m/s^2" Vector__XXX
 SG_ TRACK_ID : 7|8@0+ (1,0) [0|255] "" Vector__XXX

BO_ 531 TRACK_13: 8 NUC
 SG_ TRACK_VY : 54|14@0- (0.01,0) [-81.92|81.91] "m/s" Vector__XXX
 SG_ TRACK_VX : 36|14@0- (0.01,0) [-81.92|81.91] "m/s" Vector__XXX
 SG_ TRACK_Y : 31|11@0- (0.04,0) [-40.9|40.9] "m" Vector__XXX
 SG_ TRACK_X : 11|12@0- (0.1,0) [-204.8|204.7] "m" Vector__XXX
 SG_ TRACK_STATUS : 15|4@0+ (1,0) [0|0] "" Vector__XXX
 SG_ TRACK_ID : 7|8@0+ (1,0) [0|255] "" Vector__XXX

BO_ 530 TRACK_12: 8 NUC
 SG_ TRACK_VY : 54|14@0- (0.01,0) [-81.92|81.91] "m/s" Vector__XXX
 SG_ TRACK_VX : 36|14@0- (0.01,0) [-81.92|81.91] "m/s" Vector__XXX
 SG_ TRACK_Y : 31|11@0- (0.04,0) [-40.9|40.9] "m" Vector__XXX
 SG_ TRACK_X : 11|12@0- (0.1,0) [-204.8|204.7] "m" Vector__XXX
 SG_ TRACK_STATUS : 15|4@0+ (1,0) [0|0] "" Vector__XXX
 SG_ TRACK_ID : 7|8@0+ (1,0) [0|255] "" Vector__XXX

BO_ 529 TRACK_11: 8 NUC
 SG_ TRACK_VY : 54|14@0- (0.01,0) [-81.92|81.91] "m/s" Vector__XXX
 SG_ TRACK_VX : 36|14@0- (0.01,0) [-81.92|81.91] "m/s" Vector__XXX
 SG_ TRACK_Y : 31|11@0- (0.04,0) [-40.9|40.9] "m" Vector__XXX
 SG_ TRACK_X : 11|12@0- (0.1,0) [-204.8|204.7] "m" Vector__XXX
 SG_ TRACK_STATUS : 15|4@0+ (1,0) [0|0] "" Vector__XXX
 SG_ TRACK_ID : 7|8@0+ (1,0) [0|255] "" Vector__XXX

BO_ 528 TRACK_10: 8 NUC
 SG_ TRACK_VY : 54|14@0- (0.01,0) [-81.92|81.91] "m/s" Vector__XXX
 SG_ TRACK_VX : 36|14@0- (0.01,0) [-81.92|81.91] "m/s" Vector__XXX
 SG_ TRACK_Y : 31|11@0- (0.04,0) [-40.9|40.9] "m" Vector__XXX
 SG_ TRACK_X : 11|12@0- (0.1,0) [-204.8|204.7] "m" Vector__XXX
 SG_ TRACK_STATUS : 15|4@0+ (1,0) [0|0] "" Vector__XXX
 SG_ TRACK_ID : 7|8@0+ (1,0) [0|255] "" Vector__XXX

BO_ 521 TRACK_9: 8 NUC
 SG_ TRACK_VY : 54|14@0- (0.01,0) [-81.92|81.91] "m/s" Vector__XXX
 SG_ TRACK_VX : 36|14@0- (0.01,0) [-81.92|81.91] "m/s" Vector__XXX
 SG_ TRACK_Y : 31|11@0- (0.04,0) [-40.9|40.9] "m" Vector__XXX
 SG_ TRACK_X : 11|12@0- (0.1,0) [-204.8|204.7] "m" Vector__XXX
 SG_ TRACK_STATUS : 15|4@0+ (1,0) [0|0] "" Vector__XXX
 SG_ TRACK_ID : 7|8@0+ (1,0) [0|255] "" Vector__XXX

BO_ 520 TRACK_8: 8 NUC
 SG_ TRACK_VY : 54|14@0- (0.01,0) [-81.92|81.91] "m/s" Vector__XXX
 SG_ TRACK_VX : 36|14@0- (0.01,0) [-81.92|81.91] "m/s" Vector__XXX
 SG_ TRACK_Y : 31|11@0- (0.04,0) [-40.9|40.9] "m" Vector__XXX
 SG_ TRACK_X : 11|12@0- (0.1,0) [-204.8|204.7] "m" Vector__XXX
 SG_ TRACK_STATUS : 15|4@0+ (1,0) [0|0] "" Vector__XXX
 SG_ TRACK_ID : 7|8@0+ (1,0) [0|255] "" Vector__XXX

BO_ 519 TRACK_7: 8 NUC
 SG_ TRACK_VY : 54|14@0- (0.01,0) [-81.92|81.91] "m/s" Vector__XXX
 SG_ TRACK_VX : 36|14@0- (0.01,0) [-81.92|81.91] "m/s" Vector__XXX
 SG_ TRACK_Y : 31|11@0- (0.04,0) [-40.9|40.9] "m" Vector__XXX
 SG_ TRACK_X : 11|12@0- (0.1,0) [-204.8|204.7] "m" Vector__XXX
 SG_ TRACK_STATUS : 15|4@0+ (1,0) [0|0] "" Vector__XXX
 SG_ TRACK_ID : 7|8@0+ (1,0) [0|255] "" Vector__XXX

BO_ 518 TRACK_6: 8 NUC
 SG_ TRACK_VY : 54|14@0- (0.01,0) [-81.92|81.91] "m/s" Vector__XXX
 SG_ TRACK_VX : 36|14@0- (0.01,0) [-81.92|81.91] "m/s" Vector__XXX
 SG_ TRACK_Y : 31|11@0- (0.04,0) [-40.9|40.9] "m" Vector__XXX
 SG_ TRACK_X : 11|12@0- (0.1,0) [-204.8|204.7] "m" Vector__XXX
 SG_ TRACK_STATUS : 15|4@0+ (1,0) [0|0] "" Vector__XXX
 SG_ TRACK_ID : 7|8@0+ (1,0) [0|255] "" Vector__XXX

BO_ 517 TRACK_5: 8 NUC
 SG_ TRACK_VY : 54|14@0- (0.01,0) [-81.92|81.91] "m/s" Vector__XXX
 SG_ TRACK_VX : 36|14@0- (0.01,0) [-81.92|81.91] "m/s" Vector__XXX
 SG_ TRACK_Y : 31|11@0- (0.04,0) [-40.9|40.9] "m" Vector__XXX
 SG_ TRACK_X : 11|12@0- (0.1,0) [-204.8|204.7] "m" Vector__XXX
 SG_ TRACK_STATUS : 15|4@0+ (1,0) [0|0] "" Vector__XXX
 SG_ TRACK_ID : 7|8@0+ (1,0) [0|255] "" Vector__XXX

BO_ 516 TRACK_4: 8 NUC
 SG_ TRACK_VY : 54|14@0- (0.01,0) [-81.92|81.91] "m/s" Vector__XXX
 SG_ TRACK_VX : 36|14@0- (0.01,0) [-81.92|81.91] "m/s" Vector__XXX
 SG_ TRACK_Y : 31|11@0- (0.04,0) [-40.9|40.9] "m" Vector__XXX
 SG_ TRACK_X : 11|12@0- (0.1,0) [-204.8|204.7] "m" Vector__XXX
 SG_ TRACK_STATUS : 15|4@0+ (1,0) [0|0] "" Vector__XXX
 SG_ TRACK_ID : 7|8@0+ (1,0) [0|255] "" Vector__XXX

BO_ 515 TRACK_3: 8 NUC
 SG_ TRACK_VY : 54|14@0- (0.01,0) [-81.92|81.91] "m/s" Vector__XXX
 SG_ TRACK_VX : 36|14@0- (0.01,0) [-81.92|81.91] "m/s" Vector__XXX
 SG_ TRACK_Y : 31|11@0- (0.04,0) [-40.9|40.9] "m" Vector__XXX
 SG_ TRACK_X : 11|12@0- (0.1,0) [-204.8|204.7] "m" Vector__XXX
 SG_ TRACK_STATUS : 15|4@0+ (1,0) [0|0] "" Vector__XXX
 SG_ TRACK_ID : 7|8@0+ (1,0) [0|255] "" Vector__XXX

BO_ 514 TRACK_2: 8 NUC
 SG_ TRACK_VY : 54|14@0- (0.01,0) [-81.92|81.91] "m/s" Vector__XXX
 SG_ TRACK_VX : 36|14@0- (0.01,0) [-81.92|81.91] "m/s" Vector__XXX
 SG_ TRACK_Y : 31|11@0- (0.04,0) [-40.9|40.9] "m" Vector__XXX
 SG_ TRACK_X : 11|12@0- (0.1,0) [-204.8|204.7] "m" Vector__XXX
 SG_ TRACK_STATUS : 15|4@0+ (1,0) [0|0] "" Vector__XXX
 SG_ TRACK_ID : 7|8@0+ (1,0) [0|255] "" Vector__XXX

BO_ 513 TRACK_1: 8 NUC
 SG_ TRACK_VY : 54|14@0- (0.01,0) [-81.92|81.91] "m/s" Vector__XXX
 SG_ TRACK_VX : 36|14@0- (0.01,0) [-81.92|81.91] "m/s" Vector__XXX
 SG_ TRACK_Y : 31|11@0- (0.04,0) [-40.9|40.9] "m" Vector__XXX
 SG_ TRACK_X : 11|12@0- (0.1,0) [-204.8|204.7] "m" Vector__XXX
 SG_ TRACK_STATUS : 15|4@0+ (1,0) [0|0] "" Vector__XXX
 SG_ TRACK_ID : 7|8@0+ (1,0) [0|255] "" Vector__XXX

BO_ 592 TRACK_ADD_0: 8 NUC
 SG_ TRACK_SIZE_Y : 49|10@0+ (0.01,0) [0|10.23] "m" Vector__XXX
 SG_ TRACK_SIZE_X : 44|11@0+ (0.01,0) [0|20.47] "m" Vector__XXX
 SG_ TRACK_ORIENTATION : 25|13@0- (0.002,0) [-8.192|8.19] "rad" Vector__XXX
 SG_ TRACK_AY : 20|11@0- (0.01,0) [-10.24|10.23] "m/s^2" Vector__XXX
 SG_ TRACK_AX : 15|11@0- (0.01,0) [-10.24|10.23] "m/s^2" Vector__XXX
 SG_ TRACK_ID : 7|8@0+ (1,0) [0|255] "" Vector__XXX

BO_ 512 TRACK_0: 8 NUC
 SG_ TRACK_VY : 54|14@0- (0.01,0) [-81.92|81.91] "m/s" Vector__XXX
 SG_ TRACK_VX : 36|14@0- (0.01,0) [-81.92|81.91] "m/s" Vector__XXX
 SG_ TRACK_Y : 31|11@0- (0.04,0) [-40.9|40.9] "m" Vector__XXX
 SG_ TRACK_X : 11|12@0- (0.1,0) [-204.8|204.7] "m" Vector__XXX
 SG_ TRACK_STATUS : 15|4@0+ (1,0) [0|0] "" Vector__XXX
 SG_ TRACK_ID : 7|8@0+ (1,0) [0|255] "" Vector__XXX

BO_ 1829 CAR_EGO_SD: 8 NUC
 SG_ EGO_D : 39|32@0- (0.01,0) [-4|4] "" Vector__XXX
 SG_ EGO_S : 7|32@0+ (0.1,0) [0|5000] "" Vector__XXX

BO_ 1828 CAR_EGO_B: 8 NUC
 SG_ WAYPOINT : 39|32@0+ (1,0) [0|4294967295] "" Vector__XXX
 SG_ YAW : 7|32@0- (0.001,0) [-3.142|3.142] "" Vector__XXX

BO_ 1827 CAR_EGO_A: 8 NUC
 SG_ Y : 39|32@0+ (0.01,0) [0|1000000] "" Vector__XXX
 SG_ X : 7|32@0+ (0.01,0) [0|1000000] "" Vector__XXX

BO_ 1825 LANE_INFO_A: 8 NUC
 SG_ TIME : 23|32@0+ (0.1,0) [0|429496729.5] "" Vector__XXX
 SG_ ALLIVE_CNT : 7|8@0+ (1,0) [0|255] "" Vector__XXX
 SG_ LANE_ID : 15|8@0- (1,0) [-4|10] "" Vector__XXX

BO_ 1826 LANE_INFO_B: 8 NUC
 SG_ M_EXIT : 39|32@0- (0.1,0) [-214748364.8|214748364.7] "" Vector__XXX
 SG_ M_ENTER : 7|32@0- (0.1,0) [-214748364.8|214748364.7] "" Vector__XXX

CM_ "CANdb__ADEV_IONIQ__KATECH__ACAN_v10__220919.dbc Generated by EROOMAT";
CM_ BO_ 777 "V2X SPaT Message 
On Intersection ID 900";
CM_ SG_ 777 movementName_9 "movementName
STRAIGHT
LEFT";
CM_ SG_ 777 signalGroup_9 "Origin value is +1, received data via CAN (ex. signalGroup 10 -> CAN data 9)";
CM_ BO_ 776 "V2X SPaT Message 
On Intersection ID 800";
CM_ SG_ 776 movementName_8 "movementName
STRAIGHT
LEFT";
CM_ SG_ 776 signalGroup_8 "Origin value is +1, received data via CAN (ex. signalGroup 10 -> CAN data 9)";
CM_ BO_ 775 "V2X SPaT Message 
On Intersection ID 700";
CM_ SG_ 775 movementName_7 "movementName
STRAIGHT
LEFT";
CM_ SG_ 775 signalGroup_7 "Origin value is +1, received data via CAN (ex. signalGroup 10 -> CAN data 9)";
CM_ BO_ 774 "V2X SPaT Message 
On Intersection ID 600";
CM_ SG_ 774 movementName_6 "movementName
STRAIGHT
LEFT";
CM_ SG_ 774 signalGroup_6 "Origin value is +1, received data via CAN (ex. signalGroup 10 -> CAN data 9)";
CM_ BO_ 773 "V2X SPaT Message 
On Intersection ID 500";
CM_ SG_ 773 movementName_5 "movementName
STRAIGHT
LEFT";
CM_ SG_ 773 signalGroup_5 "Origin value is +1, received data via CAN (ex. signalGroup 10 -> CAN data 9)";
CM_ BO_ 772 "V2X SPaT Message 
On Intersection ID 400";
CM_ SG_ 772 movementName_4 "movementName
STRAIGHT
LEFT";
CM_ SG_ 772 signalGroup_4 "Origin value is +1, received data via CAN (ex. signalGroup 10 -> CAN data 9)";
CM_ BO_ 771 "V2X SPaT Message 
On Intersection ID 300
";
CM_ SG_ 771 movementName_3 "movementName
STRAIGHT
LEFT";
CM_ SG_ 771 signalGroup_3 "Origin value is +1, received data via CAN (ex. signalGroup 10 -> CAN data 9)";
CM_ BO_ 770 "V2X SPaT Message 
On Intersection ID 200
";
CM_ SG_ 770 movementName_2 "movementName
STRAIGHT
LEFT";
CM_ SG_ 770 signalGroup_2 "Origin value is +1, received data via CAN (ex. signalGroup 10 -> CAN data 9)";
CM_ BO_ 769 "V2X SPaT Message 
On Intersection ID 100
";
CM_ SG_ 769 movementName_1 "movementName
STRAIGHT
LEFT";
CM_ SG_ 769 signalGroup_1 "Origin value is +1, received data via CAN (ex. signalGroup 10 -> CAN data 9)";
CM_ BO_ 48 "VCU1_ADCU (Vehicle Control Feedback)";
CM_ SG_ 48 vcu_EPS_En "Steering control feedback";
CM_ SG_ 48 vcu_BRK_En "Brake control feedback";
CM_ SG_ 48 vcu_ACC_En "Accel control feedback";
CM_ SG_ 48 vcu_EPS_Override "User Steering Override";
CM_ SG_ 48 vcu_BRK_Override "User Brake Override";
CM_ SG_ 48 vcu_ACC_Override "User Accel Override";
CM_ SG_ 48 vcu_EPS_Status "EPS status (0: not ready,   1: MD   2: AD,   3: override,   4: error)";
CM_ SG_ 48 vcu_ACC_Status "ACC status (0: not ready,   1: MD   2: AD,   3: override,   4: error)";
CM_ SG_ 48 vcu_BRK_Status "BRK status (0: not ready,   1: MD   2: AD,   3: override,   4: error)";
CM_ SG_ 48 vcu_TargetSteerAngle "Target Steering Angle";
CM_ SG_ 48 vcu_MaxSteeringSpeed "Max Steering Speed Limit";
CM_ SG_ 48 vcu_TargetAcceleration "Target Acceleration";
CM_ SG_ 48 VCU1_ADCU_AliveCnt "Alive Counter";
CM_ BO_ 49 "VCU2_ADCU";
CM_ SG_ 49 vcu_ADMDStatus "ADMD Switch Status (0: MD,   1: AD)";
CM_ SG_ 49 vcu_ADReady "AD Ready";
CM_ SG_ 49 vcu_Override "Override status";
CM_ SG_ 49 vcu_Estop "Emergency Stop";
CM_ SG_ 49 vcu_HazardCtl "Hazard Light On/Off";
CM_ SG_ 49 vcu_LeftTurnCtl "Left Turn Light On/Off";
CM_ SG_ 49 vcu_RightTurnCtl "Right Turn Light On/Off";
CM_ SG_ 49 vcu_LeftTurnState "Left Turn Light On/Off";
CM_ SG_ 49 vcu_RightTurnState "Right Turn Light On/Off";
CM_ SG_ 49 vcu_VB "Battery voltage";
CM_ SG_ 49 VCU2_ADCU_AliveCnt "Alive Counter";
CM_ BO_ 50 "VCU3_ADCU";
CM_ SG_ 50 vcu_APS "Accel position";
CM_ SG_ 50 vcu_BPS "Brake position";
CM_ SG_ 50 vcu_VS "Vehicle speed";
CM_ SG_ 50 vcu_SAS_Angle "Steering Angle";
CM_ SG_ 50 vcu_SAS_Speed "Steering speed";
CM_ SG_ 50 vcu_LONG_ACCEL "Lateral acceleration speed";
CM_ BO_ 51 "VCU4_ADCU";
CM_ BO_ 32 "ADCU1 (Vehicle Control)";
CM_ SG_ 32 adcu_Ready "ADCU Ready";
CM_ SG_ 32 adcu_EPS_En "Steering control On/Off";
CM_ SG_ 32 adcu_BRK_En "Brake Control On/Off";
CM_ SG_ 32 adcu_ACC_En "Accel Control On/Off";
CM_ SG_ 32 adcu_SysFault "System Fault";
CM_ SG_ 32 adcu_DriverTakeover "Driver Take Over";
CM_ SG_ 32 adcu_DriverWarning "Driver Warnig (0: no warning,   1~15: warnig message)";
CM_ SG_ 32 adcu_DesiredSteerAngle "Desired Steering Angle";
CM_ SG_ 32 adcu_MaxSteeringSpeed "Max Steering Speed";
CM_ SG_ 32 adcu_DesiredAcceleration "Desired Acceleration";
CM_ SG_ 32 ADCU1_AliveCnt "Controller alive count";
CM_ BO_ 33 "ADCU2 (AD State)";
CM_ SG_ 33 adcu_RunMode "ADCU Run Mode
   0 : Normal Driving,   1 : RunMRM,   2 : EParking_Complete,   3 : RemoteStop";
CM_ SG_ 33 adcu_DrivingMode "Driving Mode (0: None,  1: Normal,  2: Soft,  3:Hard)";
CM_ SG_ 33 adcu_WaveLevel "Wave Signal status (0: Not Detected,   1: Level1,   2: Level2,   3: Level3)";
CM_ SG_ 33 adcu_LTE5GLevel "LTE/5G Signal status (0: Not Detected,   1: Level1,   2: Level2,   3: Level3)";
CM_ SG_ 33 adcu_DesiredTimeGap "Desired Time Gap";
CM_ SG_ 33 adcu_DesiredRD "Desired RD";
CM_ SG_ 33 adcu_ActualRD "Actual RD";
CM_ SG_ 33 ADCU2_AliveCnt "Controller alive count";
CM_ BO_ 34 "ADCU2 (AD State2)";
CM_ SG_ 34 adcu_LaneDeparture "Lane Departure status (0: Off,   1: Left,   2: Right)";
CM_ SG_ 34 adcu_VehFrt "Front Vehicle status (0: Not Detected,   1: Detected,   2: Warning)";
CM_ SG_ 34 adcu_VehFL "Front Left Vehicle status (0: Not Detected,   1: Detected,   2: Warning)";
CM_ SG_ 34 adcu_VehFR "Front Right Vehicle status (0: Not Detected,   1: Detected,   2: Warning)";
CM_ SG_ 34 adcu_VehRL "Rear Left Vehicle status (0: Not Detected,   1: Detected,   2: Warning)";
CM_ SG_ 34 adcu_VehRR "Rear Right Vehicle status (0: Not Detected,   1: Detected,   2: Warning)";
CM_ SG_ 34 adcu_VehRear "Rear Vehicle status (0: Not Detected,   1: Detected,   2: Warning)";
CM_ SG_ 34 adcu_HazardLampCtl "Hazard Lamp control";
CM_ SG_ 34 adcu_LeftTurnSigCtl "Left TurnSig control";
CM_ SG_ 34 adcu_RightTurnSigCtl "Right TurnSig control";
CM_ SG_ 34 ADCU3_AliveCnt "Controller alive count";
CM_ SG_ 1265 CAN_RX_LATERAL_MOUNTING_OFFSET "(+) = to the right from driver's perspective";
CM_ SG_ 1265 CAN_RX_ANGLE_MISALIGNMENT "(+) = clockwise";
BA_DEF_  "BusType" STRING ;
BA_DEF_ BO_  "GenMsgCycleTime" INT 0 65535;
BA_DEF_ SG_  "SigType" ENUM  "Default","Range","RangeSigned","ASCII","Discrete","Control","ReferencePGN","DTC","StringDelimiter","StringLength","StringLengthControl","MessageCounter","MessageChecksum";
BA_DEF_DEF_  "BusType" "CAN";
BA_DEF_DEF_  "GenMsgCycleTime" 0;
BA_DEF_DEF_  "SigType" "Default";
BA_ "GenMsgCycleTime" BO_ 1830 1000;
BA_ "GenMsgCycleTime" BO_ 1824 100;
BA_ "GenMsgCycleTime" BO_ 64 200;
BA_ "GenMsgCycleTime" BO_ 777 100;
BA_ "GenMsgCycleTime" BO_ 776 100;
BA_ "GenMsgCycleTime" BO_ 775 100;
BA_ "GenMsgCycleTime" BO_ 774 100;
BA_ "GenMsgCycleTime" BO_ 773 100;
BA_ "GenMsgCycleTime" BO_ 772 100;
BA_ "GenMsgCycleTime" BO_ 771 100;
BA_ "GenMsgCycleTime" BO_ 770 100;
BA_ "GenMsgCycleTime" BO_ 769 100;
BA_ "GenMsgCycleTime" BO_ 276 100;
BA_ "GenMsgCycleTime" BO_ 275 100;
BA_ "GenMsgCycleTime" BO_ 274 100;
BA_ "GenMsgCycleTime" BO_ 273 100;
BA_ "GenMsgCycleTime" BO_ 272 100;
BA_ "GenMsgCycleTime" BO_ 262 100;
BA_ "GenMsgCycleTime" BO_ 261 100;
BA_ "GenMsgCycleTime" BO_ 260 100;
BA_ "GenMsgCycleTime" BO_ 259 100;
BA_ "GenMsgCycleTime" BO_ 258 100;
BA_ "GenMsgCycleTime" BO_ 257 100;
BA_ "GenMsgCycleTime" BO_ 256 100;
BA_ "GenMsgCycleTime" BO_ 103 1000;
BA_ "GenMsgCycleTime" BO_ 102 1000;
BA_ "GenMsgCycleTime" BO_ 101 1000;
BA_ "GenMsgCycleTime" BO_ 100 1000;
BA_ "GenMsgCycleTime" BO_ 99 1000;
BA_ "GenMsgCycleTime" BO_ 98 1000;
BA_ "GenMsgCycleTime" BO_ 96 1000;
BA_ "GenMsgCycleTime" BO_ 97 1000;
BA_ "GenMsgCycleTime" BO_ 48 20;
BA_ "GenMsgCycleTime" BO_ 49 100;
BA_ "GenMsgCycleTime" BO_ 50 20;
BA_ "GenMsgCycleTime" BO_ 51 100;
BA_ "GenMsgCycleTime" BO_ 32 20;
BA_ "GenMsgCycleTime" BO_ 33 100;
BA_ "GenMsgCycleTime" BO_ 34 100;
BA_ "GenMsgCycleTime" BO_ 611 10;
BA_ "GenMsgCycleTime" BO_ 610 10;
BA_ "GenMsgCycleTime" BO_ 609 10;
BA_ "GenMsgCycleTime" BO_ 608 10;
BA_ "GenMsgCycleTime" BO_ 601 10;
BA_ "GenMsgCycleTime" BO_ 600 10;
BA_ "GenMsgCycleTime" BO_ 599 10;
BA_ "GenMsgCycleTime" BO_ 598 10;
BA_ "GenMsgCycleTime" BO_ 597 10;
BA_ "GenMsgCycleTime" BO_ 596 10;
BA_ "GenMsgCycleTime" BO_ 595 10;
BA_ "GenMsgCycleTime" BO_ 594 10;
BA_ "GenMsgCycleTime" BO_ 593 10;
BA_ "GenMsgCycleTime" BO_ 531 10;
BA_ "GenMsgCycleTime" BO_ 530 10;
BA_ "GenMsgCycleTime" BO_ 529 10;
BA_ "GenMsgCycleTime" BO_ 528 10;
BA_ "GenMsgCycleTime" BO_ 521 10;
BA_ "GenMsgCycleTime" BO_ 520 10;
BA_ "GenMsgCycleTime" BO_ 519 10;
BA_ "GenMsgCycleTime" BO_ 518 10;
BA_ "GenMsgCycleTime" BO_ 517 10;
BA_ "GenMsgCycleTime" BO_ 516 10;
BA_ "GenMsgCycleTime" BO_ 515 10;
BA_ "GenMsgCycleTime" BO_ 514 10;
BA_ "GenMsgCycleTime" BO_ 513 10;
BA_ "GenMsgCycleTime" BO_ 592 10;
BA_ "GenMsgCycleTime" BO_ 512 10;
BA_ "GenMsgCycleTime" BO_ 1829 20;
BA_ "GenMsgCycleTime" BO_ 1828 20;
BA_ "GenMsgCycleTime" BO_ 1827 20;
BA_ "GenMsgCycleTime" BO_ 1825 20;
BA_ "GenMsgCycleTime" BO_ 1826 20;
VAL_ 64 Road_State 2 "out-of ODD, school-zone etc..." 1 "Forward ODD Departure Warning" 0 "can AD or doing AD" ;
VAL_ 64 On_ODD 1 "Out of ODD cannot info AD" 0 "On ODD, can into auto-drive mode" ;
VAL_ 777 eventState_9 9 "caution-Conflicting-Traffic" 8 "protected-clearance : yellow" 7 "permissive-clearance" 6 "protected-Movement-Allowed" 5 "permissive-Movement-Allowed" 4 "pre-Movement : red+yellow partly" 3 "stop-And-Remain : red right" 2 "stop-Then-Proceed : flashing red" 1 "dark" 0 "unavailable" ;
VAL_ 776 eventState_8 9 "caution-Conflicting-Traffic" 8 "protected-clearance : yellow" 7 "permissive-clearance" 6 "protected-Movement-Allowed" 5 "permissive-Movement-Allowed" 4 "pre-Movement : red+yellow partly" 3 "stop-And-Remain : red right" 2 "stop-Then-Proceed : flashing red" 1 "dark" 0 "unavailable" ;
VAL_ 775 eventState_7 9 "caution-Conflicting-Traffic" 8 "protected-clearance : yellow" 7 "permissive-clearance" 6 "protected-Movement-Allowed" 5 "permissive-Movement-Allowed" 4 "pre-Movement : red+yellow partly" 3 "stop-And-Remain : red right" 2 "stop-Then-Proceed : flashing red" 1 "dark" 0 "unavailable" ;
VAL_ 774 eventState_6 9 "caution-Conflicting-Traffic" 8 "protected-clearance : yellow" 7 "permissive-clearance" 6 "protected-Movement-Allowed" 5 "permissive-Movement-Allowed" 4 "pre-Movement : red+yellow partly" 3 "stop-And-Remain : red right" 2 "stop-Then-Proceed : flashing red" 1 "dark" 0 "unavailable" ;
VAL_ 773 eventState_5 9 "caution-Conflicting-Traffic" 8 "protected-clearance : yellow" 7 "permissive-clearance" 6 "protected-Movement-Allowed" 5 "permissive-Movement-Allowed" 4 "pre-Movement : red+yellow partly" 3 "stop-And-Remain : red right" 2 "stop-Then-Proceed : flashing red" 1 "dark" 0 "unavailable" ;
VAL_ 772 eventState_4 9 "caution-Conflicting-Traffic" 8 "protected-clearance : yellow" 7 "permissive-clearance" 6 "protected-Movement-Allowed" 5 "permissive-Movement-Allowed" 4 "pre-Movement : red+yellow partly" 3 "stop-And-Remain : red right" 2 "stop-Then-Proceed : flashing red" 1 "dark" 0 "unavailable" ;
VAL_ 771 eventState_3 9 "caution-Conflicting-Traffic" 8 "protected-clearance : yellow" 7 "permissive-clearance" 6 "protected-Movement-Allowed" 5 "permissive-Movement-Allowed" 4 "pre-Movement : red+yellow partly" 3 "stop-And-Remain : red right" 2 "stop-Then-Proceed : flashing red" 1 "dark" 0 "unavailable" ;
VAL_ 770 eventState_2 9 "caution-Conflicting-Traffic" 8 "protected-clearance : yellow" 7 "permissive-clearance" 6 "protected-Movement-Allowed" 5 "permissive-Movement-Allowed" 4 "pre-Movement : red+yellow partly" 3 "stop-And-Remain : red right" 2 "stop-Then-Proceed : flashing red" 1 "dark" 0 "unavailable" ;
VAL_ 769 eventState_1 9 "caution-Conflicting-Traffic" 8 "protected-clearance : yellow" 7 "permissive-clearance" 6 "protected-Movement-Allowed" 5 "permissive-Movement-Allowed" 4 "pre-Movement : red+yellow partly" 3 "stop-And-Remain : red right" 2 "stop-Then-Proceed : flashing red" 1 "dark" 0 "unavailable" ;
VAL_ 1897 View_Range_Availability 0 "Not Valid" 1 "Valid" ;
VAL_ 1896 Model_Degree 0 "Parabolic model" 1 "Linear model" 2 "3rd-degree model" ;
VAL_ 1896 Quality 0 "Low quality" 1 "Low quality" 2 "High quality" 3 "High quality" ;
VAL_ 1896 Lane_Type 0 "Dashed" 1 "Solid" 2 "undecided" 3 "Road Edge" 4 "Double Lane" 5 "Bott's Dots" 6 "invalid" ;
VAL_ 48 vcu_EPS_Status 0 "_0: Not Ready" 1 "_1: MD" 2 "_2: AD" 3 "_3: Override" 4 "_4: Error" ;
VAL_ 48 vcu_ACC_Status 0 "_0: Not Ready" 1 "_1: MD" 2 "_2: AD" 3 "_3: Override" 4 "_4: Error" ;
VAL_ 48 vcu_BRK_Status 0 "_0: Not Ready" 1 "_1: MD" 2 "_2: AD" 3 "_3: Override" 4 "_4: Error" ;
VAL_ 49 vcu_ADMDStatus 0 "_0: MD" 1 "_1: AD" ;
VAL_ 32 adcu_DriverWarning 0 "_0: Off" 1 "_1: GPS Data Warning" 2 "_2: MD Change Request" 3 "_3: Lane Departure" 4 "_4: AD Impossible" 5 "_5: LH Lane Change Request" 6 "_6: Course Reset Request" 7 "_7: Driving State Check" 8 "_8: RH Lane Change Request" ;
VAL_ 33 adcu_RunMode 0 "_0: Normal Driving" 1 "_1: RunMRM" 2 "_2: EParking_Complete" 3 "_3: RemoteStop" ;
VAL_ 33 adcu_DrivingMode 0 "_0: None" 1 "_1: Normal" 2 "_2: Soft" 3 "_3: Hard" ;
VAL_ 34 adcu_LaneDeparture 0 "_0: Off" 1 "_1: Left Lane" 2 "_2: Right Lane" ;
VAL_ 34 adcu_VehFrt 0 "_0: Not Detected" 1 "_1: Detected" 2 "_2: Warning" ;
VAL_ 34 adcu_VehFL 0 "_0: Not Detected" 1 "_1: Detected" 2 "_2: Warning" ;
VAL_ 34 adcu_VehFR 0 "_0: Not Detected" 1 "_1: Detected" 2 "_2: Warning" ;
VAL_ 34 adcu_VehRL 0 "_0: Not Detected" 1 "_1: Detected" 2 "_2: Warning" ;
VAL_ 34 adcu_VehRR 0 "_0: Not Detected" 1 "_1: Detected" 2 "_2: Warning" ;
VAL_ 34 adcu_VehRear 0 "_0: Not Detected" 1 "_1: Detected" 2 "_2: Warning" ;
VAL_ 1894 Lane_Type 0 "Dashed" 1 "Solid" 2 "undecided" 3 "Road Edge" 4 "Double Lane" 5 "Bott's Dots" 6 "invalid" ;
VAL_ 1894 Quality 0 "Low quality" 1 "Low quality" 2 "High quality" 3 "High quality" ;
VAL_ 1894 Model_Degree 0 "Parabolic model" 1 "Linear model" 2 "3rd-degree model" ;
VAL_ 1895 View_Range_Availability 0 "Not Valid" 1 "Valid" ;
VAL_ 1285 CAN_TX_TRACK_GROUPING_CHANGED 1 "GroupingChanged" 0 "GroupingUnchanged" ;
VAL_ 1285 CAN_TX_TRACK_ONCOMING 1 "Oncoming" 0 "NotOncoming" ;
VAL_ 1285 CAN_TX_TRACK_BRIDGE_OBJECT 1 "Bridge" 0 "Not_Bridge" ;
VAL_ 1285 CAN_TX_TRACK_STATUS 7 "New_Coasted_Target" 6 "Invalid_Coasted_Target" 5 "Merged_Target" 4 "Coasted_Target" 3 "Updated_Target" 2 "New_Updated_Target" 1 "New_Target" 0 "No_Target" ;
VAL_ 1285 CAN_TX_TRACK_MED_RANGE_MODE 3 "Both_MR_LR_Update" 2 "LR_Update_Only" 1 "MR_Update_Only" 0 "No_MR_LR_Update" ;
VAL_ 1286 CAN_TX_TRACK_GROUPING_CHANGED 1 "GroupingChanged" 0 "GroupingUnchanged" ;
VAL_ 1286 CAN_TX_TRACK_ONCOMING 1 "Oncoming" 0 "NotOncoming" ;
VAL_ 1286 CAN_TX_TRACK_BRIDGE_OBJECT 1 "Bridge" 0 "Not_Bridge" ;
VAL_ 1286 CAN_TX_TRACK_STATUS 7 "New_Coasted_Target" 6 "Invalid_Coasted_Target" 5 "Merged_Target" 4 "Coasted_Target" 3 "Updated_Target" 2 "New_Updated_Target" 1 "New_Target" 0 "No_Target" ;
VAL_ 1286 CAN_TX_TRACK_MED_RANGE_MODE 3 "Both_MR_LR_Update" 2 "LR_Update_Only" 1 "MR_Update_Only" 0 "No_MR_LR_Update" ;
VAL_ 1312 CAN_TX_TRACK_GROUPING_CHANGED 1 "GroupingChanged" 0 "GroupingUnchanged" ;
VAL_ 1312 CAN_TX_TRACK_ONCOMING 1 "Oncoming" 0 "NotOncoming" ;
VAL_ 1312 CAN_TX_TRACK_BRIDGE_OBJECT 1 "Bridge" 0 "Not_Bridge" ;
VAL_ 1312 CAN_TX_TRACK_STATUS 7 "New_Coasted_Target" 6 "Invalid_Coasted_Target" 5 "Merged_Target" 4 "Coasted_Target" 3 "Updated_Target" 2 "New_Updated_Target" 1 "New_Target" 0 "No_Target" ;
VAL_ 1312 CAN_TX_TRACK_MED_RANGE_MODE 3 "Both_MR_LR_Update" 2 "LR_Update_Only" 1 "MR_Update_Only" 0 "No_MR_LR_Update" ;
VAL_ 1307 CAN_TX_TRACK_GROUPING_CHANGED 1 "GroupingChanged" 0 "GroupingUnchanged" ;
VAL_ 1307 CAN_TX_TRACK_ONCOMING 1 "Oncoming" 0 "NotOncoming" ;
VAL_ 1307 CAN_TX_TRACK_BRIDGE_OBJECT 1 "Bridge" 0 "Not_Bridge" ;
VAL_ 1307 CAN_TX_TRACK_STATUS 7 "New_Coasted_Target" 6 "Invalid_Coasted_Target" 5 "Merged_Target" 4 "Coasted_Target" 3 "Updated_Target" 2 "New_Updated_Target" 1 "New_Target" 0 "No_Target" ;
VAL_ 1307 CAN_TX_TRACK_MED_RANGE_MODE 3 "Both_MR_LR_Update" 2 "LR_Update_Only" 1 "MR_Update_Only" 0 "No_MR_LR_Update" ;
VAL_ 1308 CAN_TX_TRACK_GROUPING_CHANGED 1 "GroupingChanged" 0 "GroupingUnchanged" ;
VAL_ 1308 CAN_TX_TRACK_ONCOMING 1 "Oncoming" 0 "NotOncoming" ;
VAL_ 1308 CAN_TX_TRACK_BRIDGE_OBJECT 1 "Bridge" 0 "Not_Bridge" ;
VAL_ 1308 CAN_TX_TRACK_STATUS 7 "New_Coasted_Target" 6 "Invalid_Coasted_Target" 5 "Merged_Target" 4 "Coasted_Target" 3 "Updated_Target" 2 "New_Updated_Target" 1 "New_Target" 0 "No_Target" ;
VAL_ 1308 CAN_TX_TRACK_MED_RANGE_MODE 3 "Both_MR_LR_Update" 2 "LR_Update_Only" 1 "MR_Update_Only" 0 "No_MR_LR_Update" ;
VAL_ 1303 CAN_TX_TRACK_GROUPING_CHANGED 1 "GroupingChanged" 0 "GroupingUnchanged" ;
VAL_ 1303 CAN_TX_TRACK_ONCOMING 1 "Oncoming" 0 "NotOncoming" ;
VAL_ 1303 CAN_TX_TRACK_BRIDGE_OBJECT 1 "Bridge" 0 "Not_Bridge" ;
VAL_ 1303 CAN_TX_TRACK_STATUS 7 "New_Coasted_Target" 6 "Invalid_Coasted_Target" 5 "Merged_Target" 4 "Coasted_Target" 3 "Updated_Target" 2 "New_Updated_Target" 1 "New_Target" 0 "No_Target" ;
VAL_ 1303 CAN_TX_TRACK_MED_RANGE_MODE 3 "Both_MR_LR_Update" 2 "LR_Update_Only" 1 "MR_Update_Only" 0 "No_MR_LR_Update" ;
VAL_ 1298 CAN_TX_TRACK_GROUPING_CHANGED 1 "GroupingChanged" 0 "GroupingUnchanged" ;
VAL_ 1298 CAN_TX_TRACK_ONCOMING 1 "Oncoming" 0 "NotOncoming" ;
VAL_ 1298 CAN_TX_TRACK_BRIDGE_OBJECT 1 "Bridge" 0 "Not_Bridge" ;
VAL_ 1298 CAN_TX_TRACK_STATUS 7 "New_Coasted_Target" 6 "Invalid_Coasted_Target" 5 "Merged_Target" 4 "Coasted_Target" 3 "Updated_Target" 2 "New_Updated_Target" 1 "New_Target" 0 "No_Target" ;
VAL_ 1298 CAN_TX_TRACK_MED_RANGE_MODE 3 "Both_MR_LR_Update" 2 "LR_Update_Only" 1 "MR_Update_Only" 0 "No_MR_LR_Update" ;
VAL_ 1306 CAN_TX_TRACK_GROUPING_CHANGED 1 "GroupingChanged" 0 "GroupingUnchanged" ;
VAL_ 1306 CAN_TX_TRACK_ONCOMING 1 "Oncoming" 0 "NotOncoming" ;
VAL_ 1306 CAN_TX_TRACK_BRIDGE_OBJECT 1 "Bridge" 0 "Not_Bridge" ;
VAL_ 1306 CAN_TX_TRACK_STATUS 7 "New_Coasted_Target" 6 "Invalid_Coasted_Target" 5 "Merged_Target" 4 "Coasted_Target" 3 "Updated_Target" 2 "New_Updated_Target" 1 "New_Target" 0 "No_Target" ;
VAL_ 1306 CAN_TX_TRACK_MED_RANGE_MODE 3 "Both_MR_LR_Update" 2 "LR_Update_Only" 1 "MR_Update_Only" 0 "No_MR_LR_Update" ;
VAL_ 1309 CAN_TX_TRACK_GROUPING_CHANGED 1 "GroupingChanged" 0 "GroupingUnchanged" ;
VAL_ 1309 CAN_TX_TRACK_ONCOMING 1 "Oncoming" 0 "NotOncoming" ;
VAL_ 1309 CAN_TX_TRACK_BRIDGE_OBJECT 1 "Bridge" 0 "Not_Bridge" ;
VAL_ 1309 CAN_TX_TRACK_STATUS 7 "New_Coasted_Target" 6 "Invalid_Coasted_Target" 5 "Merged_Target" 4 "Coasted_Target" 3 "Updated_Target" 2 "New_Updated_Target" 1 "New_Target" 0 "No_Target" ;
VAL_ 1309 CAN_TX_TRACK_MED_RANGE_MODE 3 "Both_MR_LR_Update" 2 "LR_Update_Only" 1 "MR_Update_Only" 0 "No_MR_LR_Update" ;
VAL_ 1292 CAN_TX_TRACK_GROUPING_CHANGED 1 "GroupingChanged" 0 "GroupingUnchanged" ;
VAL_ 1292 CAN_TX_TRACK_ONCOMING 1 "Oncoming" 0 "NotOncoming" ;
VAL_ 1292 CAN_TX_TRACK_BRIDGE_OBJECT 1 "Bridge" 0 "Not_Bridge" ;
VAL_ 1292 CAN_TX_TRACK_STATUS 7 "New_Coasted_Target" 6 "Invalid_Coasted_Target" 5 "Merged_Target" 4 "Coasted_Target" 3 "Updated_Target" 2 "New_Updated_Target" 1 "New_Target" 0 "No_Target" ;
VAL_ 1292 CAN_TX_TRACK_MED_RANGE_MODE 3 "Both_MR_LR_Update" 2 "LR_Update_Only" 1 "MR_Update_Only" 0 "No_MR_LR_Update" ;
VAL_ 1297 CAN_TX_TRACK_GROUPING_CHANGED 1 "GroupingChanged" 0 "GroupingUnchanged" ;
VAL_ 1297 CAN_TX_TRACK_ONCOMING 1 "Oncoming" 0 "NotOncoming" ;
VAL_ 1297 CAN_TX_TRACK_BRIDGE_OBJECT 1 "Bridge" 0 "Not_Bridge" ;
VAL_ 1297 CAN_TX_TRACK_STATUS 7 "New_Coasted_Target" 6 "Invalid_Coasted_Target" 5 "Merged_Target" 4 "Coasted_Target" 3 "Updated_Target" 2 "New_Updated_Target" 1 "New_Target" 0 "No_Target" ;
VAL_ 1297 CAN_TX_TRACK_MED_RANGE_MODE 3 "Both_MR_LR_Update" 2 "LR_Update_Only" 1 "MR_Update_Only" 0 "No_MR_LR_Update" ;
VAL_ 1305 CAN_TX_TRACK_GROUPING_CHANGED 1 "GroupingChanged" 0 "GroupingUnchanged" ;
VAL_ 1305 CAN_TX_TRACK_ONCOMING 1 "Oncoming" 0 "NotOncoming" ;
VAL_ 1305 CAN_TX_TRACK_BRIDGE_OBJECT 1 "Bridge" 0 "Not_Bridge" ;
VAL_ 1305 CAN_TX_TRACK_STATUS 7 "New_Coasted_Target" 6 "Invalid_Coasted_Target" 5 "Merged_Target" 4 "Coasted_Target" 3 "Updated_Target" 2 "New_Updated_Target" 1 "New_Target" 0 "No_Target" ;
VAL_ 1305 CAN_TX_TRACK_MED_RANGE_MODE 3 "Both_MR_LR_Update" 2 "LR_Update_Only" 1 "MR_Update_Only" 0 "No_MR_LR_Update" ;
VAL_ 1310 CAN_TX_TRACK_GROUPING_CHANGED 1 "GroupingChanged" 0 "GroupingUnchanged" ;
VAL_ 1310 CAN_TX_TRACK_ONCOMING 1 "Oncoming" 0 "NotOncoming" ;
VAL_ 1310 CAN_TX_TRACK_BRIDGE_OBJECT 1 "Bridge" 0 "Not_Bridge" ;
VAL_ 1310 CAN_TX_TRACK_STATUS 7 "New_Coasted_Target" 6 "Invalid_Coasted_Target" 5 "Merged_Target" 4 "Coasted_Target" 3 "Updated_Target" 2 "New_Updated_Target" 1 "New_Target" 0 "No_Target" ;
VAL_ 1310 CAN_TX_TRACK_MED_RANGE_MODE 3 "Both_MR_LR_Update" 2 "LR_Update_Only" 1 "MR_Update_Only" 0 "No_MR_LR_Update" ;
VAL_ 1296 CAN_TX_TRACK_GROUPING_CHANGED 1 "GroupingChanged" 0 "GroupingUnchanged" ;
VAL_ 1296 CAN_TX_TRACK_ONCOMING 1 "Oncoming" 0 "NotOncoming" ;
VAL_ 1296 CAN_TX_TRACK_BRIDGE_OBJECT 1 "Bridge" 0 "Not_Bridge" ;
VAL_ 1296 CAN_TX_TRACK_STATUS 7 "New_Coasted_Target" 6 "Invalid_Coasted_Target" 5 "Merged_Target" 4 "Coasted_Target" 3 "Updated_Target" 2 "New_Updated_Target" 1 "New_Target" 0 "No_Target" ;
VAL_ 1296 CAN_TX_TRACK_MED_RANGE_MODE 3 "Both_MR_LR_Update" 2 "LR_Update_Only" 1 "MR_Update_Only" 0 "No_MR_LR_Update" ;
VAL_ 1299 CAN_TX_TRACK_GROUPING_CHANGED 1 "GroupingChanged" 0 "GroupingUnchanged" ;
VAL_ 1299 CAN_TX_TRACK_ONCOMING 1 "Oncoming" 0 "NotOncoming" ;
VAL_ 1299 CAN_TX_TRACK_BRIDGE_OBJECT 1 "Bridge" 0 "Not_Bridge" ;
VAL_ 1299 CAN_TX_TRACK_STATUS 7 "New_Coasted_Target" 6 "Invalid_Coasted_Target" 5 "Merged_Target" 4 "Coasted_Target" 3 "Updated_Target" 2 "New_Updated_Target" 1 "New_Target" 0 "No_Target" ;
VAL_ 1299 CAN_TX_TRACK_MED_RANGE_MODE 3 "Both_MR_LR_Update" 2 "LR_Update_Only" 1 "MR_Update_Only" 0 "No_MR_LR_Update" ;
VAL_ 1291 CAN_TX_TRACK_GROUPING_CHANGED 1 "GroupingChanged" 0 "GroupingUnchanged" ;
VAL_ 1291 CAN_TX_TRACK_ONCOMING 1 "Oncoming" 0 "NotOncoming" ;
VAL_ 1291 CAN_TX_TRACK_BRIDGE_OBJECT 1 "Bridge" 0 "Not_Bridge" ;
VAL_ 1291 CAN_TX_TRACK_STATUS 7 "New_Coasted_Target" 6 "Invalid_Coasted_Target" 5 "Merged_Target" 4 "Coasted_Target" 3 "Updated_Target" 2 "New_Updated_Target" 1 "New_Target" 0 "No_Target" ;
VAL_ 1291 CAN_TX_TRACK_MED_RANGE_MODE 3 "Both_MR_LR_Update" 2 "LR_Update_Only" 1 "MR_Update_Only" 0 "No_MR_LR_Update" ;
VAL_ 1288 CAN_TX_TRACK_GROUPING_CHANGED 1 "GroupingChanged" 0 "GroupingUnchanged" ;
VAL_ 1288 CAN_TX_TRACK_ONCOMING 1 "Oncoming" 0 "NotOncoming" ;
VAL_ 1288 CAN_TX_TRACK_BRIDGE_OBJECT 1 "Bridge" 0 "Not_Bridge" ;
VAL_ 1288 CAN_TX_TRACK_STATUS 7 "New_Coasted_Target" 6 "Invalid_Coasted_Target" 5 "Merged_Target" 4 "Coasted_Target" 3 "Updated_Target" 2 "New_Updated_Target" 1 "New_Target" 0 "No_Target" ;
VAL_ 1288 CAN_TX_TRACK_MED_RANGE_MODE 3 "Both_MR_LR_Update" 2 "LR_Update_Only" 1 "MR_Update_Only" 0 "No_MR_LR_Update" ;
VAL_ 1289 CAN_TX_TRACK_GROUPING_CHANGED 1 "GroupingChanged" 0 "GroupingUnchanged" ;
VAL_ 1289 CAN_TX_TRACK_ONCOMING 1 "Oncoming" 0 "NotOncoming" ;
VAL_ 1289 CAN_TX_TRACK_BRIDGE_OBJECT 1 "Bridge" 0 "Not_Bridge" ;
VAL_ 1289 CAN_TX_TRACK_STATUS 7 "New_Coasted_Target" 6 "Invalid_Coasted_Target" 5 "Merged_Target" 4 "Coasted_Target" 3 "Updated_Target" 2 "New_Updated_Target" 1 "New_Target" 0 "No_Target" ;
VAL_ 1289 CAN_TX_TRACK_MED_RANGE_MODE 3 "Both_MR_LR_Update" 2 "LR_Update_Only" 1 "MR_Update_Only" 0 "No_MR_LR_Update" ;
VAL_ 1301 CAN_TX_TRACK_GROUPING_CHANGED 1 "GroupingChanged" 0 "GroupingUnchanged" ;
VAL_ 1301 CAN_TX_TRACK_ONCOMING 1 "Oncoming" 0 "NotOncoming" ;
VAL_ 1301 CAN_TX_TRACK_BRIDGE_OBJECT 1 "Bridge" 0 "Not_Bridge" ;
VAL_ 1301 CAN_TX_TRACK_STATUS 7 "New_Coasted_Target" 6 "Invalid_Coasted_Target" 5 "Merged_Target" 4 "Coasted_Target" 3 "Updated_Target" 2 "New_Updated_Target" 1 "New_Target" 0 "No_Target" ;
VAL_ 1301 CAN_TX_TRACK_MED_RANGE_MODE 3 "Both_MR_LR_Update" 2 "LR_Update_Only" 1 "MR_Update_Only" 0 "No_MR_LR_Update" ;
VAL_ 1295 CAN_TX_TRACK_GROUPING_CHANGED 1 "GroupingChanged" 0 "GroupingUnchanged" ;
VAL_ 1295 CAN_TX_TRACK_ONCOMING 1 "Oncoming" 0 "NotOncoming" ;
VAL_ 1295 CAN_TX_TRACK_BRIDGE_OBJECT 1 "Bridge" 0 "Not_Bridge" ;
VAL_ 1295 CAN_TX_TRACK_STATUS 7 "New_Coasted_Target" 6 "Invalid_Coasted_Target" 5 "Merged_Target" 4 "Coasted_Target" 3 "Updated_Target" 2 "New_Updated_Target" 1 "New_Target" 0 "No_Target" ;
VAL_ 1295 CAN_TX_TRACK_MED_RANGE_MODE 3 "Both_MR_LR_Update" 2 "LR_Update_Only" 1 "MR_Update_Only" 0 "No_MR_LR_Update" ;
VAL_ 1300 CAN_TX_TRACK_GROUPING_CHANGED 1 "GroupingChanged" 0 "GroupingUnchanged" ;
VAL_ 1300 CAN_TX_TRACK_ONCOMING 1 "Oncoming" 0 "NotOncoming" ;
VAL_ 1300 CAN_TX_TRACK_BRIDGE_OBJECT 1 "Bridge" 0 "Not_Bridge" ;
VAL_ 1300 CAN_TX_TRACK_STATUS 7 "New_Coasted_Target" 6 "Invalid_Coasted_Target" 5 "Merged_Target" 4 "Coasted_Target" 3 "Updated_Target" 2 "New_Updated_Target" 1 "New_Target" 0 "No_Target" ;
VAL_ 1300 CAN_TX_TRACK_MED_RANGE_MODE 3 "Both_MR_LR_Update" 2 "LR_Update_Only" 1 "MR_Update_Only" 0 "No_MR_LR_Update" ;
VAL_ 1294 CAN_TX_TRACK_GROUPING_CHANGED 1 "GroupingChanged" 0 "GroupingUnchanged" ;
VAL_ 1294 CAN_TX_TRACK_ONCOMING 1 "Oncoming" 0 "NotOncoming" ;
VAL_ 1294 CAN_TX_TRACK_BRIDGE_OBJECT 1 "Bridge" 0 "Not_Bridge" ;
VAL_ 1294 CAN_TX_TRACK_STATUS 7 "New_Coasted_Target" 6 "Invalid_Coasted_Target" 5 "Merged_Target" 4 "Coasted_Target" 3 "Updated_Target" 2 "New_Updated_Target" 1 "New_Target" 0 "No_Target" ;
VAL_ 1294 CAN_TX_TRACK_MED_RANGE_MODE 3 "Both_MR_LR_Update" 2 "LR_Update_Only" 1 "MR_Update_Only" 0 "No_MR_LR_Update" ;
VAL_ 1302 CAN_TX_TRACK_GROUPING_CHANGED 1 "GroupingChanged" 0 "GroupingUnchanged" ;
VAL_ 1302 CAN_TX_TRACK_ONCOMING 1 "Oncoming" 0 "NotOncoming" ;
VAL_ 1302 CAN_TX_TRACK_BRIDGE_OBJECT 1 "Bridge" 0 "Not_Bridge" ;
VAL_ 1302 CAN_TX_TRACK_STATUS 7 "New_Coasted_Target" 6 "Invalid_Coasted_Target" 5 "Merged_Target" 4 "Coasted_Target" 3 "Updated_Target" 2 "New_Updated_Target" 1 "New_Target" 0 "No_Target" ;
VAL_ 1302 CAN_TX_TRACK_MED_RANGE_MODE 3 "Both_MR_LR_Update" 2 "LR_Update_Only" 1 "MR_Update_Only" 0 "No_MR_LR_Update" ;
VAL_ 1287 CAN_TX_TRACK_GROUPING_CHANGED 1 "GroupingChanged" 0 "GroupingUnchanged" ;
VAL_ 1287 CAN_TX_TRACK_ONCOMING 1 "Oncoming" 0 "NotOncoming" ;
VAL_ 1287 CAN_TX_TRACK_BRIDGE_OBJECT 1 "Bridge" 0 "Not_Bridge" ;
VAL_ 1287 CAN_TX_TRACK_STATUS 7 "New_Coasted_Target" 6 "Invalid_Coasted_Target" 5 "Merged_Target" 4 "Coasted_Target" 3 "Updated_Target" 2 "New_Updated_Target" 1 "New_Target" 0 "No_Target" ;
VAL_ 1287 CAN_TX_TRACK_MED_RANGE_MODE 3 "Both_MR_LR_Update" 2 "LR_Update_Only" 1 "MR_Update_Only" 0 "No_MR_LR_Update" ;
VAL_ 1304 CAN_TX_TRACK_GROUPING_CHANGED 1 "GroupingChanged" 0 "GroupingUnchanged" ;
VAL_ 1304 CAN_TX_TRACK_ONCOMING 1 "Oncoming" 0 "NotOncoming" ;
VAL_ 1304 CAN_TX_TRACK_BRIDGE_OBJECT 1 "Bridge" 0 "Not_Bridge" ;
VAL_ 1304 CAN_TX_TRACK_STATUS 7 "New_Coasted_Target" 6 "Invalid_Coasted_Target" 5 "Merged_Target" 4 "Coasted_Target" 3 "Updated_Target" 2 "New_Updated_Target" 1 "New_Target" 0 "No_Target" ;
VAL_ 1304 CAN_TX_TRACK_MED_RANGE_MODE 3 "Both_MR_LR_Update" 2 "LR_Update_Only" 1 "MR_Update_Only" 0 "No_MR_LR_Update" ;
VAL_ 1313 CAN_TX_TRACK_GROUPING_CHANGED 1 "GroupingChanged" 0 "GroupingUnchanged" ;
VAL_ 1313 CAN_TX_TRACK_ONCOMING 1 "Oncoming" 0 "NotOncoming" ;
VAL_ 1313 CAN_TX_TRACK_BRIDGE_OBJECT 1 "Bridge" 0 "Not_Bridge" ;
VAL_ 1313 CAN_TX_TRACK_STATUS 7 "New_Coasted_Target" 6 "Invalid_Coasted_Target" 5 "Merged_Target" 4 "Coasted_Target" 3 "Updated_Target" 2 "New_Updated_Target" 1 "New_Target" 0 "No_Target" ;
VAL_ 1313 CAN_TX_TRACK_MED_RANGE_MODE 3 "Both_MR_LR_Update" 2 "LR_Update_Only" 1 "MR_Update_Only" 0 "No_MR_LR_Update" ;
VAL_ 1315 CAN_TX_TRACK_GROUPING_CHANGED 1 "GroupingChanged" 0 "GroupingUnchanged" ;
VAL_ 1315 CAN_TX_TRACK_ONCOMING 1 "Oncoming" 0 "NotOncoming" ;
VAL_ 1315 CAN_TX_TRACK_BRIDGE_OBJECT 1 "Bridge" 0 "Not_Bridge" ;
VAL_ 1315 CAN_TX_TRACK_STATUS 7 "New_Coasted_Target" 6 "Invalid_Coasted_Target" 5 "Merged_Target" 4 "Coasted_Target" 3 "Updated_Target" 2 "New_Updated_Target" 1 "New_Target" 0 "No_Target" ;
VAL_ 1315 CAN_TX_TRACK_MED_RANGE_MODE 3 "Both_MR_LR_Update" 2 "LR_Update_Only" 1 "MR_Update_Only" 0 "No_MR_LR_Update" ;
VAL_ 1343 CAN_TX_TRACK_GROUPING_CHANGED 1 "GroupingChanged" 0 "GroupingUnchanged" ;
VAL_ 1343 CAN_TX_TRACK_ONCOMING 1 "Oncoming" 0 "NotOncoming" ;
VAL_ 1343 CAN_TX_TRACK_BRIDGE_OBJECT 1 "Bridge" 0 "Not_Bridge" ;
VAL_ 1343 CAN_TX_TRACK_STATUS 7 "New_Coasted_Target" 6 "Invalid_Coasted_Target" 5 "Merged_Target" 4 "Coasted_Target" 3 "Updated_Target" 2 "New_Updated_Target" 1 "New_Target" 0 "No_Target" ;
VAL_ 1343 CAN_TX_TRACK_MED_RANGE_MODE 3 "Both_MR_LR_Update" 2 "LR_Update_Only" 1 "MR_Update_Only" 0 "No_MR_LR_Update" ;
VAL_ 1314 CAN_TX_TRACK_GROUPING_CHANGED 1 "GroupingChanged" 0 "GroupingUnchanged" ;
VAL_ 1314 CAN_TX_TRACK_ONCOMING 1 "Oncoming" 0 "NotOncoming" ;
VAL_ 1314 CAN_TX_TRACK_BRIDGE_OBJECT 1 "Bridge" 0 "Not_Bridge" ;
VAL_ 1314 CAN_TX_TRACK_STATUS 7 "New_Coasted_Target" 6 "Invalid_Coasted_Target" 5 "Merged_Target" 4 "Coasted_Target" 3 "Updated_Target" 2 "New_Updated_Target" 1 "New_Target" 0 "No_Target" ;
VAL_ 1314 CAN_TX_TRACK_MED_RANGE_MODE 3 "Both_MR_LR_Update" 2 "LR_Update_Only" 1 "MR_Update_Only" 0 "No_MR_LR_Update" ;
VAL_ 1332 CAN_TX_TRACK_GROUPING_CHANGED 1 "GroupingChanged" 0 "GroupingUnchanged" ;
VAL_ 1332 CAN_TX_TRACK_ONCOMING 1 "Oncoming" 0 "NotOncoming" ;
VAL_ 1332 CAN_TX_TRACK_BRIDGE_OBJECT 1 "Bridge" 0 "Not_Bridge" ;
VAL_ 1332 CAN_TX_TRACK_STATUS 7 "New_Coasted_Target" 6 "Invalid_Coasted_Target" 5 "Merged_Target" 4 "Coasted_Target" 3 "Updated_Target" 2 "New_Updated_Target" 1 "New_Target" 0 "No_Target" ;
VAL_ 1332 CAN_TX_TRACK_MED_RANGE_MODE 3 "Both_MR_LR_Update" 2 "LR_Update_Only" 1 "MR_Update_Only" 0 "No_MR_LR_Update" ;
VAL_ 1316 CAN_TX_TRACK_GROUPING_CHANGED 1 "GroupingChanged" 0 "GroupingUnchanged" ;
VAL_ 1316 CAN_TX_TRACK_ONCOMING 1 "Oncoming" 0 "NotOncoming" ;
VAL_ 1316 CAN_TX_TRACK_BRIDGE_OBJECT 1 "Bridge" 0 "Not_Bridge" ;
VAL_ 1316 CAN_TX_TRACK_STATUS 7 "New_Coasted_Target" 6 "Invalid_Coasted_Target" 5 "Merged_Target" 4 "Coasted_Target" 3 "Updated_Target" 2 "New_Updated_Target" 1 "New_Target" 0 "No_Target" ;
VAL_ 1316 CAN_TX_TRACK_MED_RANGE_MODE 3 "Both_MR_LR_Update" 2 "LR_Update_Only" 1 "MR_Update_Only" 0 "No_MR_LR_Update" ;
VAL_ 1317 CAN_TX_TRACK_GROUPING_CHANGED 1 "GroupingChanged" 0 "GroupingUnchanged" ;
VAL_ 1317 CAN_TX_TRACK_ONCOMING 1 "Oncoming" 0 "NotOncoming" ;
VAL_ 1317 CAN_TX_TRACK_BRIDGE_OBJECT 1 "Bridge" 0 "Not_Bridge" ;
VAL_ 1317 CAN_TX_TRACK_STATUS 7 "New_Coasted_Target" 6 "Invalid_Coasted_Target" 5 "Merged_Target" 4 "Coasted_Target" 3 "Updated_Target" 2 "New_Updated_Target" 1 "New_Target" 0 "No_Target" ;
VAL_ 1317 CAN_TX_TRACK_MED_RANGE_MODE 3 "Both_MR_LR_Update" 2 "LR_Update_Only" 1 "MR_Update_Only" 0 "No_MR_LR_Update" ;
VAL_ 1327 CAN_TX_TRACK_GROUPING_CHANGED 1 "GroupingChanged" 0 "GroupingUnchanged" ;
VAL_ 1327 CAN_TX_TRACK_ONCOMING 1 "Oncoming" 0 "NotOncoming" ;
VAL_ 1327 CAN_TX_TRACK_BRIDGE_OBJECT 1 "Bridge" 0 "Not_Bridge" ;
VAL_ 1327 CAN_TX_TRACK_STATUS 7 "New_Coasted_Target" 6 "Invalid_Coasted_Target" 5 "Merged_Target" 4 "Coasted_Target" 3 "Updated_Target" 2 "New_Updated_Target" 1 "New_Target" 0 "No_Target" ;
VAL_ 1327 CAN_TX_TRACK_MED_RANGE_MODE 3 "Both_MR_LR_Update" 2 "LR_Update_Only" 1 "MR_Update_Only" 0 "No_MR_LR_Update" ;
VAL_ 1324 CAN_TX_TRACK_GROUPING_CHANGED 1 "GroupingChanged" 0 "GroupingUnchanged" ;
VAL_ 1324 CAN_TX_TRACK_ONCOMING 1 "Oncoming" 0 "NotOncoming" ;
VAL_ 1324 CAN_TX_TRACK_BRIDGE_OBJECT 1 "Bridge" 0 "Not_Bridge" ;
VAL_ 1324 CAN_TX_TRACK_STATUS 7 "New_Coasted_Target" 6 "Invalid_Coasted_Target" 5 "Merged_Target" 4 "Coasted_Target" 3 "Updated_Target" 2 "New_Updated_Target" 1 "New_Target" 0 "No_Target" ;
VAL_ 1324 CAN_TX_TRACK_MED_RANGE_MODE 3 "Both_MR_LR_Update" 2 "LR_Update_Only" 1 "MR_Update_Only" 0 "No_MR_LR_Update" ;
VAL_ 1339 CAN_TX_TRACK_GROUPING_CHANGED 1 "GroupingChanged" 0 "GroupingUnchanged" ;
VAL_ 1339 CAN_TX_TRACK_ONCOMING 1 "Oncoming" 0 "NotOncoming" ;
VAL_ 1339 CAN_TX_TRACK_BRIDGE_OBJECT 1 "Bridge" 0 "Not_Bridge" ;
VAL_ 1339 CAN_TX_TRACK_STATUS 7 "New_Coasted_Target" 6 "Invalid_Coasted_Target" 5 "Merged_Target" 4 "Coasted_Target" 3 "Updated_Target" 2 "New_Updated_Target" 1 "New_Target" 0 "No_Target" ;
VAL_ 1339 CAN_TX_TRACK_MED_RANGE_MODE 3 "Both_MR_LR_Update" 2 "LR_Update_Only" 1 "MR_Update_Only" 0 "No_MR_LR_Update" ;
VAL_ 1322 CAN_TX_TRACK_GROUPING_CHANGED 1 "GroupingChanged" 0 "GroupingUnchanged" ;
VAL_ 1322 CAN_TX_TRACK_ONCOMING 1 "Oncoming" 0 "NotOncoming" ;
VAL_ 1322 CAN_TX_TRACK_BRIDGE_OBJECT 1 "Bridge" 0 "Not_Bridge" ;
VAL_ 1322 CAN_TX_TRACK_STATUS 7 "New_Coasted_Target" 6 "Invalid_Coasted_Target" 5 "Merged_Target" 4 "Coasted_Target" 3 "Updated_Target" 2 "New_Updated_Target" 1 "New_Target" 0 "No_Target" ;
VAL_ 1322 CAN_TX_TRACK_MED_RANGE_MODE 3 "Both_MR_LR_Update" 2 "LR_Update_Only" 1 "MR_Update_Only" 0 "No_MR_LR_Update" ;
VAL_ 1318 CAN_TX_TRACK_GROUPING_CHANGED 1 "GroupingChanged" 0 "GroupingUnchanged" ;
VAL_ 1318 CAN_TX_TRACK_ONCOMING 1 "Oncoming" 0 "NotOncoming" ;
VAL_ 1318 CAN_TX_TRACK_BRIDGE_OBJECT 1 "Bridge" 0 "Not_Bridge" ;
VAL_ 1318 CAN_TX_TRACK_STATUS 7 "New_Coasted_Target" 6 "Invalid_Coasted_Target" 5 "Merged_Target" 4 "Coasted_Target" 3 "Updated_Target" 2 "New_Updated_Target" 1 "New_Target" 0 "No_Target" ;
VAL_ 1318 CAN_TX_TRACK_MED_RANGE_MODE 3 "Both_MR_LR_Update" 2 "LR_Update_Only" 1 "MR_Update_Only" 0 "No_MR_LR_Update" ;
VAL_ 1321 CAN_TX_TRACK_GROUPING_CHANGED 1 "GroupingChanged" 0 "GroupingUnchanged" ;
VAL_ 1321 CAN_TX_TRACK_ONCOMING 1 "Oncoming" 0 "NotOncoming" ;
VAL_ 1321 CAN_TX_TRACK_BRIDGE_OBJECT 1 "Bridge" 0 "Not_Bridge" ;
VAL_ 1321 CAN_TX_TRACK_STATUS 7 "New_Coasted_Target" 6 "Invalid_Coasted_Target" 5 "Merged_Target" 4 "Coasted_Target" 3 "Updated_Target" 2 "New_Updated_Target" 1 "New_Target" 0 "No_Target" ;
VAL_ 1321 CAN_TX_TRACK_MED_RANGE_MODE 3 "Both_MR_LR_Update" 2 "LR_Update_Only" 1 "MR_Update_Only" 0 "No_MR_LR_Update" ;
VAL_ 1320 CAN_TX_TRACK_GROUPING_CHANGED 1 "GroupingChanged" 0 "GroupingUnchanged" ;
VAL_ 1320 CAN_TX_TRACK_ONCOMING 1 "Oncoming" 0 "NotOncoming" ;
VAL_ 1320 CAN_TX_TRACK_BRIDGE_OBJECT 1 "Bridge" 0 "Not_Bridge" ;
VAL_ 1320 CAN_TX_TRACK_STATUS 7 "New_Coasted_Target" 6 "Invalid_Coasted_Target" 5 "Merged_Target" 4 "Coasted_Target" 3 "Updated_Target" 2 "New_Updated_Target" 1 "New_Target" 0 "No_Target" ;
VAL_ 1320 CAN_TX_TRACK_MED_RANGE_MODE 3 "Both_MR_LR_Update" 2 "LR_Update_Only" 1 "MR_Update_Only" 0 "No_MR_LR_Update" ;
VAL_ 1319 CAN_TX_TRACK_GROUPING_CHANGED 1 "GroupingChanged" 0 "GroupingUnchanged" ;
VAL_ 1319 CAN_TX_TRACK_ONCOMING 1 "Oncoming" 0 "NotOncoming" ;
VAL_ 1319 CAN_TX_TRACK_BRIDGE_OBJECT 1 "Bridge" 0 "Not_Bridge" ;
VAL_ 1319 CAN_TX_TRACK_STATUS 7 "New_Coasted_Target" 6 "Invalid_Coasted_Target" 5 "Merged_Target" 4 "Coasted_Target" 3 "Updated_Target" 2 "New_Updated_Target" 1 "New_Target" 0 "No_Target" ;
VAL_ 1319 CAN_TX_TRACK_MED_RANGE_MODE 3 "Both_MR_LR_Update" 2 "LR_Update_Only" 1 "MR_Update_Only" 0 "No_MR_LR_Update" ;
VAL_ 1323 CAN_TX_TRACK_GROUPING_CHANGED 1 "GroupingChanged" 0 "GroupingUnchanged" ;
VAL_ 1323 CAN_TX_TRACK_ONCOMING 1 "Oncoming" 0 "NotOncoming" ;
VAL_ 1323 CAN_TX_TRACK_BRIDGE_OBJECT 1 "Bridge" 0 "Not_Bridge" ;
VAL_ 1323 CAN_TX_TRACK_STATUS 7 "New_Coasted_Target" 6 "Invalid_Coasted_Target" 5 "Merged_Target" 4 "Coasted_Target" 3 "Updated_Target" 2 "New_Updated_Target" 1 "New_Target" 0 "No_Target" ;
VAL_ 1323 CAN_TX_TRACK_MED_RANGE_MODE 3 "Both_MR_LR_Update" 2 "LR_Update_Only" 1 "MR_Update_Only" 0 "No_MR_LR_Update" ;
VAL_ 1329 CAN_TX_TRACK_GROUPING_CHANGED 1 "GroupingChanged" 0 "GroupingUnchanged" ;
VAL_ 1329 CAN_TX_TRACK_ONCOMING 1 "Oncoming" 0 "NotOncoming" ;
VAL_ 1329 CAN_TX_TRACK_BRIDGE_OBJECT 1 "Bridge" 0 "Not_Bridge" ;
VAL_ 1329 CAN_TX_TRACK_STATUS 7 "New_Coasted_Target" 6 "Invalid_Coasted_Target" 5 "Merged_Target" 4 "Coasted_Target" 3 "Updated_Target" 2 "New_Updated_Target" 1 "New_Target" 0 "No_Target" ;
VAL_ 1329 CAN_TX_TRACK_MED_RANGE_MODE 3 "Both_MR_LR_Update" 2 "LR_Update_Only" 1 "MR_Update_Only" 0 "No_MR_LR_Update" ;
VAL_ 1326 CAN_TX_TRACK_GROUPING_CHANGED 1 "GroupingChanged" 0 "GroupingUnchanged" ;
VAL_ 1326 CAN_TX_TRACK_ONCOMING 1 "Oncoming" 0 "NotOncoming" ;
VAL_ 1326 CAN_TX_TRACK_BRIDGE_OBJECT 1 "Bridge" 0 "Not_Bridge" ;
VAL_ 1326 CAN_TX_TRACK_STATUS 7 "New_Coasted_Target" 6 "Invalid_Coasted_Target" 5 "Merged_Target" 4 "Coasted_Target" 3 "Updated_Target" 2 "New_Updated_Target" 1 "New_Target" 0 "No_Target" ;
VAL_ 1326 CAN_TX_TRACK_MED_RANGE_MODE 3 "Both_MR_LR_Update" 2 "LR_Update_Only" 1 "MR_Update_Only" 0 "No_MR_LR_Update" ;
VAL_ 1342 CAN_TX_TRACK_GROUPING_CHANGED 1 "GroupingChanged" 0 "GroupingUnchanged" ;
VAL_ 1342 CAN_TX_TRACK_ONCOMING 1 "Oncoming" 0 "NotOncoming" ;
VAL_ 1342 CAN_TX_TRACK_BRIDGE_OBJECT 1 "Bridge" 0 "Not_Bridge" ;
VAL_ 1342 CAN_TX_TRACK_STATUS 7 "New_Coasted_Target" 6 "Invalid_Coasted_Target" 5 "Merged_Target" 4 "Coasted_Target" 3 "Updated_Target" 2 "New_Updated_Target" 1 "New_Target" 0 "No_Target" ;
VAL_ 1342 CAN_TX_TRACK_MED_RANGE_MODE 3 "Both_MR_LR_Update" 2 "LR_Update_Only" 1 "MR_Update_Only" 0 "No_MR_LR_Update" ;
VAL_ 1340 CAN_TX_TRACK_GROUPING_CHANGED 1 "GroupingChanged" 0 "GroupingUnchanged" ;
VAL_ 1340 CAN_TX_TRACK_ONCOMING 1 "Oncoming" 0 "NotOncoming" ;
VAL_ 1340 CAN_TX_TRACK_BRIDGE_OBJECT 1 "Bridge" 0 "Not_Bridge" ;
VAL_ 1340 CAN_TX_TRACK_STATUS 7 "New_Coasted_Target" 6 "Invalid_Coasted_Target" 5 "Merged_Target" 4 "Coasted_Target" 3 "Updated_Target" 2 "New_Updated_Target" 1 "New_Target" 0 "No_Target" ;
VAL_ 1340 CAN_TX_TRACK_MED_RANGE_MODE 3 "Both_MR_LR_Update" 2 "LR_Update_Only" 1 "MR_Update_Only" 0 "No_MR_LR_Update" ;
VAL_ 1333 CAN_TX_TRACK_GROUPING_CHANGED 1 "GroupingChanged" 0 "GroupingUnchanged" ;
VAL_ 1333 CAN_TX_TRACK_ONCOMING 1 "Oncoming" 0 "NotOncoming" ;
VAL_ 1333 CAN_TX_TRACK_BRIDGE_OBJECT 1 "Bridge" 0 "Not_Bridge" ;
VAL_ 1333 CAN_TX_TRACK_STATUS 7 "New_Coasted_Target" 6 "Invalid_Coasted_Target" 5 "Merged_Target" 4 "Coasted_Target" 3 "Updated_Target" 2 "New_Updated_Target" 1 "New_Target" 0 "No_Target" ;
VAL_ 1333 CAN_TX_TRACK_MED_RANGE_MODE 3 "Both_MR_LR_Update" 2 "LR_Update_Only" 1 "MR_Update_Only" 0 "No_MR_LR_Update" ;
VAL_ 1335 CAN_TX_TRACK_GROUPING_CHANGED 1 "GroupingChanged" 0 "GroupingUnchanged" ;
VAL_ 1335 CAN_TX_TRACK_ONCOMING 1 "Oncoming" 0 "NotOncoming" ;
VAL_ 1335 CAN_TX_TRACK_BRIDGE_OBJECT 1 "Bridge" 0 "Not_Bridge" ;
VAL_ 1335 CAN_TX_TRACK_STATUS 7 "New_Coasted_Target" 6 "Invalid_Coasted_Target" 5 "Merged_Target" 4 "Coasted_Target" 3 "Updated_Target" 2 "New_Updated_Target" 1 "New_Target" 0 "No_Target" ;
VAL_ 1335 CAN_TX_TRACK_MED_RANGE_MODE 3 "Both_MR_LR_Update" 2 "LR_Update_Only" 1 "MR_Update_Only" 0 "No_MR_LR_Update" ;
VAL_ 1337 CAN_TX_TRACK_GROUPING_CHANGED 1 "GroupingChanged" 0 "GroupingUnchanged" ;
VAL_ 1337 CAN_TX_TRACK_ONCOMING 1 "Oncoming" 0 "NotOncoming" ;
VAL_ 1337 CAN_TX_TRACK_BRIDGE_OBJECT 1 "Bridge" 0 "Not_Bridge" ;
VAL_ 1337 CAN_TX_TRACK_STATUS 7 "New_Coasted_Target" 6 "Invalid_Coasted_Target" 5 "Merged_Target" 4 "Coasted_Target" 3 "Updated_Target" 2 "New_Updated_Target" 1 "New_Target" 0 "No_Target" ;
VAL_ 1337 CAN_TX_TRACK_MED_RANGE_MODE 3 "Both_MR_LR_Update" 2 "LR_Update_Only" 1 "MR_Update_Only" 0 "No_MR_LR_Update" ;
VAL_ 1331 CAN_TX_TRACK_GROUPING_CHANGED 1 "GroupingChanged" 0 "GroupingUnchanged" ;
VAL_ 1331 CAN_TX_TRACK_ONCOMING 1 "Oncoming" 0 "NotOncoming" ;
VAL_ 1331 CAN_TX_TRACK_BRIDGE_OBJECT 1 "Bridge" 0 "Not_Bridge" ;
VAL_ 1331 CAN_TX_TRACK_STATUS 7 "New_Coasted_Target" 6 "Invalid_Coasted_Target" 5 "Merged_Target" 4 "Coasted_Target" 3 "Updated_Target" 2 "New_Updated_Target" 1 "New_Target" 0 "No_Target" ;
VAL_ 1331 CAN_TX_TRACK_MED_RANGE_MODE 3 "Both_MR_LR_Update" 2 "LR_Update_Only" 1 "MR_Update_Only" 0 "No_MR_LR_Update" ;
VAL_ 1338 CAN_TX_TRACK_GROUPING_CHANGED 1 "GroupingChanged" 0 "GroupingUnchanged" ;
VAL_ 1338 CAN_TX_TRACK_ONCOMING 1 "Oncoming" 0 "NotOncoming" ;
VAL_ 1338 CAN_TX_TRACK_BRIDGE_OBJECT 1 "Bridge" 0 "Not_Bridge" ;
VAL_ 1338 CAN_TX_TRACK_STATUS 7 "New_Coasted_Target" 6 "Invalid_Coasted_Target" 5 "Merged_Target" 4 "Coasted_Target" 3 "Updated_Target" 2 "New_Updated_Target" 1 "New_Target" 0 "No_Target" ;
VAL_ 1338 CAN_TX_TRACK_MED_RANGE_MODE 3 "Both_MR_LR_Update" 2 "LR_Update_Only" 1 "MR_Update_Only" 0 "No_MR_LR_Update" ;
VAL_ 1336 CAN_TX_TRACK_GROUPING_CHANGED 1 "GroupingChanged" 0 "GroupingUnchanged" ;
VAL_ 1336 CAN_TX_TRACK_ONCOMING 1 "Oncoming" 0 "NotOncoming" ;
VAL_ 1336 CAN_TX_TRACK_BRIDGE_OBJECT 1 "Bridge" 0 "Not_Bridge" ;
VAL_ 1336 CAN_TX_TRACK_STATUS 7 "New_Coasted_Target" 6 "Invalid_Coasted_Target" 5 "Merged_Target" 4 "Coasted_Target" 3 "Updated_Target" 2 "New_Updated_Target" 1 "New_Target" 0 "No_Target" ;
VAL_ 1336 CAN_TX_TRACK_MED_RANGE_MODE 3 "Both_MR_LR_Update" 2 "LR_Update_Only" 1 "MR_Update_Only" 0 "No_MR_LR_Update" ;
VAL_ 1334 CAN_TX_TRACK_GROUPING_CHANGED 1 "GroupingChanged" 0 "GroupingUnchanged" ;
VAL_ 1334 CAN_TX_TRACK_ONCOMING 1 "Oncoming" 0 "NotOncoming" ;
VAL_ 1334 CAN_TX_TRACK_BRIDGE_OBJECT 1 "Bridge" 0 "Not_Bridge" ;
VAL_ 1334 CAN_TX_TRACK_STATUS 7 "New_Coasted_Target" 6 "Invalid_Coasted_Target" 5 "Merged_Target" 4 "Coasted_Target" 3 "Updated_Target" 2 "New_Updated_Target" 1 "New_Target" 0 "No_Target" ;
VAL_ 1334 CAN_TX_TRACK_MED_RANGE_MODE 3 "Both_MR_LR_Update" 2 "LR_Update_Only" 1 "MR_Update_Only" 0 "No_MR_LR_Update" ;
VAL_ 1330 CAN_TX_TRACK_GROUPING_CHANGED 1 "GroupingChanged" 0 "GroupingUnchanged" ;
VAL_ 1330 CAN_TX_TRACK_ONCOMING 1 "Oncoming" 0 "NotOncoming" ;
VAL_ 1330 CAN_TX_TRACK_BRIDGE_OBJECT 1 "Bridge" 0 "Not_Bridge" ;
VAL_ 1330 CAN_TX_TRACK_STATUS 7 "New_Coasted_Target" 6 "Invalid_Coasted_Target" 5 "Merged_Target" 4 "Coasted_Target" 3 "Updated_Target" 2 "New_Updated_Target" 1 "New_Target" 0 "No_Target" ;
VAL_ 1330 CAN_TX_TRACK_MED_RANGE_MODE 3 "Both_MR_LR_Update" 2 "LR_Update_Only" 1 "MR_Update_Only" 0 "No_MR_LR_Update" ;
VAL_ 1328 CAN_TX_TRACK_GROUPING_CHANGED 1 "GroupingChanged" 0 "GroupingUnchanged" ;
VAL_ 1328 CAN_TX_TRACK_ONCOMING 1 "Oncoming" 0 "NotOncoming" ;
VAL_ 1328 CAN_TX_TRACK_BRIDGE_OBJECT 1 "Bridge" 0 "Not_Bridge" ;
VAL_ 1328 CAN_TX_TRACK_STATUS 7 "New_Coasted_Target" 6 "Invalid_Coasted_Target" 5 "Merged_Target" 4 "Coasted_Target" 3 "Updated_Target" 2 "New_Updated_Target" 1 "New_Target" 0 "No_Target" ;
VAL_ 1328 CAN_TX_TRACK_MED_RANGE_MODE 3 "Both_MR_LR_Update" 2 "LR_Update_Only" 1 "MR_Update_Only" 0 "No_MR_LR_Update" ;
VAL_ 1282 CAN_TX_TRACK_GROUPING_CHANGED 1 "GroupingChanged" 0 "GroupingUnchanged" ;
VAL_ 1282 CAN_TX_TRACK_ONCOMING 1 "Oncoming" 0 "NotOncoming" ;
VAL_ 1282 CAN_TX_TRACK_BRIDGE_OBJECT 1 "Bridge" 0 "Not_Bridge" ;
VAL_ 1282 CAN_TX_TRACK_STATUS 7 "New_Coasted_Target" 6 "Invalid_Coasted_Target" 5 "Merged_Target" 4 "Coasted_Target" 3 "Updated_Target" 2 "New_Updated_Target" 1 "New_Target" 0 "No_Target" ;
VAL_ 1282 CAN_TX_TRACK_MED_RANGE_MODE 3 "Both_MR_LR_Update" 2 "LR_Update_Only" 1 "MR_Update_Only" 0 "No_MR_LR_Update" ;
VAL_ 1283 CAN_TX_TRACK_GROUPING_CHANGED 1 "GroupingChanged" 0 "GroupingUnchanged" ;
VAL_ 1283 CAN_TX_TRACK_ONCOMING 1 "Oncoming" 0 "NotOncoming" ;
VAL_ 1283 CAN_TX_TRACK_BRIDGE_OBJECT 1 "Bridge" 0 "Not_Bridge" ;
VAL_ 1283 CAN_TX_TRACK_STATUS 7 "New_Coasted_Target" 6 "Invalid_Coasted_Target" 5 "Merged_Target" 4 "Coasted_Target" 3 "Updated_Target" 2 "New_Updated_Target" 1 "New_Target" 0 "No_Target" ;
VAL_ 1283 CAN_TX_TRACK_MED_RANGE_MODE 3 "Both_MR_LR_Update" 2 "LR_Update_Only" 1 "MR_Update_Only" 0 "No_MR_LR_Update" ;
VAL_ 1284 CAN_TX_TRACK_GROUPING_CHANGED 1 "GroupingChanged" 0 "GroupingUnchanged" ;
VAL_ 1284 CAN_TX_TRACK_ONCOMING 1 "Oncoming" 0 "NotOncoming" ;
VAL_ 1284 CAN_TX_TRACK_BRIDGE_OBJECT 1 "Bridge" 0 "Not_Bridge" ;
VAL_ 1284 CAN_TX_TRACK_STATUS 7 "New_Coasted_Target" 6 "Invalid_Coasted_Target" 5 "Merged_Target" 4 "Coasted_Target" 3 "Updated_Target" 2 "New_Updated_Target" 1 "New_Target" 0 "No_Target" ;
VAL_ 1284 CAN_TX_TRACK_MED_RANGE_MODE 3 "Both_MR_LR_Update" 2 "LR_Update_Only" 1 "MR_Update_Only" 0 "No_MR_LR_Update" ;
VAL_ 1311 CAN_TX_TRACK_GROUPING_CHANGED 1 "GroupingChanged" 0 "GroupingUnchanged" ;
VAL_ 1311 CAN_TX_TRACK_ONCOMING 1 "Oncoming" 0 "NotOncoming" ;
VAL_ 1311 CAN_TX_TRACK_BRIDGE_OBJECT 1 "Bridge" 0 "Not_Bridge" ;
VAL_ 1311 CAN_TX_TRACK_STATUS 7 "New_Coasted_Target" 6 "Invalid_Coasted_Target" 5 "Merged_Target" 4 "Coasted_Target" 3 "Updated_Target" 2 "New_Updated_Target" 1 "New_Target" 0 "No_Target" ;
VAL_ 1311 CAN_TX_TRACK_MED_RANGE_MODE 3 "Both_MR_LR_Update" 2 "LR_Update_Only" 1 "MR_Update_Only" 0 "No_MR_LR_Update" ;
VAL_ 1290 CAN_TX_TRACK_GROUPING_CHANGED 1 "GroupingChanged" 0 "GroupingUnchanged" ;
VAL_ 1290 CAN_TX_TRACK_ONCOMING 1 "Oncoming" 0 "NotOncoming" ;
VAL_ 1290 CAN_TX_TRACK_BRIDGE_OBJECT 1 "Bridge" 0 "Not_Bridge" ;
VAL_ 1290 CAN_TX_TRACK_STATUS 7 "New_Coasted_Target" 6 "Invalid_Coasted_Target" 5 "Merged_Target" 4 "Coasted_Target" 3 "Updated_Target" 2 "New_Updated_Target" 1 "New_Target" 0 "No_Target" ;
VAL_ 1290 CAN_TX_TRACK_MED_RANGE_MODE 3 "Both_MR_LR_Update" 2 "LR_Update_Only" 1 "MR_Update_Only" 0 "No_MR_LR_Update" ;
VAL_ 1293 CAN_TX_TRACK_GROUPING_CHANGED 1 "GroupingChanged" 0 "GroupingUnchanged" ;
VAL_ 1293 CAN_TX_TRACK_ONCOMING 1 "Oncoming" 0 "NotOncoming" ;
VAL_ 1293 CAN_TX_TRACK_BRIDGE_OBJECT 1 "Bridge" 0 "Not_Bridge" ;
VAL_ 1293 CAN_TX_TRACK_STATUS 7 "New_Coasted_Target" 6 "Invalid_Coasted_Target" 5 "Merged_Target" 4 "Coasted_Target" 3 "Updated_Target" 2 "New_Updated_Target" 1 "New_Target" 0 "No_Target" ;
VAL_ 1293 CAN_TX_TRACK_MED_RANGE_MODE 3 "Both_MR_LR_Update" 2 "LR_Update_Only" 1 "MR_Update_Only" 0 "No_MR_LR_Update" ;
VAL_ 1325 CAN_TX_TRACK_GROUPING_CHANGED 1 "GroupingChanged" 0 "GroupingUnchanged" ;
VAL_ 1325 CAN_TX_TRACK_ONCOMING 1 "Oncoming" 0 "NotOncoming" ;
VAL_ 1325 CAN_TX_TRACK_BRIDGE_OBJECT 1 "Bridge" 0 "Not_Bridge" ;
VAL_ 1325 CAN_TX_TRACK_STATUS 7 "New_Coasted_Target" 6 "Invalid_Coasted_Target" 5 "Merged_Target" 4 "Coasted_Target" 3 "Updated_Target" 2 "New_Updated_Target" 1 "New_Target" 0 "No_Target" ;
VAL_ 1325 CAN_TX_TRACK_MED_RANGE_MODE 3 "Both_MR_LR_Update" 2 "LR_Update_Only" 1 "MR_Update_Only" 0 "No_MR_LR_Update" ;
VAL_ 1341 CAN_TX_TRACK_GROUPING_CHANGED 1 "GroupingChanged" 0 "GroupingUnchanged" ;
VAL_ 1341 CAN_TX_TRACK_ONCOMING 1 "Oncoming" 0 "NotOncoming" ;
VAL_ 1341 CAN_TX_TRACK_BRIDGE_OBJECT 1 "Bridge" 0 "Not_Bridge" ;
VAL_ 1341 CAN_TX_TRACK_STATUS 7 "New_Coasted_Target" 6 "Invalid_Coasted_Target" 5 "Merged_Target" 4 "Coasted_Target" 3 "Updated_Target" 2 "New_Updated_Target" 1 "New_Target" 0 "No_Target" ;
VAL_ 1341 CAN_TX_TRACK_MED_RANGE_MODE 3 "Both_MR_LR_Update" 2 "LR_Update_Only" 1 "MR_Update_Only" 0 "No_MR_LR_Update" ;
VAL_ 1281 CAN_TX_TRACK_GROUPING_CHANGED 1 "GroupingChanged" 0 "GroupingUnchanged" ;
VAL_ 1281 CAN_TX_TRACK_ONCOMING 1 "Oncoming" 0 "NotOncoming" ;
VAL_ 1281 CAN_TX_TRACK_BRIDGE_OBJECT 1 "Bridge" 0 "Not_Bridge" ;
VAL_ 1281 CAN_TX_TRACK_STATUS 7 "New_Coasted_Target" 6 "Invalid_Coasted_Target" 5 "Merged_Target" 4 "Coasted_Target" 3 "Updated_Target" 2 "New_Updated_Target" 1 "New_Target" 0 "No_Target" ;
VAL_ 1281 CAN_TX_TRACK_MED_RANGE_MODE 3 "Both_MR_LR_Update" 2 "LR_Update_Only" 1 "MR_Update_Only" 0 "No_MR_LR_Update" ;
VAL_ 1509 CAN_TX_VERTICAL_ALIGN_UPDATED 1 "Updated" 0 "Not_Updated" ;
VAL_ 1509 CAN_TX_FOUND_TARGET 1 "Found" 0 "Not_Found" ;
VAL_ 1509 CAN_TX_FACTORY_ALIGN_STATUS_2 5 "FAIL_VAR_TOO_LARGE" 4 "FAIL_DEV_TOO_LARGE" 3 "FAIL_NO_TARGET" 2 "SUCCESS" 1 "BUSY" 0 "OFF" ;
VAL_ 1509 CAN_TX_FACTORY_ALIGN_STATUS_1 5 "FAIL_VAR_TOO_LARGE" 4 "FAIL_DEV_TOO_LARGE" 3 "FAIL_NO_TARGET" 2 "SUCCESS" 1 "BUSY" 0 "OFF" ;
VAL_ 1509 CAN_TX_RECOMMEND_UNCONVERGE 1 "Recommend" 0 "Not_Recommend" ;
VAL_ 1509 CAN_TX_SYSTEM_POWER_MODE 7 "7invalid" 6 "TEST" 5 "HOST_SHUTDOWN" 4 "DSP_OFF" 3 "DSP_SHUTDOWN" 2 "RADIATE_ON" 1 "RADIATE_OFF" 0 "DSP_INIT" ;
VAL_ 1344 CAN_TX_TRACK_MOVABLE_SLOW64 1 "Movable" 0 "Not_Movable" ;
VAL_ 1344 CAN_TX_TRACK_MOVING64 1 "Moving" 0 "Stationary" ;
VAL_ 1344 CAN_TX_TRACK_MOVABLE_FAST64 1 "Movable" 0 "Not_Movable" ;
VAL_ 1344 CAN_TX_TRACK_MOVABLE_SLOW63 1 "Movable" 0 "Not_Movable" ;
VAL_ 1344 CAN_TX_TRACK_MOVABLE_SLOW62 1 "Movable" 0 "Not_Movable" ;
VAL_ 1344 CAN_TX_TRACK_MOVABLE_SLOW61 1 "Movable" 0 "Not_Movable" ;
VAL_ 1344 CAN_TX_TRACK_MOVABLE_SLOW60 1 "Movable" 0 "Not_Movable" ;
VAL_ 1344 CAN_TX_TRACK_MOVING63 1 "Moving" 0 "Stationary" ;
VAL_ 1344 CAN_TX_TRACK_MOVING62 1 "Moving" 0 "Stationary" ;
VAL_ 1344 CAN_TX_TRACK_MOVING61 1 "Moving" 0 "Stationary" ;
VAL_ 1344 CAN_TX_TRACK_MOVING60 1 "Moving" 0 "Stationary" ;
VAL_ 1344 CAN_TX_TRACK_MOVABLE_FAST63 1 "Movable" 0 "Not_Movable" ;
VAL_ 1344 CAN_TX_TRACK_MOVABLE_FAST62 1 "Movable" 0 "Not_Movable" ;
VAL_ 1344 CAN_TX_TRACK_MOVABLE_FAST61 1 "Movable" 0 "Not_Movable" ;
VAL_ 1344 CAN_TX_TRACK_MOVABLE_FAST60 1 "Movable" 0 "Not_Movable" ;
VAL_ 1344 CAN_TX_TRACK_MOVABLE_SLOW49 1 "Movable" 0 "Not_Movable" ;
VAL_ 1344 CAN_TX_TRACK_MOVABLE_SLOW48 1 "Movable" 0 "Not_Movable" ;
VAL_ 1344 CAN_TX_TRACK_MOVABLE_SLOW47 1 "Movable" 0 "Not_Movable" ;
VAL_ 1344 CAN_TX_TRACK_MOVABLE_SLOW46 1 "Movable" 0 "Not_Movable" ;
VAL_ 1344 CAN_TX_TRACK_MOVABLE_SLOW45 1 "Movable" 0 "Not_Movable" ;
VAL_ 1344 CAN_TX_TRACK_MOVABLE_SLOW44 1 "Movable" 0 "Not_Movable" ;
VAL_ 1344 CAN_TX_TRACK_MOVABLE_SLOW43 1 "Movable" 0 "Not_Movable" ;
VAL_ 1344 CAN_TX_TRACK_MOVING49 1 "Moving" 0 "Stationary" ;
VAL_ 1344 CAN_TX_TRACK_MOVING48 1 "Moving" 0 "Stationary" ;
VAL_ 1344 CAN_TX_TRACK_MOVING47 1 "Moving" 0 "Stationary" ;
VAL_ 1344 CAN_TX_TRACK_MOVING46 1 "Moving" 0 "Stationary" ;
VAL_ 1344 CAN_TX_TRACK_MOVING45 1 "Moving" 0 "Stationary" ;
VAL_ 1344 CAN_TX_TRACK_MOVING44 1 "Moving" 0 "Stationary" ;
VAL_ 1344 CAN_TX_TRACK_MOVING43 1 "Moving" 0 "Stationary" ;
VAL_ 1344 CAN_TX_TRACK_MOVABLE_FAST49 1 "Movable" 0 "Not_Movable" ;
VAL_ 1344 CAN_TX_TRACK_MOVABLE_FAST48 1 "Movable" 0 "Not_Movable" ;
VAL_ 1344 CAN_TX_TRACK_MOVABLE_FAST47 1 "Movable" 0 "Not_Movable" ;
VAL_ 1344 CAN_TX_TRACK_MOVABLE_FAST46 1 "Movable" 0 "Not_Movable" ;
VAL_ 1344 CAN_TX_TRACK_MOVABLE_FAST45 1 "Movable" 0 "Not_Movable" ;
VAL_ 1344 CAN_TX_TRACK_MOVABLE_FAST44 1 "Movable" 0 "Not_Movable" ;
VAL_ 1344 CAN_TX_TRACK_MOVABLE_FAST43 1 "Movable" 0 "Not_Movable" ;
VAL_ 1344 CAN_TX_TRACK_MOVABLE_SLOW42 1 "Movable" 0 "Not_Movable" ;
VAL_ 1344 CAN_TX_TRACK_MOVABLE_SLOW41 1 "Movable" 0 "Not_Movable" ;
VAL_ 1344 CAN_TX_TRACK_MOVABLE_SLOW40 1 "Movable" 0 "Not_Movable" ;
VAL_ 1344 CAN_TX_TRACK_MOVABLE_SLOW39 1 "Movable" 0 "Not_Movable" ;
VAL_ 1344 CAN_TX_TRACK_MOVABLE_SLOW38 1 "Movable" 0 "Not_Movable" ;
VAL_ 1344 CAN_TX_TRACK_MOVABLE_SLOW37 1 "Movable" 0 "Not_Movable" ;
VAL_ 1344 CAN_TX_TRACK_MOVABLE_SLOW36 1 "Movable" 0 "Not_Movable" ;
VAL_ 1344 CAN_TX_TRACK_MOVING42 1 "Moving" 0 "Stationary" ;
VAL_ 1344 CAN_TX_TRACK_MOVING41 1 "Moving" 0 "Stationary" ;
VAL_ 1344 CAN_TX_TRACK_MOVING40 1 "Moving" 0 "Stationary" ;
VAL_ 1344 CAN_TX_TRACK_MOVING39 1 "Moving" 0 "Stationary" ;
VAL_ 1344 CAN_TX_TRACK_MOVING38 1 "Moving" 0 "Stationary" ;
VAL_ 1344 CAN_TX_TRACK_MOVING37 1 "Moving" 0 "Stationary" ;
VAL_ 1344 CAN_TX_TRACK_MOVING36 1 "Moving" 0 "Stationary" ;
VAL_ 1344 CAN_TX_TRACK_MOVABLE_FAST42 1 "Movable" 0 "Not_Movable" ;
VAL_ 1344 CAN_TX_TRACK_MOVABLE_FAST41 1 "Movable" 0 "Not_Movable" ;
VAL_ 1344 CAN_TX_TRACK_MOVABLE_FAST40 1 "Movable" 0 "Not_Movable" ;
VAL_ 1344 CAN_TX_TRACK_MOVABLE_FAST39 1 "Movable" 0 "Not_Movable" ;
VAL_ 1344 CAN_TX_TRACK_MOVABLE_FAST38 1 "Movable" 0 "Not_Movable" ;
VAL_ 1344 CAN_TX_TRACK_MOVABLE_FAST37 1 "Movable" 0 "Not_Movable" ;
VAL_ 1344 CAN_TX_TRACK_MOVABLE_FAST36 1 "Movable" 0 "Not_Movable" ;
VAL_ 1344 CAN_TX_TRACK_MOVABLE_SLOW35 1 "Movable" 0 "Not_Movable" ;
VAL_ 1344 CAN_TX_TRACK_MOVABLE_SLOW34 1 "Movable" 0 "Not_Movable" ;
VAL_ 1344 CAN_TX_TRACK_MOVABLE_SLOW33 1 "Movable" 0 "Not_Movable" ;
VAL_ 1344 CAN_TX_TRACK_MOVABLE_SLOW32 1 "Movable" 0 "Not_Movable" ;
VAL_ 1344 CAN_TX_TRACK_MOVABLE_SLOW31 1 "Movable" 0 "Not_Movable" ;
VAL_ 1344 CAN_TX_TRACK_MOVABLE_SLOW30 1 "Movable" 0 "Not_Movable" ;
VAL_ 1344 CAN_TX_TRACK_MOVABLE_SLOW29 1 "Movable" 0 "Not_Movable" ;
VAL_ 1344 CAN_TX_TRACK_MOVING35 1 "Moving" 0 "Stationary" ;
VAL_ 1344 CAN_TX_TRACK_MOVING34 1 "Moving" 0 "Stationary" ;
VAL_ 1344 CAN_TX_TRACK_MOVING33 1 "Moving" 0 "Stationary" ;
VAL_ 1344 CAN_TX_TRACK_MOVING32 1 "Moving" 0 "Stationary" ;
VAL_ 1344 CAN_TX_TRACK_MOVING31 1 "Moving" 0 "Stationary" ;
VAL_ 1344 CAN_TX_TRACK_MOVING30 1 "Moving" 0 "Stationary" ;
VAL_ 1344 CAN_TX_TRACK_MOVING29 1 "Moving" 0 "Stationary" ;
VAL_ 1344 CAN_TX_TRACK_MOVABLE_FAST35 1 "Movable" 0 "Not_Movable" ;
VAL_ 1344 CAN_TX_TRACK_MOVABLE_FAST34 1 "Movable" 0 "Not_Movable" ;
VAL_ 1344 CAN_TX_TRACK_MOVABLE_FAST33 1 "Movable" 0 "Not_Movable" ;
VAL_ 1344 CAN_TX_TRACK_MOVABLE_FAST32 1 "Movable" 0 "Not_Movable" ;
VAL_ 1344 CAN_TX_TRACK_MOVABLE_FAST31 1 "Movable" 0 "Not_Movable" ;
VAL_ 1344 CAN_TX_TRACK_MOVABLE_FAST30 1 "Movable" 0 "Not_Movable" ;
VAL_ 1344 CAN_TX_TRACK_MOVABLE_FAST29 1 "Movable" 0 "Not_Movable" ;
VAL_ 1344 CAN_TX_TRACK_MOVABLE_SLOW28 1 "Movable" 0 "Not_Movable" ;
VAL_ 1344 CAN_TX_TRACK_MOVABLE_SLOW27 1 "Movable" 0 "Not_Movable" ;
VAL_ 1344 CAN_TX_TRACK_MOVABLE_SLOW26 1 "Movable" 0 "Not_Movable" ;
VAL_ 1344 CAN_TX_TRACK_MOVABLE_SLOW25 1 "Movable" 0 "Not_Movable" ;
VAL_ 1344 CAN_TX_TRACK_MOVABLE_SLOW24 1 "Movable" 0 "Not_Movable" ;
VAL_ 1344 CAN_TX_TRACK_MOVABLE_SLOW23 1 "Movable" 0 "Not_Movable" ;
VAL_ 1344 CAN_TX_TRACK_MOVABLE_SLOW22 1 "Movable" 0 "Not_Movable" ;
VAL_ 1344 CAN_TX_TRACK_MOVING28 1 "Moving" 0 "Stationary" ;
VAL_ 1344 CAN_TX_TRACK_MOVING27 1 "Moving" 0 "Stationary" ;
VAL_ 1344 CAN_TX_TRACK_MOVING26 1 "Moving" 0 "Stationary" ;
VAL_ 1344 CAN_TX_TRACK_MOVING25 1 "Moving" 0 "Stationary" ;
VAL_ 1344 CAN_TX_TRACK_MOVING24 1 "Moving" 0 "Stationary" ;
VAL_ 1344 CAN_TX_TRACK_MOVING23 1 "Moving" 0 "Stationary" ;
VAL_ 1344 CAN_TX_TRACK_MOVING22 1 "Moving" 0 "Stationary" ;
VAL_ 1344 CAN_TX_TRACK_MOVABLE_FAST28 1 "Movable" 0 "Not_Movable" ;
VAL_ 1344 CAN_TX_TRACK_MOVABLE_FAST27 1 "Movable" 0 "Not_Movable" ;
VAL_ 1344 CAN_TX_TRACK_MOVABLE_FAST26 1 "Movable" 0 "Not_Movable" ;
VAL_ 1344 CAN_TX_TRACK_MOVABLE_FAST25 1 "Movable" 0 "Not_Movable" ;
VAL_ 1344 CAN_TX_TRACK_MOVABLE_FAST24 1 "Movable" 0 "Not_Movable" ;
VAL_ 1344 CAN_TX_TRACK_MOVABLE_FAST23 1 "Movable" 0 "Not_Movable" ;
VAL_ 1344 CAN_TX_TRACK_MOVABLE_FAST22 1 "Movable" 0 "Not_Movable" ;
VAL_ 1344 CAN_TX_TRACK_MOVABLE_SLOW21 1 "Movable" 0 "Not_Movable" ;
VAL_ 1344 CAN_TX_TRACK_MOVABLE_SLOW20 1 "Movable" 0 "Not_Movable" ;
VAL_ 1344 CAN_TX_TRACK_MOVABLE_SLOW19 1 "Movable" 0 "Not_Movable" ;
VAL_ 1344 CAN_TX_TRACK_MOVABLE_SLOW18 1 "Movable" 0 "Not_Movable" ;
VAL_ 1344 CAN_TX_TRACK_MOVABLE_SLOW17 1 "Movable" 0 "Not_Movable" ;
VAL_ 1344 CAN_TX_TRACK_MOVABLE_SLOW16 1 "Movable" 0 "Not_Movable" ;
VAL_ 1344 CAN_TX_TRACK_MOVABLE_SLOW15 1 "Movable" 0 "Not_Movable" ;
VAL_ 1344 CAN_TX_TRACK_MOVING21 1 "Moving" 0 "Stationary" ;
VAL_ 1344 CAN_TX_TRACK_MOVING20 1 "Moving" 0 "Stationary" ;
VAL_ 1344 CAN_TX_TRACK_MOVING19 1 "Moving" 0 "Stationary" ;
VAL_ 1344 CAN_TX_TRACK_MOVING18 1 "Moving" 0 "Stationary" ;
VAL_ 1344 CAN_TX_TRACK_MOVING17 1 "Moving" 0 "Stationary" ;
VAL_ 1344 CAN_TX_TRACK_MOVING16 1 "Moving" 0 "Stationary" ;
VAL_ 1344 CAN_TX_TRACK_MOVING15 1 "Moving" 0 "Stationary" ;
VAL_ 1344 CAN_TX_TRACK_MOVABLE_FAST21 1 "Movable" 0 "Not_Movable" ;
VAL_ 1344 CAN_TX_TRACK_MOVABLE_FAST20 1 "Movable" 0 "Not_Movable" ;
VAL_ 1344 CAN_TX_TRACK_MOVABLE_FAST19 1 "Movable" 0 "Not_Movable" ;
VAL_ 1344 CAN_TX_TRACK_MOVABLE_FAST18 1 "Movable" 0 "Not_Movable" ;
VAL_ 1344 CAN_TX_TRACK_MOVABLE_FAST17 1 "Movable" 0 "Not_Movable" ;
VAL_ 1344 CAN_TX_TRACK_MOVABLE_FAST16 1 "Movable" 0 "Not_Movable" ;
VAL_ 1344 CAN_TX_TRACK_MOVABLE_FAST15 1 "Movable" 0 "Not_Movable" ;
VAL_ 1344 CAN_TX_TRACK_MOVABLE_SLOW14 1 "Movable" 0 "Not_Movable" ;
VAL_ 1344 CAN_TX_TRACK_MOVABLE_SLOW13 1 "Movable" 0 "Not_Movable" ;
VAL_ 1344 CAN_TX_TRACK_MOVABLE_SLOW12 1 "Movable" 0 "Not_Movable" ;
VAL_ 1344 CAN_TX_TRACK_MOVABLE_SLOW11 1 "Movable" 0 "Not_Movable" ;
VAL_ 1344 CAN_TX_TRACK_MOVABLE_SLOW10 1 "Movable" 0 "Not_Movable" ;
VAL_ 1344 CAN_TX_TRACK_MOVABLE_SLOW09 1 "Movable" 0 "Not_Movable" ;
VAL_ 1344 CAN_TX_TRACK_MOVABLE_SLOW08 1 "Movable" 0 "Not_Movable" ;
VAL_ 1344 CAN_TX_TRACK_MOVING14 1 "Moving" 0 "Stationary" ;
VAL_ 1344 CAN_TX_TRACK_MOVING13 1 "Moving" 0 "Stationary" ;
VAL_ 1344 CAN_TX_TRACK_MOVING12 1 "Moving" 0 "Stationary" ;
VAL_ 1344 CAN_TX_TRACK_MOVING11 1 "Moving" 0 "Stationary" ;
VAL_ 1344 CAN_TX_TRACK_MOVING10 1 "Moving" 0 "Stationary" ;
VAL_ 1344 CAN_TX_TRACK_MOVING09 1 "Moving" 0 "Stationary" ;
VAL_ 1344 CAN_TX_TRACK_MOVING08 1 "Moving" 0 "Stationary" ;
VAL_ 1344 CAN_TX_TRACK_MOVABLE_FAST14 1 "Movable" 0 "Not_Movable" ;
VAL_ 1344 CAN_TX_TRACK_MOVABLE_FAST13 1 "Movable" 0 "Not_Movable" ;
VAL_ 1344 CAN_TX_TRACK_MOVABLE_FAST12 1 "Movable" 0 "Not_Movable" ;
VAL_ 1344 CAN_TX_TRACK_MOVABLE_FAST11 1 "Movable" 0 "Not_Movable" ;
VAL_ 1344 CAN_TX_TRACK_MOVABLE_FAST10 1 "Movable" 0 "Not_Movable" ;
VAL_ 1344 CAN_TX_TRACK_MOVABLE_FAST09 1 "Movable" 0 "Not_Movable" ;
VAL_ 1344 CAN_TX_TRACK_MOVABLE_FAST08 1 "Movable" 0 "Not_Movable" ;
VAL_ 1344 CAN_TX_TRACK_MOVING07 1 "Moving" 0 "Stationary" ;
VAL_ 1344 CAN_TX_TRACK_MOVING06 1 "Moving" 0 "Stationary" ;
VAL_ 1344 CAN_TX_TRACK_MOVING05 1 "Moving" 0 "Stationary" ;
VAL_ 1344 CAN_TX_TRACK_MOVING04 1 "Moving" 0 "Stationary" ;
VAL_ 1344 CAN_TX_TRACK_MOVING03 1 "Moving" 0 "Stationary" ;
VAL_ 1344 CAN_TX_TRACK_MOVING02 1 "Moving" 0 "Stationary" ;
VAL_ 1344 CAN_TX_TRACK_MOVING01 1 "Moving" 0 "Stationary" ;
VAL_ 1344 CAN_TX_TRACK_MOVABLE_SLOW07 1 "Movable" 0 "Not_Movable" ;
VAL_ 1344 CAN_TX_TRACK_MOVABLE_SLOW06 1 "Movable" 0 "Not_Movable" ;
VAL_ 1344 CAN_TX_TRACK_MOVABLE_SLOW05 1 "Movable" 0 "Not_Movable" ;
VAL_ 1344 CAN_TX_TRACK_MOVABLE_SLOW04 1 "Movable" 0 "Not_Movable" ;
VAL_ 1344 CAN_TX_TRACK_MOVABLE_SLOW03 1 "Movable" 0 "Not_Movable" ;
VAL_ 1344 CAN_TX_TRACK_MOVABLE_SLOW02 1 "Movable" 0 "Not_Movable" ;
VAL_ 1344 CAN_TX_TRACK_MOVABLE_SLOW01 1 "Movable" 0 "Not_Movable" ;
VAL_ 1344 CAN_TX_TRACK_MOVABLE_FAST07 1 "Movable" 0 "Not_Movable" ;
VAL_ 1344 CAN_TX_TRACK_MOVABLE_FAST06 1 "Movable" 0 "Not_Movable" ;
VAL_ 1344 CAN_TX_TRACK_MOVABLE_FAST05 1 "Movable" 0 "Not_Movable" ;
VAL_ 1344 CAN_TX_TRACK_MOVABLE_FAST04 1 "Movable" 0 "Not_Movable" ;
VAL_ 1344 CAN_TX_TRACK_MOVABLE_FAST03 1 "Movable" 0 "Not_Movable" ;
VAL_ 1344 CAN_TX_TRACK_MOVABLE_FAST02 1 "Movable" 0 "Not_Movable" ;
VAL_ 1344 CAN_TX_TRACK_MOVABLE_FAST01 1 "Movable" 0 "Not_Movable" ;
VAL_ 1251 CAN_TX_TRUCK_TARGET_DET 1 "Detected" 0 "Not_Detected" ;
VAL_ 1251 CAN_TX_LR_ONLY_GRATING_LOBE_DET 1 "Detected" 0 "Not_Detected" ;
VAL_ 1251 CAN_TX_SIDELOBE_BLOCKAGE 1 "On" 0 "Off" ;
VAL_ 1251 CAN_TX_PARTIAL_BLOCKAGE 1 "Blocked" 0 "Not Blocked" ;
VAL_ 1251 CAN_TX_MR_LR_MODE 3 "Output all medium-range and long" 2 "Output only long-range tracks" 1 "Output only medium-range tracks" 0 "Reserved" ;
VAL_ 1280 CAN_TX_TRACK_GROUPING_CHANGED 1 "GroupingChanged" 0 "GroupingUnchanged" ;
VAL_ 1280 CAN_TX_TRACK_ONCOMING 1 "Oncoming" 0 "NotOncoming" ;
VAL_ 1280 CAN_TX_TRACK_BRIDGE_OBJECT 1 "Bridge" 0 "Not_Bridge" ;
VAL_ 1280 CAN_TX_TRACK_STATUS 7 "New_Coasted_Target" 6 "Invalid_Coasted_Target" 5 "Merged_Target" 4 "Coasted_Target" 3 "Updated_Target" 2 "New_Updated_Target" 1 "New_Target" 0 "No_Target" ;
VAL_ 1280 CAN_TX_TRACK_MED_RANGE_MODE 3 "Both_MR_LR_Update" 2 "LR_Update_Only" 1 "MR_Update_Only" 0 "No_MR_LR_Update" ;
VAL_ 1249 CAN_TX_RAW_DATA_MODE 1 "Raw" 0 "Filtered" ;
VAL_ 1249 CAN_TX_RANGE_PERF_ERROR 1 "Blocked" 0 "Not Blocked" ;
VAL_ 1249 CAN_TX_OVERHEAT_ERROR 1 "OverTemp" 0 "Not OverTemp" ;
VAL_ 1249 CAN_TX_INTERNAL_ERROR 1 "Failed" 0 "Not Failed" ;
VAL_ 1249 CAN_TX_GROUPING_MODE 3 "Group_Moving_Stationary" 2 "Group_Stationary_Only" 1 "Group_Moving_Only" 0 "No_Grouping" ;
VAL_ 1249 CAN_TX_XCVR_OPERATIONAL 1 "On" 0 "Off" ;
VAL_ 1265 CAN_RX_MR_ONLY_TRANSMIT 1 "On" 0 "Off" ;
VAL_ 1265 CAN_RX_LR_ONLY_TRANSMIT 1 "On" 0 "Off" ;
VAL_ 1265 CAN_RX_CLEAR_FAULTS 1 "On" 0 "Off" ;
VAL_ 1265 CAN_RX_USE_ANGLE_MISALIGNMENT 1 "On" 0 "Off" ;
VAL_ 1265 CAN_RX_TURN_SIGNAL_STATUS 3 "Invalid_3" 2 "Right" 1 "Left" 0 "Off" ;
VAL_ 1265 CAN_RX_BLOCKAGE_DISABLE 1 "Disabled" 0 "Enabled" ;
VAL_ 1265 CAN_RX_VEHICLE_SPEED_VALIDITY 1 "Valid" 0 "Invalid" ;
VAL_ 1265 CAN_RX_MMR_UPSIDE_DOWN 1 "Upside_Down" 0 "Right_Side_Up" ;
VAL_ 1265 CAN_RX_WIPER_STATUS 1 "On" 0 "Off" ;
VAL_ 1265 CAN_RX_RADAR_CMD_RADIATE 1 "On" 0 "Off" ;
VAL_ 1265 CAN_RX_GROUPING_MODE 3 "Group_Moving_Stationary" 2 "Group_Stationary_Only" 1 "Group_Moving_Only" 0 "No_Grouping" ;
VAL_ 1264 CAN_RX_STEERING_ANGLE_VALIDITY 1 "Valid" 0 "Invalid" ;
VAL_ 1264 CAN_RX_STEERING_ANGLE_SIGN 1 "Clockwise" 0 "Counterclockwise" ;
VAL_ 1264 CAN_RX_STEERING_ANGLE_RATE_SIGN 1 "Clockwise" 0 "Counterclockwise" ;
VAL_ 1264 CAN_RX_YAW_RATE_VALIDITY 1 "Valid" 0 "Invalid" ;
VAL_ 1264 CAN_RX_VEHICLE_SPEED_DIRECTION 1 "Reverse" 0 "Forward" ;
SIG_VALTYPE_ 276 cpt7_longAcc : 2;
SIG_VALTYPE_ 275 nmea_heading : 2;
SIG_VALTYPE_ 274 nmea_speed : 2;
SIG_VALTYPE_ 273 nmea_longitude : 2;
SIG_VALTYPE_ 272 nmea_latitude : 2;
SIG_VALTYPE_ 262 cpt7_yawrate : 2;
SIG_VALTYPE_ 261 cpt7_azimuth : 2;
SIG_VALTYPE_ 260 cpt7_heading : 1;
SIG_VALTYPE_ 259 cpt7_easting : 2;
SIG_VALTYPE_ 258 cpt7_northing : 2;
SIG_VALTYPE_ 257 cpt7_longitude : 2;
SIG_VALTYPE_ 256 cpt7_latitude : 2;
